VERSION "0.0.1"

NS_ :

BS_:

BU_: TCU BRK ESP MCU RDD GP TMS GW KPD1 RDE FNR ECU KPD2 ATSGO ACU IMU1 IMU2 IMU3 IMU4 IMU5 AGW PMI HDOQS EGOQS OBC EEC CBSW EJRH EJLH EPDLT EPDL2 EPDLR EPDLA TRBDZ ECU1 CLST LC510 EGDL JS SMB KPAC ACCU Audio TGU RDRR RDLH RDRH AVM CHMSL CTC SMK MC3D EVC MCU2

BO_ 2566893620 SMK_SMKC: 9 SMK
 SG_ SmkId : 35|32@1+ (1,0) [0|999999999] "" Vector__XXX
 SG_ SoftwareVer : 24|8@1+ (0.01,0) [0|255] "Ver" Vector__XXX
 SG_ FobImmobilizerWrn : 22|2@1+ (1,0) [0|3] "" Vector__XXX
 SG_ FobLowBatWrn : 20|2@1+ (1,0) [0|3] "" Vector__XXX
 SG_ NoDttFobInsideCabinWrn : 18|2@1+ (1,0) [0|3] "" Vector__XXX
 SG_ FobRgstId : 14|4@1+ (1,0) [0|15] "EA" Vector__XXX
 SG_ FobRgstFdbk : 12|2@1+ (1,0) [0|3] "" Vector__XXX
 SG_ PreheatSt : 10|2@1+ (1,0) [0|3] "" Vector__XXX
 SG_ AppLmpSt : 8|2@1+ (1,0) [0|3] "" Vector__XXX
 SG_ VentilationTmp : 4|4@1+ (1,0) [0|15] "�C" Vector__XXX
 SG_ VentilationSt : 2|2@1+ (1,0) [0|3] "" Vector__XXX
 SG_ DoorLckSt : 0|2@1+ (1,0) [0|3] "" Vector__XXX

BO_ 2566893876 SMK_SMKFOB: 8 SMK

BO_ 2566894154 TMS_TMSSMKD: 8 TMS

BO_ 2566894388 SMK_SMKI: 9 SMK
 SG_ DeicerSt : 44|2@1+ (1,0) [0|3] "" Vector__XXX
 SG_ ForcedEgStopCmd : 42|2@1+ (1,0) [0|3] "" Vector__XXX
 SG_ RmRunningSt : 40|2@1+ (1,0) [0|3] "" Vector__XXX
 SG_ MaintenanceDoorSt : 38|2@1+ (1,0) [0|3] "" Vector__XXX
 SG_ CabinDoorSt : 36|2@1+ (1,0) [0|3] "" Vector__XXX
 SG_ FobBatSt : 28|8@1+ (0.1,0) [0|25] "V" Vector__XXX
 SG_ MchTonage : 8|16@1+ (0.1,0) [0|6502.3] "" Vector__XXX
 SG_ MchModel : 48|8@1+ (1,0) [0|255] "" Vector__XXX
 SG_ FobDtt : 2|1@1+ (1,0) [0|1] "" Vector__XXX
 SG_ KeyStChange : 0|2@1+ (1,0) [0|3] "" Vector__XXX

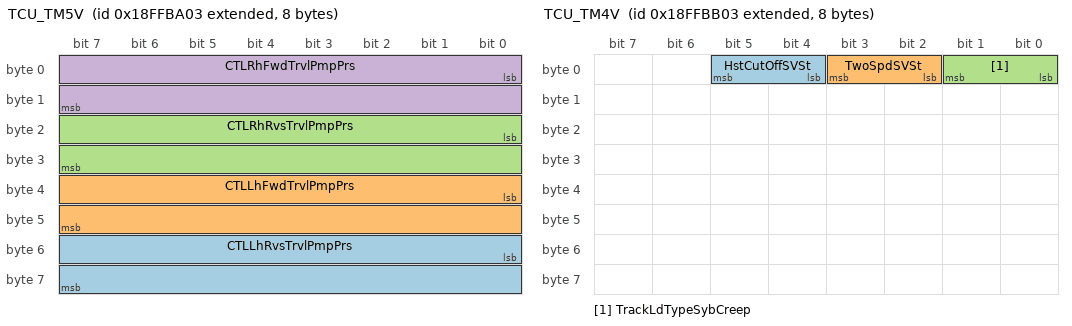
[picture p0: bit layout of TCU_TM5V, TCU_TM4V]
BO_ 2566896131 TCU_TM5V: 8 TCU
 SG_ CTLLhRvsTrvlPmpPrs : 48|16@1+ (0.0625,0) [0|500] "bar" Vector__XXX
 SG_ CTLLhFwdTrvlPmpPrs : 32|16@1+ (0.0625,0) [0|500] "bar" Vector__XXX
 SG_ CTLRhRvsTrvlPmpPrs : 16|16@1+ (0.0625,0) [0|500] "bar" Vector__XXX
 SG_ CTLRhFwdTrvlPmpPrs : 0|16@1+ (0.0625,0) [0|500] "bar" Vector__XXX

BO_ 2566896387 TCU_TM4V: 8 TCU
 SG_ HstCutOffSVSt : 4|2@1+ (1,0) [0|3] "" Vector__XXX
 SG_ TwoSpdSVSt : 2|2@1+ (1,0) [0|3] "" Vector__XXX
 SG_ TrackLdTypeSybCreep : 0|2@1+ (1,0) [0|3] "" Vector__XXX

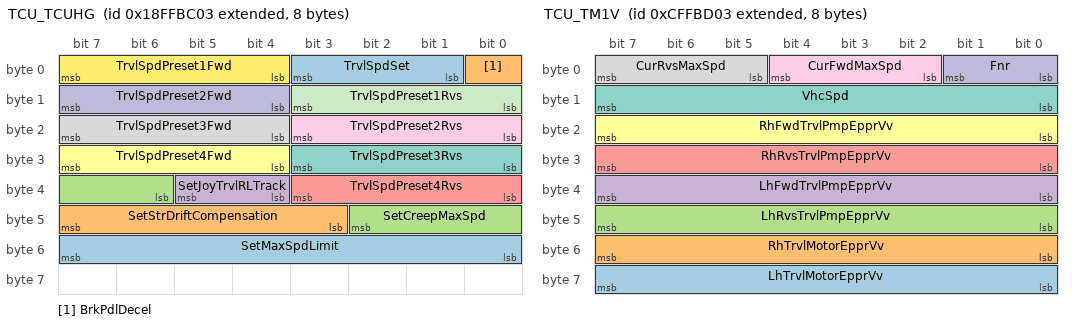
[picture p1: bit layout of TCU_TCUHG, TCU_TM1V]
BO_ 2566896643 TCU_TCUHG: 8 TCU
 SG_ SetMaxSpdLimit : 48|8@1+ (1,0) [0|250] "" Vector__XXX
 SG_ SetStrDriftCompensation : 43|5@1+ (1,0) [0|31] "" Vector__XXX
 SG_ SetCreepMaxSpd : 38|5@1+ (1,0) [0|31] "" Vector__XXX
 SG_ SetJoyTrvlRLTrack : 36|2@1+ (1,0) [0|3] "" Vector__XXX
 SG_ TrvlSpdPreset4Rvs : 32|4@1+ (1,0) [0|15] "" Vector__XXX
 SG_ TrvlSpdPreset4Fwd : 28|4@1+ (1,0) [0|15] "" Vector__XXX
 SG_ TrvlSpdPreset3Rvs : 24|4@1+ (1,0) [0|15] "" Vector__XXX
 SG_ TrvlSpdPreset3Fwd : 20|4@1+ (1,0) [0|15] "" Vector__XXX
 SG_ TrvlSpdPreset2Rvs : 16|4@1+ (1,0) [0|15] "" Vector__XXX
 SG_ TrvlSpdPreset2Fwd : 12|4@1+ (1,0) [0|15] "" Vector__XXX
 SG_ TrvlSpdPreset1Rvs : 8|4@1+ (1,0) [0|15] "" Vector__XXX
 SG_ TrvlSpdPreset1Fwd : 4|4@1+ (1,0) [0|15] "" Vector__XXX
 SG_ TrvlSpdSet : 1|3@1+ (1,0) [0|7] "" Vector__XXX
 SG_ BrkPdlDecel : 0|1@1+ (1,0) [0|1] "" Vector__XXX

BO_ 2365570307 TCU_TM1V: 8 TCU
 SG_ LhTrvlMotorEpprVv : 56|8@1+ (5,0) [0|1250] "mA" Vector__XXX
 SG_ RhTrvlMotorEpprVv : 48|8@1+ (5,0) [0|1250] "mA" Vector__XXX
 SG_ LhRvsTrvlPmpEpprVv : 40|8@1+ (5,0) [0|1250] "mA" Vector__XXX
 SG_ LhFwdTrvlPmpEpprVv : 32|8@1+ (5,0) [0|1250] "mA" Vector__XXX
 SG_ RhRvsTrvlPmpEpprVv : 24|8@1+ (5,0) [0|1250] "mA" Vector__XXX
 SG_ RhFwdTrvlPmpEpprVv : 16|8@1+ (5,0) [0|1250] "mA" Vector__XXX
 SG_ VhcSpd : 8|8@1+ (0.125,0) [0|31.25] "km/h" Vector__XXX
 SG_ CurRvsMaxSpd : 5|3@1+ (1,0) [0|7] "" Vector__XXX
 SG_ CurFwdMaxSpd : 2|3@1+ (1,0) [0|7] "" Vector__XXX
 SG_ Fnr : 0|2@1+ (1,0) [0|3] "" Vector__XXX

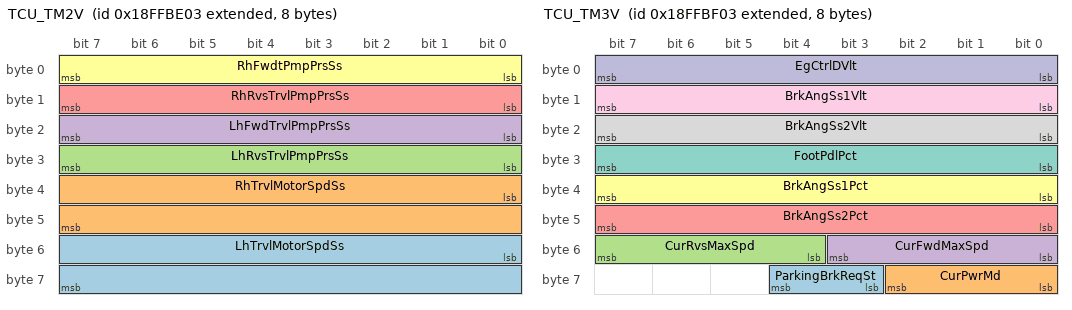
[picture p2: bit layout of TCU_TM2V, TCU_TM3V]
BO_ 2566897155 TCU_TM2V: 8 TCU
 SG_ LhTrvlMotorSpdSs : 48|16@1+ (0.0078125,0) [0|501.9921875] "Hz" Vector__XXX
 SG_ RhTrvlMotorSpdSs : 32|16@1+ (0.0078125,0) [0|501.9921875] "Hz" Vector__XXX
 SG_ LhRvsTrvlPmpPrsSs : 24|8@1+ (0.025,0) [0|6.25] "V" Vector__XXX
 SG_ LhFwdTrvlPmpPrsSs : 16|8@1+ (0.025,0) [0|6.25] "V" Vector__XXX
 SG_ RhRvsTrvlPmpPrsSs : 8|8@1+ (0.025,0) [0|6.25] "V" Vector__XXX
 SG_ RhFwdtPmpPrsSs : 0|8@1+ (0.025,0) [0|6.25] "V" Vector__XXX

BO_ 2566897411 TCU_TM3V: 8 TCU
 SG_ ParkingBrkReqSt : 59|2@1+ (1,0) [0|3] "" Vector__XXX
 SG_ CurPwrMd : 56|3@1+ (1,0) [0|7] "" Vector__XXX
 SG_ CurRvsMaxSpd : 52|4@1+ (1,0) [0|15] "" Vector__XXX
 SG_ CurFwdMaxSpd : 48|4@1+ (1,0) [0|15] "" Vector__XXX
 SG_ BrkAngSs2Pct : 40|8@1+ (0.4,0) [0|100] "%" Vector__XXX
 SG_ BrkAngSs1Pct : 32|8@1+ (0.4,0) [0|100] "%" Vector__XXX
 SG_ FootPdlPct : 24|8@1+ (0.4,0) [0|100] "%" Vector__XXX
 SG_ BrkAngSs2Vlt : 16|8@1+ (0.025,0) [0|6.25] "V" Vector__XXX
 SG_ BrkAngSs1Vlt : 8|8@1+ (0.025,0) [0|6.25] "V" Vector__XXX
 SG_ EgCtrlDVlt : 0|8@1+ (0.025,0) [0|6.25] "V" Vector__XXX

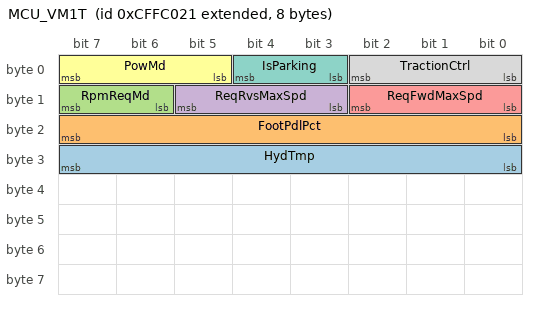
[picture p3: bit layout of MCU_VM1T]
BO_ 2365571105 MCU_VM1T: 8 MCU
 SG_ HydTmp : 24|8@1+ (1,-40) [-40|210] "�C" Vector__XXX
 SG_ FootPdlPct : 16|8@1+ (0.4,0) [0|100] "%" Vector__XXX
 SG_ RpmReqMd : 14|2@1+ (1,0) [0|3] "" Vector__XXX
 SG_ ReqRvsMaxSpd : 11|3@1+ (1,0) [0|7] "" Vector__XXX
 SG_ ReqFwdMaxSpd : 8|3@1+ (1,0) [0|7] "" Vector__XXX
 SG_ PowMd : 5|3@1+ (1,0) [0|7] "" Vector__XXX
 SG_ IsParking : 3|2@1+ (1,0) [0|3] "" Vector__XXX
 SG_ TractionCtrl : 0|3@1+ (1,0) [0|7] "" Vector__XXX

BO_ 2365571361 MCU_VM2T: 8 MCU

BO_ 2365572608 ECU_VGTPosCmd: 8 ECU
 SG_ VgtCmdSt : 16|8@1+ (1,0) [0|26] "" Vector__XXX
 SG_ VgtNzPos : 0|16@1+ (0.1,0) [0|100] "" Vector__XXX

BO_ 2566901763 TCU_HSDI: 250 TCU
 SG_ RandomVal : 0|16@1+ (1,0) [0|65535] "" Vector__XXX

BO_ 2566901793 MCU_HSDI: 250 MCU
 SG_ RandomVal : 0|16@1+ (1,0) [0|65535] "" Vector__XXX

BO_ 2566901936 MC3D_HSDI: 250 MC3D
 SG_ RandomVal : 0|16@1+ (1,0) [0|65535] "" Vector__XXX

BO_ 2566902049 MCU_FSDI: 94 MCU
 SG_ OptSetCdsRvsFanAutoPrd : 744|8@1+ (1,0) [0|250] "min" Vector__XXX
 SG_ OptSetTrailer : 742|1@1+ (1,0) [0|1] "" Vector__XXX
 SG_ OptSetEscortWrkLmp : 741|1@1+ (1,0) [0|1] "" Vector__XXX
 SG_ OptSetCdsRvsFanMd : 732|1@1+ (1,0) [0|1] "" Vector__XXX
 SG_ OptSetRttDir : 731|1@1+ (1,0) [0|1] "" Vector__XXX
 SG_ OptSetAdvLv : 730|1@1+ (1,0) [0|1] "" Vector__XXX
 SG_ OptSetGndSaw : 729|1@1+ (1,0) [0|1] "" Vector__XXX
 SG_ OptSetTpms : 728|1@1+ (1,0) [0|1] "" Vector__XXX
 SG_ OptSetAutoBrkrSens : 720|8@1+ (1,0) [0|255] "" Vector__XXX
 SG_ OptSetAntiBlankFire : 719|1@1+ (1,0) [0|1] "" Vector__XXX
 SG_ OptSetJoyBoom : 717|2@1+ (1,0) [0|3] "" Vector__XXX
 SG_ OptSetJoyTilt : 715|2@1+ (1,0) [0|3] "" Vector__XXX
 SG_ OptSetRvsFanDurTm : 709|6@1+ (1,0) [0|63] "" Vector__XXX
 SG_ OptSetHhFw : 708|1@1+ (1,0) [0|1] "" Vector__XXX
 SG_ OptSet3DMgMc3rd : 704|4@1+ (1,0) [0|15] "" Vector__XXX
 SG_ OptSetRrCabLmp : 703|1@1+ (1,0) [0|1] "" Vector__XXX
 SG_ OptSetDzMc : 700|3@1+ (1,0) [0|7] "" Vector__XXX
 SG_ OptSetTrqCvtLckUp : 699|1@1+ (1,0) [0|1] "" Vector__XXX
 SG_ OptSetTwThmbWhlDir : 698|1@1+ (1,0) [0|1] "" Vector__XXX
 SG_ OptSetOptPdlType2 : 696|2@1+ (1,0) [0|3] "" Vector__XXX
 SG_ OptSetMaxTrvlSpd : 688|8@1+ (1,0) [0|250] "km/h" Vector__XXX
 SG_ OptSetRollSlope : 672|16@1+ (1,-125) [-125|125] "%" Vector__XXX
 SG_ OptSetDaac : 671|1@1+ (1,0) [0|1] "" Vector__XXX
 SG_ OptSetRvsLmpFuncAct : 670|1@1+ (1,0) [0|1] "" Vector__XXX
 SG_ OptSetBladeAngSens : 668|2@1+ (1,0) [0|3] "" Vector__XXX
 SG_ OptSetRaiseDnSens : 666|2@1+ (1,0) [0|3] "" Vector__XXX
 SG_ OptSetBladeTiltSens : 664|2@1+ (1,0) [0|3] "" Vector__XXX
 SG_ OptSetPchSlope : 648|16@1+ (0.01,-321.27) [-321.27|321.28] "%" Vector__XXX
 SG_ OptSetMrrHt : 647|1@1+ (1,0) [0|1] "" Vector__XXX
 SG_ OptSetQckCoolMd : 646|1@1+ (1,0) [0|1] "" Vector__XXX
 SG_ RttOptSet : 644|2@1+ (1,0) [0|3] "" Vector__XXX
 SG_ OptSetTrvlStrgtPdl : 643|1@1+ (1,0) [0|1] "" Vector__XXX
 SG_ OptSetJoyType : 640|3@1+ (1,0) [0|7] "" Vector__XXX
 SG_ OptSetAttCtrl : 638|2@1+ (1,0) [0|3] "" Vector__XXX
 SG_ OptSetTiltRttType : 635|3@1+ (1,0) [0|7] "" Vector__XXX
 SG_ OptSetArtiBoom : 634|1@1+ (1,0) [0|1] "" Vector__XXX
 SG_ OptSetDzBlade : 633|1@1+ (1,0) [0|1] "" Vector__XXX
 SG_ OptSetHhLift : 632|1@1+ (1,0) [0|1] "" Vector__XXX
 SG_ OptSetJoyPtnChange : 629|3@1+ (1,0) [0|7] "" Vector__XXX
 SG_ OptSetTrqCvtLookUp : 628|1@1+ (1,0) [0|1] "" Vector__XXX
 SG_ OptSetDhlAuto : 627|1@1+ (1,0) [0|1] "" Vector__XXX
 SG_ OptSet3DMG : 626|1@1+ (1,0) [0|1] "" Vector__XXX
 SG_ OptSetTrvlSwgAlm : 624|2@1+ (1,0) [0|3] "" Vector__XXX
 SG_ OptSetPrsCtrl : 600|1@1+ (1,0) [0|1] "" Vector__XXX
 SG_ OptSetRollOvr : 599|1@1+ (1,0) [0|1] "" Vector__XXX
 SG_ OptSet4WhlStr : 598|1@1+ (1,0) [0|1] "" Vector__XXX
 SG_ OptSetSpool4 : 597|1@1+ (1,0) [0|1] "" Vector__XXX
 SG_ OptSetConstFw : 596|1@1+ (1,0) [0|1] "" Vector__XXX
 SG_ OptSetConstFwStep : 592|4@1+ (1,0) [0|15] "" Vector__XXX
 SG_ OptSetLisRvsOprSpd : 584|8@1+ (1,0) [0|250] "km/h" Vector__XXX
 SG_ OptSetFrCabLmp : 583|1@1+ (1,0) [0|1] "" Vector__XXX
 SG_ OptSetOutRr : 582|1@1+ (1,0) [0|1] "" Vector__XXX
 SG_ OptSetOutRlRrDz : 581|1@1+ (1,0) [0|1] "" Vector__XXX
 SG_ OptSetOutFr : 580|1@1+ (1,0) [0|1] "" Vector__XXX
 SG_ OptSetOutFlFrDz : 579|1@1+ (1,0) [0|1] "" Vector__XXX
 SG_ OptSetJoyStr : 578|1@1+ (1,0) [0|1] "" Vector__XXX
 SG_ OptSetRvsTrvlSpdLmt : 577|1@1+ (1,0) [0|1] "" Vector__XXX
 SG_ OptSetEmcvBoomDnImpactPrevent : 576|1@1+ (1,0) [0|1] "" Vector__XXX
 SG_ OptSetEmcvBoomUpImpactPrevent : 575|1@1+ (1,0) [0|1] "" Vector__XXX
 SG_ OptSetEmcvBckDumpImpactPrevent : 574|1@1+ (1,0) [0|1] "" Vector__XXX
 SG_ OptSetEmcvBckCrowdImpactPrevent : 573|1@1+ (1,0) [0|1] "" Vector__XXX
 SG_ OptSetEmcvBckSens : 572|1@1+ (1,0) [0|1] "" Vector__XXX
 SG_ OptSetEmcvBoomSens : 571|1@1+ (1,0) [0|1] "" Vector__XXX
 SG_ OptSetEstrJoySens : 569|2@1+ (1,0) [0|3] "" Vector__XXX
 SG_ OptSetWrkLis : 568|1@1+ (1,0) [0|1] "" Vector__XXX
 SG_ OptSetLcInVal : 552|16@1+ (0.1,0) [0|6425.5] "mm" Vector__XXX
 SG_ OptSetR2InVal : 536|16@1+ (0.1,0) [0|6425.5] "mm" Vector__XXX
 SG_ OptSetR1InVal : 520|16@1+ (0.1,0) [0|6425.5] "mm" Vector__XXX
 SG_ OptSetBckWghInVlue : 504|16@1+ (0.1,0) [0|6425.5] "kg" Vector__XXX
 SG_ OptSetBoomWghInVal : 488|16@1+ (0.1,0) [0|6425.5] "kg" Vector__XXX
 SG_ OptSetMaxCritWghVal : 472|16@1+ (0.5,0) [0|32127.5] "kg" Vector__XXX
 SG_ OptSetHalfCritWghVal : 456|16@1+ (0.5,0) [0|32127.5] "kg" Vector__XXX
 SG_ OptSetElecStr : 455|1@1+ (1,0) [0|1] "" Vector__XXX
 SG_ OptSetRvsFan : 454|1@1+ (1,0) [0|1] "" Vector__XXX
 SG_ OptSetRcw : 453|1@1+ (1,0) [0|1] "" Vector__XXX
 SG_ OptSetQckCoupler : 452|1@1+ (1,0) [0|1] "" Vector__XXX
 SG_ OptSetTrvlOrSwgAlm : 451|1@1+ (1,0) [0|1] "" Vector__XXX
 SG_ OptSetSmk : 450|1@1+ (1,0) [0|1] "" Vector__XXX
 SG_ OptSetOwd : 449|1@1+ (1,0) [0|1] "" Vector__XXX
 SG_ OptSetMchNameInit : 448|1@1+ (1,0) [0|250] "" Vector__XXX
 SG_ OptSetEmvcPmcv : 447|1@1+ (1,0) [0|1] "" Vector__XXX
 SG_ OptSetAebReq : 446|1@1+ (1,0) [0|1] "" Vector__XXX
 SG_ OptSetRvsFanOn : 445|1@1+ (1,0) [0|1] "" Vector__XXX
 SG_ OptSetRvsFanMd : 444|1@1+ (1,0) [0|1] "" Vector__XXX
 SG_ OptSetWhg : 443|1@1+ (1,0) [0|1] "" Vector__XXX
 SG_ OptSetHydrostatCalbCmd : 442|1@1+ (1,0) [0|1] "" Vector__XXX
 SG_ OptSetClutchCalbCmd : 441|1@1+ (1,0) [0|1] "" Vector__XXX
 SG_ OptSetEmgMd : 440|1@1+ (1,0) [0|1] "" Vector__XXX
 SG_ OptSetCreepAct : 439|1@1+ (1,0) [0|1] "" Vector__XXX
 SG_ OptSetThmbWhl : 438|1@1+ (1,0) [0|1] "" Vector__XXX
 SG_ OptSetAxleOilCool : 437|1@1+ (1,0) [0|1] "" Vector__XXX
 SG_ OptSetAngSs : 434|3@1+ (1,0) [0|7] "" Vector__XXX
 SG_ OptSetBrkPdlCalb : 432|2@1+ (1,0) [0|3] "" Vector__XXX
 SG_ OptSetCreepGr : 424|8@1+ (1,0) [0|250] "" Vector__XXX
 SG_ OptSetLisOprSpd : 416|8@1+ (1,0) [0|250] "km/h" Vector__XXX
 SG_ OptSetRvsFanTm : 408|8@1+ (1,0) [0|250] "min" Vector__XXX
 SG_ OptSetLis : 407|1@1+ (1,0) [0|1] "" Vector__XXX
 SG_ OptSetEmgStr : 406|1@1+ (1,0) [0|1] "" Vector__XXX
 SG_ OptSetDhl : 405|1@1+ (1,0) [0|1] "" Vector__XXX
 SG_ OptSetFnr2LeverType : 403|2@1+ (1,0) [0|3] "" Vector__XXX
 SG_ OptSetTrmsLmtGr : 400|3@1+ (1,0) [0|7] "" Vector__XXX
 SG_ OptSetTransBck : 399|1@1+ (1,0) [0|1] "" Vector__XXX
 SG_ OptSetItgtFltBoom : 398|1@1+ (1,0) [0|1] "" Vector__XXX
 SG_ OptSetBeacon : 397|1@1+ (1,0) [0|1] "" Vector__XXX
 SG_ OptSetMultiFuncBtnSel : 393|4@1+ (1,0) [0|15] "" Vector__XXX
 SG_ OptSetAutoIdle : 392|1@1+ (1,0) [0|1] "" Vector__XXX
 SG_ MachineName : 304|88@1+ (1,0) [0|255] "" Vector__XXX
 SG_ AutoIdleTm : 288|16@1+ (1,0) [0|64255] "s" Vector__XXX
 SG_ BrkrOprTm : 272|16@1+ (1,0) [0|64255] "s" Vector__XXX
 SG_ OptSetAutoShutOffTm : 264|8@1+ (1,0) [0|250] "min" Vector__XXX
 SG_ OptSetAutoShutOff : 263|1@1+ (1,0) [0|1] "" Vector__XXX
 SG_ OptSetAutoShutOffCancel : 262|1@1+ (1,0) [0|1] "" Vector__XXX
 SG_ OptSetAutoIdleRpmTmp : 261|1@1+ (1,0) [0|1] "" Vector__XXX
 SG_ OptSetSpc : 260|1@1+ (1,0) [0|1] "" Vector__XXX
 SG_ OptSetVoiceWrnCmd : 259|1@1+ (1,0) [0|1] "" Vector__XXX
 SG_ OptSetBoomSwgUSe : 258|1@1+ (1,0) [0|1] "" Vector__XXX
 SG_ OptSetTrvl2PmpCmbRls : 257|1@1+ (1,0) [0|1] "" Vector__XXX
 SG_ OptSetTrvl1PmpUse : 256|1@1+ (1,0) [0|1] "" Vector__XXX
 SG_ OptSetTrmsMaxSpdLmtChk : 255|1@1+ (1,0) [0|1] "" Vector__XXX
 SG_ OptSetHhAlt : 254|1@1+ (1,0) [0|1] "" Vector__XXX
 SG_ OptSetRipperOpt : 253|1@1+ (1,0) [0|1] "" Vector__XXX
 SG_ OptSetRttOpt : 252|1@1+ (1,0) [0|1] "" Vector__XXX
 SG_ OptSetJoyThmbWhlRtt : 250|2@1+ (1,0) [0|3] "" Vector__XXX
 SG_ OptSetJoyThmbWhlTw : 248|2@1+ (1,0) [0|3] "" Vector__XXX
 SG_ OptSetTw : 246|2@1+ (1,0) [0|3] "" Vector__XXX
 SG_ OptSetOptPdl : 245|1@1+ (1,0) [0|1] "" Vector__XXX
 SG_ OptSetAttPdlJoySel : 243|2@1+ (1,0) [0|3] "" Vector__XXX
 SG_ OptSet2Pmp : 242|1@1+ (1,0) [0|1] "" Vector__XXX
 SG_ OptSetAttTw : 241|1@1+ (1,0) [0|1] "" Vector__XXX
 SG_ OptSetAttBrkr : 240|1@1+ (1,0) [0|1] "" Vector__XXX
 SG_ OptSetKeylessUse : 191|1@1+ (1,0) [0|1] "" Vector__XXX
 SG_ OptSetKeyless : 190|1@1+ (1,0) [0|1] "" Vector__XXX
 SG_ OptSetWiper : 189|1@1+ (1,0) [0|1] "" Vector__XXX
 SG_ OptSetTrvlMotOvrHtWrn : 188|1@1+ (1,0) [0|1] "" Vector__XXX
 SG_ OptSetFnrDefault : 187|1@1+ (1,0) [0|1] "" Vector__XXX
 SG_ OptSetFnrSel : 186|1@1+ (1,0) [0|1] "" Vector__XXX
 SG_ OptSetCanTypeCmbSw : 185|1@1+ (1,0) [0|1] "" Vector__XXX
 SG_ UserDtIdx : 176|8@1+ (1,0) [0|255] "" Vector__XXX
 SG_ VhcSerialNo : 120|56@1+ (1,0) [0|255] "" Vector__XXX
 SG_ OptSetAttWghFactor : 100|4@1+ (1,0) [0|15] "" Vector__XXX
 SG_ OptSetCanTypeFuelSs : 99|1@1+ (1,0) [0|1] "" Vector__XXX
 SG_ OptSetSubBrkLmp : 98|1@1+ (1,0) [0|1] "" Vector__XXX
 SG_ TiltRttMd : 97|1@1+ (1,0) [0|1] "" Vector__XXX
 SG_ USerLckUnlockSt : 96|1@1+ (1,0) [0|1] "" Vector__XXX
 SG_ UserPw : 64|32@1+ (1,0) [0|255] "" Vector__XXX
 SG_ OptWgh : 63|1@1+ (1,0) [0|1] "" Vector__XXX
 SG_ OptMC : 62|1@1+ (1,0) [0|1] "" Vector__XXX
 SG_ OptEgPostHtAct : 61|1@1+ (1,0) [0|1] "" Vector__XXX
 SG_ Opt2DMG : 60|1@1+ (1,0) [0|1] "" Vector__XXX
 SG_ AdminUse2 : 56|3@1+ (1,0) [0|7] "" Vector__XXX
 SG_ AdminUse1 : 48|3@1+ (1,0) [0|7] "" Vector__XXX
 SG_ AdminUse0 : 40|3@1+ (1,0) [0|7] "" Vector__XXX
 SG_ OwnerPw0UpTm : 33|2@1+ (1,0) [0|3] "" Vector__XXX
 SG_ OwnerPw0Use : 32|1@1+ (1,0) [0|1] "" Vector__XXX
 SG_ OwnerPw0 : 0|32@1+ (1,0) [0|255] "" Vector__XXX

BO_ 2566902305 MCU_FOUHI: 104 MCU
 SG_ PmpDrvAirCtrgHr : 800|32@1+ (1,0) [0|4294967295] "min" Vector__XXX
 SG_ PmpDrvOilHr : 768|32@1+ (1,0) [0|4294967295] "min" Vector__XXX
 SG_ HstFiltHr : 736|32@1+ (1,0) [0|4294967295] "min" Vector__XXX
 SG_ AxleOilFiltHr : 704|32@1+ (1,0) [0|4294967295] "min" Vector__XXX
 SG_ AtsSparkPlugHr : 672|32@1+ (1,0) [0|4294967295] "min" Vector__XXX
 SG_ EgCrkcaseBreatherElementHr : 640|32@1+ (1,0) [0|4294967295] "min" Vector__XXX
 SG_ AirCndFiltInHr : 608|32@1+ (1,0) [0|4294967295] "min" Vector__XXX
 SG_ AirCndFiltOutHr : 576|32@1+ (1,0) [0|4294967295] "min" Vector__XXX
 SG_ EgOilCtrCleanerFiltHr : 544|32@1+ (1,0) [0|4294967295] "min" Vector__XXX
 SG_ DefBreatherFiltHr : 512|32@1+ (1,0) [0|4294967295] "min" Vector__XXX
 SG_ DefFiltHr : 480|32@1+ (1,0) [0|4294967295] "min" Vector__XXX
 SG_ OilBathPrecleanerHr : 448|32@1+ (1,0) [0|4294967295] "min" Vector__XXX
 SG_ DefHr : 416|32@1+ (1,0) [0|4294967295] "min" Vector__XXX
 SG_ AxleOilHr : 384|32@1+ (1,0) [0|4294967295] "min" Vector__XXX
 SG_ TrmsOilFiltHr : 352|32@1+ (1,0) [0|4294967295] "min" Vector__XXX
 SG_ TrmsOilHr : 320|32@1+ (1,0) [0|4294967295] "min" Vector__XXX
 SG_ BreatherOilSepFiltHr : 288|32@1+ (1,0) [0|4294967295] "min" Vector__XXX
 SG_ DpfHr : 256|32@1+ (1,0) [0|4294967295] "min" Vector__XXX
 SG_ CoolHr : 224|32@1+ (1,0) [0|4294967295] "min" Vector__XXX
 SG_ HydOilHr : 192|32@1+ (1,0) [0|4294967295] "min" Vector__XXX
 SG_ EgOilHr : 160|32@1+ (1,0) [0|4294967295] "min" Vector__XXX
 SG_ PilotFiltHr : 128|32@1+ (1,0) [0|4294967295] "min" Vector__XXX
 SG_ RetFiltHr : 96|32@1+ (1,0) [0|4294967295] "min" Vector__XXX
 SG_ EgOilFiltHr : 64|32@1+ (1,0) [0|4294967295] "min" Vector__XXX
 SG_ AirCleanerHr : 32|32@1+ (1,0) [0|4294967295] "min" Vector__XXX
 SG_ FuleFiltHr : 0|32@1+ (1,0) [0|4294967295] "min" Vector__XXX

BO_ 2566902561 MCU_FOCPHI: 52 MCU
 SG_ PmpDrvAirCtrgPrd : 400|16@1+ (1,0) [0|64255] "h" Vector__XXX
 SG_ PmpDrvOilPrd : 384|16@1+ (1,0) [0|64255] "h" Vector__XXX
 SG_ HstFiltPrd : 368|16@1+ (1,0) [0|64255] "h" Vector__XXX
 SG_ AxleOilFiltPrd : 352|16@1+ (1,0) [0|64255] "h" Vector__XXX
 SG_ AtsSparkPlugPrd : 336|16@1+ (1,0) [0|64255] "h" Vector__XXX
 SG_ EgCrkcaseBreatherElementPrd : 320|16@1+ (1,0) [0|64255] "h" Vector__XXX
 SG_ AirCndFiltInPrd : 304|16@1+ (1,0) [0|64255] "h" Vector__XXX
 SG_ AirCndFiltOutPrd : 288|16@1+ (1,0) [0|64255] "h" Vector__XXX
 SG_ EgOilCtrCleanerFiltPrd : 272|16@1+ (1,0) [0|64255] "h" Vector__XXX
 SG_ DefBreatherFiltPrd : 256|16@1+ (1,0) [0|64255] "h" Vector__XXX
 SG_ DefFiltPrd : 240|16@1+ (1,0) [0|64255] "h" Vector__XXX
 SG_ OilBathPrecleanerPrd : 224|16@1+ (1,0) [0|64255] "h" Vector__XXX
 SG_ DefPrd : 208|16@1+ (1,0) [0|64255] "h" Vector__XXX
 SG_ AxleOilPrd : 192|16@1+ (1,0) [0|64255] "h" Vector__XXX
 SG_ TrmsOilFiltPrd : 176|16@1+ (1,0) [0|64255] "h" Vector__XXX
 SG_ TrmsOilPrd : 160|16@1+ (1,0) [0|64255] "h" Vector__XXX
 SG_ BreatherOilSepFiltPrd : 144|16@1+ (1,0) [0|64255] "h" Vector__XXX
 SG_ DpfPrd : 128|16@1+ (1,0) [0|64255] "h" Vector__XXX
 SG_ CoolPrd : 112|16@1+ (1,0) [0|64255] "h" Vector__XXX
 SG_ HydOilPrd : 96|16@1+ (1,0) [0|64255] "h" Vector__XXX
 SG_ EgOilPrd : 80|16@1+ (1,0) [0|64255] "h" Vector__XXX
 SG_ PilotFiltPrd : 64|16@1+ (1,0) [0|64255] "h" Vector__XXX
 SG_ RetFiltPrd : 48|16@1+ (1,0) [0|64255] "h" Vector__XXX
 SG_ EgOilFiltPrd : 32|16@1+ (1,0) [0|64255] "h" Vector__XXX
 SG_ AirCleanerPrd : 16|16@1+ (1,0) [0|64255] "h" Vector__XXX
 SG_ FuleFiltPrd : 0|16@1+ (1,0) [0|64255] "h" Vector__XXX

BO_ 2566902817 MCU_XASI: 136 MCU
 SG_ BladeFanPchSsVlt : 1072|16@1+ (0.001,0) [0|64.255] "V" Vector__XXX
 SG_ RamLckPrs : 1056|16@1+ (0.0625,0) [0|500] "bar" Vector__XXX
 SG_ TrailerDnPilotPrs : 1040|16@1+ (0.00390625,0) [0|50] "bar" Vector__XXX
 SG_ BoomHead2Prs : 1024|16@1+ (0.0625,0) [0|500] "bar" Vector__XXX
 SG_ ArmRodPrs : 1008|16@1+ (0.0625,0) [0|500] "bar" Vector__XXX
 SG_ ArmHEadPrs : 992|16@1+ (0.0625,0) [0|500] "bar" Vector__XXX
 SG_ BoodRodPrs : 976|16@1+ (0.0625,0) [0|500] "bar" Vector__XXX
 SG_ BoomHeadPrs : 960|16@1+ (0.0625,0) [0|500] "bar" Vector__XXX
 SG_ TpsVlt : 912|16@1+ (0.001,0) [0|64.255] "V" Vector__XXX
 SG_ PchAng : 896|16@1+ (1,0) [0|65535] "" Vector__XXX
 SG_ RoolAng : 880|16@1+ (1,0) [0|65535] "" Vector__XXX
 SG_ TmsSecVlt : 864|16@1+ (0.001,0) [0|64.255] "V" Vector__XXX
 SG_ VhcTrvlSpdSsFreq : 848|16@1+ (1,0) [0|65000] "Hz" Vector__XXX
 SG_ FlwCtrlLeverRh : 800|16@1+ (0.001,0) [0|64.255] "V" Vector__XXX
 SG_ FlwCtrlLeverLh : 784|16@1+ (0.001,0) [0|64.255] "V" Vector__XXX
 SG_ FlwCtrlAddLeverLh : 768|16@1+ (0.001,0) [0|64.255] "V" Vector__XXX
 SG_ BatVlt : 736|16@1+ (0.001,0) [0|64.255] "V" Vector__XXX
 SG_ AltVlt : 720|16@1+ (0.001,0) [0|64.255] "V" Vector__XXX
 SG_ HydOilTmp : 656|16@1+ (1,-40) [-40|210] "�C" Vector__XXX
 SG_ MecaCoolTmp : 640|16@1+ (1,-40) [-40|210] "�C" Vector__XXX
 SG_ GndSawDnSsPrs : 624|16@1+ (0.00390625,0) [0|50] "bar" Vector__XXX
 SG_ GndSawUpSsPrs : 608|16@1+ (0.00390625,0) [0|50] "bar" Vector__XXX
 SG_ WifSsVlt : 592|16@1+ (0.001,0) [0|64.255] "V" Vector__XXX
 SG_ FuelLv : 576|16@1+ (1,0) [0|250] "%" Vector__XXX
 SG_ FuelLvAddFuelTnk : 560|16@1+ (16,0) [0|4000] "kPa" Vector__XXX
 SG_ AcpSsPrs : 544|16@1+ (16,0) [0|4000] "kPa" Vector__XXX
 SG_ AccPdlVlt : 528|16@1+ (0.001,0) [0|64.255] "V" Vector__XXX
 SG_ EgCtrlDialVlt : 512|16@1+ (0.001,0) [0|64.255] "V" Vector__XXX
 SG_ LsPrs : 496|16@1+ (0.0625,0) [0|500] "Bar" Vector__XXX
 SG_ P3NegaconPrs : 480|16@1+ (0.0625,0) [0|500] "Bar" Vector__XXX
 SG_ RrNegaconPrs : 464|16@1+ (0.0625,0) [0|500] "Bar" Vector__XXX
 SG_ FrNegaconPrs : 448|16@1+ (0.0625,0) [0|500] "Bar" Vector__XXX
 SG_ PilotTrvlPtPrs : 432|16@1+ (0.0625,0) [0|50] "Bar" Vector__XXX
 SG_ PilotWrkPaPrs : 416|16@1+ (0.0625,0) [0|50] "Bar" Vector__XXX
 SG_ ArmLckPrs : 400|16@1+ (0.00390625,0) [0|50] "bar" Vector__XXX
 SG_ BckCrowdConfPrs : 384|16@1+ (0.00390625,0) [0|50] "bar" Vector__XXX
 SG_ ArmCrowdConfPrs : 368|16@1+ (0.00390625,0) [0|50] "bar" Vector__XXX
 SG_ BoomUpConfPrs : 352|16@1+ (0.00390625,0) [0|50] "bar" Vector__XXX
 SG_ Opt3Prs : 336|16@1+ (0.00390625,0) [0|50] "bar" Vector__XXX
 SG_ Opt2Prs : 320|16@1+ (0.00390625,0) [0|50] "bar" Vector__XXX
 SG_ Opt1Prs : 304|16@1+ (0.00390625,0) [0|50] "bar" Vector__XXX
 SG_ SwgPrs : 288|16@1+ (0.00390625,0) [0|50] "bar" Vector__XXX
 SG_ TrvlLhPrs : 272|16@1+ (0.00390625,0) [0|50] "bar" Vector__XXX
 SG_ TrvlRhPrs : 256|16@1+ (0.00390625,0) [0|50] "bar" Vector__XXX
 SG_ BckDumpPrs : 240|16@1+ (0.00390625,0) [0|50] "bar" Vector__XXX
 SG_ BckCrowdPrs : 224|16@1+ (0.00390625,0) [0|50] "bar" Vector__XXX
 SG_ ArmOutPrs : 208|16@1+ (0.00390625,0) [0|50] "bar" Vector__XXX
 SG_ ArmInPrs : 192|16@1+ (0.00390625,0) [0|50] "bar" Vector__XXX
 SG_ BoomDnPrs : 176|16@1+ (0.00390625,0) [0|50] "bar" Vector__XXX
 SG_ BoomUpPrs : 160|16@1+ (0.00390625,0) [0|50] "bar" Vector__XXX
 SG_ EmgStrPrs : 144|16@1+ (0.0625,0) [0|500] "bar" Vector__XXX
 SG_ Pmp3Ang : 128|16@1+ (0.001,0) [0|64.255] "V" Vector__XXX
 SG_ RRpmpAng : 112|16@1+ (0.001,0) [0|64.255] "V" Vector__XXX
 SG_ FrPmpAng : 96|16@1+ (0.001,0) [0|64.255] "V" Vector__XXX
 SG_ FuelPrs : 80|16@1+ (0.00390625,0) [0|50] "bar" Vector__XXX
 SG_ RcwStpVvPrs : 64|16@1+ (0.0625,0) [0|500] "bar" Vector__XXX
 SG_ Pmp3Prs : 48|16@1+ (0.0625,0) [0|500] "bar" Vector__XXX
 SG_ BoomCylPrs : 32|16@1+ (0.0625,0) [0|500] "bar" Vector__XXX
 SG_ RrPmpPrs : 16|16@1+ (0.0625,0) [0|500] "bar" Vector__XXX
 SG_ FrPmpPrs : 0|16@1+ (0.0625,0) [0|500] "bar" Vector__XXX

BO_ 2566903073 MCU_XAAI: 84 MCU
 SG_ VariBladeFanEvc : 656|16@1+ (1,0) [0|2000] "mA" Vector__XXX
 SG_ BoomSwgCcwEvc : 640|16@1+ (1,0) [0|2000] "mA" Vector__XXX
 SG_ BoomSwgCwEvc : 624|16@1+ (1,0) [0|2000] "mA" Vector__XXX
 SG_ TrvlPmpEvc : 608|16@1+ (1,0) [0|2000] "mA" Vector__XXX
 SG_ Pmp3Evc : 592|16@1+ (1,0) [0|2000] "mA" Vector__XXX
 SG_ DzDnEvc : 576|16@1+ (1,0) [0|2000] "mA" Vector__XXX
 SG_ DzUpEvc : 560|16@1+ (1,0) [0|2000] "mA" Vector__XXX
 SG_ ArtiBoomDnEvc : 544|16@1+ (1,0) [0|2000] "mA" Vector__XXX
 SG_ ArtiBoomUpEvc : 528|16@1+ (1,0) [0|2000] "mA" Vector__XXX
 SG_ SwgLhEvc : 512|16@1+ (1,0) [0|2000] "mA" Vector__XXX
 SG_ SwgRhEvc : 496|16@1+ (1,0) [0|2000] "mA" Vector__XXX
 SG_ TrvlLhRvsEvc : 480|16@1+ (1,0) [0|2000] "mA" Vector__XXX
 SG_ TrvlLhFwdEvc : 464|16@1+ (1,0) [0|2000] "mA" Vector__XXX
 SG_ TrvlRhRvsEvc : 448|16@1+ (1,0) [0|2000] "mA" Vector__XXX
 SG_ TrvlRhFwdEvc : 432|16@1+ (1,0) [0|2000] "mA" Vector__XXX
 SG_ BckDumpEvc : 416|16@1+ (1,0) [0|2000] "mA" Vector__XXX
 SG_ BckCrowdEvc : 400|16@1+ (1,0) [0|2000] "mA" Vector__XXX
 SG_ Arm2DumpEvc : 384|16@1+ (1,0) [0|2000] "mA" Vector__XXX
 SG_ Arm2CrowdEvc : 368|16@1+ (1,0) [0|2000] "mA" Vector__XXX
 SG_ Arm1DumpEvc : 352|16@1+ (1,0) [0|2000] "mA" Vector__XXX
 SG_ Arm1CrowdEvc : 336|16@1+ (1,0) [0|2000] "mA" Vector__XXX
 SG_ Boom2UpEvc : 320|16@1+ (1,0) [0|2000] "mA" Vector__XXX
 SG_ Boom1DnEvc : 304|16@1+ (1,0) [0|2000] "mA" Vector__XXX
 SG_ Boom1UpEvc : 288|16@1+ (1,0) [0|2000] "mA" Vector__XXX
 SG_ ArmLckEvc : 272|16@1+ (1,0) [0|2000] "mA" Vector__XXX
 SG_ BckCrowdConfEvc : 256|16@1+ (1,0) [0|2000] "mA" Vector__XXX
 SG_ ArmCrowdConfEvc : 240|16@1+ (1,0) [0|2000] "mA" Vector__XXX
 SG_ BoomUpConfEvc : 224|16@1+ (1,0) [0|2000] "mA" Vector__XXX
 SG_ BypassCutOffBEvc : 208|16@1+ (1,0) [0|2000] "mA" Vector__XXX
 SG_ BypassCutOffAEvc : 192|16@1+ (1,0) [0|2000] "mA" Vector__XXX
 SG_ Trvl2PmpCmbEvc : 176|16@1+ (1,0) [0|2000] "mA" Vector__XXX
 SG_ TrvlFwdEvc : 160|16@1+ (1,0) [0|2000] "mA" Vector__XXX
 SG_ PrsCtrl2Evc : 144|16@1+ (1,0) [0|2000] "mA" Vector__XXX
 SG_ PrsCtrl1Evc : 128|16@1+ (1,0) [0|2000] "mA" Vector__XXX
 SG_ RttCcwEvc : 112|16@1+ (1,0) [0|2000] "mA" Vector__XXX
 SG_ RttCwEvc : 96|16@1+ (1,0) [0|2000] "mA" Vector__XXX
 SG_ TwCloseEvc : 80|16@1+ (1,0) [0|2000] "mA" Vector__XXX
 SG_ TwOpenEvc : 64|16@1+ (1,0) [0|2000] "mA" Vector__XXX
 SG_ FlwCtrlEvc : 48|16@1+ (1,0) [0|2000] "mA" Vector__XXX
 SG_ CoolFanEvc : 32|16@1+ (1,0) [0|2000] "mA" Vector__XXX
 SG_ PmpElecEvc : 16|16@1+ (1,0) [0|2000] "mA" Vector__XXX
 SG_ Pmp1Evc : 0|16@1+ (1,0) [0|2000] "mA" Vector__XXX

BO_ 2566903329 MCU_XDSI: 24 MCU
 SG_ MainStRpmpPrsSw : 190|2@1+ (1,0) [0|3] "" Vector__XXX
 SG_ GndSawInitSw : 188|2@1+ (1,0) [0|3] "" Vector__XXX
 SG_ FanErrSig : 186|2@1+ (1,0) [0|3] "" Vector__XXX
 SG_ HydWakeUpSw : 184|2@1+ (1,0) [0|3] "" Vector__XXX
 SG_ EmgStpSw : 182|2@1+ (1,0) [0|3] "" Vector__XXX
 SG_ HhVltChgSw : 180|2@1+ (1,0) [0|3] "" Vector__XXX
 SG_ PrkBrkPrsSw : 178|2@1+ (1,0) [0|3] "" Vector__XXX
 SG_ RamLckRvsSw : 176|2@1+ (1,0) [0|3] "" Vector__XXX
 SG_ AirCompPrsSw : 174|2@1+ (1,0) [0|3] "" Vector__XXX
 SG_ Mg2DJoyTrigSw : 172|2@1+ (1,0) [0|3] "" Vector__XXX
 SG_ KeySwBr : 170|2@1+ (1,0) [0|3] "" Vector__XXX
 SG_ TwSwSelSw : 168|2@1+ (1,0) [0|3] "" Vector__XXX
 SG_ DzOutSw : 166|2@1+ (1,0) [0|3] "" Vector__XXX
 SG_ MrrHtSw : 164|2@1+ (1,0) [0|3] "" Vector__XXX
 SG_ SwgAlignSw : 162|2@1+ (1,0) [0|3] "" Vector__XXX
 SG_ MultiFuncSw : 160|2@1+ (1,0) [0|3] "" Vector__XXX
 SG_ AutoDigSw : 158|2@1+ (1,0) [0|3] "" Vector__XXX
 SG_ TrvlPmpHhSpdSw : 156|2@1+ (1,0) [0|3] "" Vector__XXX
 SG_ DoorSw : 154|2@1+ (1,0) [0|3] "" Vector__XXX
 SG_ RrAxleRhHallSsSw : 152|2@1+ (1,0) [0|3] "" Vector__XXX
 SG_ RrAxleLhHallSsSw : 150|2@1+ (1,0) [0|3] "" Vector__XXX
 SG_ FrAxleHallSsSw : 148|2@1+ (1,0) [0|3] "" Vector__XXX
 SG_ QckCouplerRhSw : 146|2@1+ (1,0) [0|3] "" Vector__XXX
 SG_ QckCouplerLhSw : 144|2@1+ (1,0) [0|3] "" Vector__XXX
 SG_ PowMdSw : 142|2@1+ (1,0) [0|3] "" Vector__XXX
 SG_ WrkMdSw : 140|2@1+ (1,0) [0|3] "" Vector__XXX
 SG_ AuxMdSelSw : 138|2@1+ (1,0) [0|3] "" Vector__XXX
 SG_ SwgBrkRlsSw : 136|2@1+ (1,0) [0|3] "" Vector__XXX
 SG_ BrkrFltSw : 134|2@1+ (1,0) [0|3] "" Vector__XXX
 SG_ SwgPriSw : 132|2@1+ (1,0) [0|3] "" Vector__XXX
 SG_ RttCwSw : 130|2@1+ (1,0) [0|3] "" Vector__XXX
 SG_ RttCcwSw : 128|2@1+ (1,0) [0|3] "" Vector__XXX
 SG_ WiperWasherSw : 126|2@1+ (1,0) [0|3] "" Vector__XXX
 SG_ WiperContSw : 124|2@1+ (1,0) [0|3] "" Vector__XXX
 SG_ Wiper2StepSw : 122|2@1+ (1,0) [0|3] "" Vector__XXX
 SG_ Wiper1StepSw : 120|2@1+ (1,0) [0|3] "" Vector__XXX
 SG_ TmsSt : 118|2@1+ (1,0) [0|3] "" Vector__XXX
 SG_ ArtiBoomPrsSw : 116|2@1+ (1,0) [0|3] "" Vector__XXX
 SG_ CoolLvSw : 114|2@1+ (1,0) [0|3] "" Vector__XXX
 SG_ RttOprSw : 112|2@1+ (1,0) [0|3] "" Vector__XXX
 SG_ TwCloseOprSw : 110|2@1+ (1,0) [0|3] "" Vector__XXX
 SG_ TwOpenOprSw : 108|2@1+ (1,0) [0|3] "" Vector__XXX
 SG_ RcwCloseSw : 106|2@1+ (1,0) [0|3] "" Vector__XXX
 SG_ RcwOprSw : 104|2@1+ (1,0) [0|3] "" Vector__XXX
 SG_ EmgEgStpSw : 102|2@1+ (1,0) [0|3] "" Vector__XXX
 SG_ OwOptPdlPrsSw : 100|2@1+ (1,0) [0|3] "" Vector__XXX
 SG_ SpcSw : 98|2@1+ (1,0) [0|3] "" Vector__XXX
 SG_ IhbSw : 96|2@1+ (1,0) [0|3] "" Vector__XXX
 SG_ TrvlAlmSelSw : 94|2@1+ (1,0) [0|3] "" Vector__XXX
 SG_ SwgAlmSelSw : 92|2@1+ (1,0) [0|3] "" Vector__XXX
 SG_ EmgStrSw : 90|2@1+ (1,0) [0|3] "" Vector__XXX
 SG_ HhBeamSw : 88|2@1+ (1,0) [0|3] "" Vector__XXX
 SG_ StpLmp : 86|2@1+ (1,0) [0|3] "" Vector__XXX
 SG_ AccPdlSw : 84|2@1+ (1,0) [0|3] "" Vector__XXX
 SG_ BrkPrsSw : 82|2@1+ (1,0) [0|3] "" Vector__XXX
 SG_ Cruise : 80|2@1+ (1,0) [0|3] "" Vector__XXX
 SG_ EgOilPrsSw : 78|2@1+ (1,0) [0|3] "" Vector__XXX
 SG_ WrkPxPrsSw : 76|2@1+ (1,0) [0|3] "" Vector__XXX
 SG_ TrvlPyPrsSw : 74|2@1+ (1,0) [0|3] "" Vector__XXX
 SG_ IgnSw : 72|2@1+ (1,0) [0|3] "" Vector__XXX
 SG_ RamLckAutoSw : 70|2@1+ (1,0) [0|3] "" Vector__XXX
 SG_ PreHt : 68|2@1+ (1,0) [0|3] "" Vector__XXX
 SG_ WifWrn : 66|2@1+ (1,0) [0|3] "" Vector__XXX
 SG_ SwgPrsSw : 64|2@1+ (1,0) [0|3] "" Vector__XXX
 SG_ JoyPtnBhl : 62|2@1+ (1,0) [0|3] "" Vector__XXX
 SG_ JoyPtnIso : 60|2@1+ (1,0) [0|3] "" Vector__XXX
 SG_ RvsFanSw : 58|2@1+ (1,0) [0|3] "" Vector__XXX
 SG_ TwOptPdlPrsSw : 56|2@1+ (1,0) [0|3] "" Vector__XXX
 SG_ BrkOilPrsWrn : 54|2@1+ (1,0) [0|3] "" Vector__XXX
 SG_ OwdWrnSelSw : 52|2@1+ (1,0) [0|3] "" Vector__XXX
 SG_ RetFiltWrn : 50|2@1+ (1,0) [0|3] "" Vector__XXX
 SG_ PilotFiltWrn : 48|2@1+ (1,0) [0|3] "" Vector__XXX
 SG_ AirCleanerWrn : 46|2@1+ (1,0) [0|3] "" Vector__XXX
 SG_ PilotCutOffSw : 44|2@1+ (1,0) [0|3] "" Vector__XXX
 SG_ ItgtBoomSw : 42|2@1+ (1,0) [0|3] "" Vector__XXX
 SG_ OneTouchRedSpdSw : 40|2@1+ (1,0) [0|3] "" Vector__XXX
 SG_ RamLckSw : 38|2@1+ (1,0) [0|3] "" Vector__XXX
 SG_ PrkSw : 36|2@1+ (1,0) [0|3] "" Vector__XXX
 SG_ AirCndSw : 34|2@1+ (1,0) [0|3] "" Vector__XXX
 SG_ JoyDirSelSw : 32|2@1+ (1,0) [0|3] "" Vector__XXX
 SG_ TrvlBwdSw : 30|2@1+ (1,0) [0|3] "" Vector__XXX
 SG_ TrvlNtrlSw : 28|2@1+ (1,0) [0|3] "" Vector__XXX
 SG_ TrvlFwdSw : 26|2@1+ (1,0) [0|3] "" Vector__XXX
 SG_ HhSpdSelSw : 24|2@1+ (1,0) [0|3] "" Vector__XXX
 SG_ LwSpdSelSw : 22|2@1+ (1,0) [0|3] "" Vector__XXX
 SG_ InchingSelSw : 20|2@1+ (1,0) [0|3] "" Vector__XXX
 SG_ QckCoupler : 18|2@1+ (1,0) [0|3] "" Vector__XXX
 SG_ TwSelSw : 16|2@1+ (1,0) [0|3] "" Vector__XXX
 SG_ OnwWaySelSw : 14|2@1+ (1,0) [0|3] "" Vector__XXX
 SG_ WrkLmpSw : 12|2@1+ (1,0) [0|3] "" Vector__XXX
 SG_ AutoTrvl2SpdSw : 10|2@1+ (1,0) [0|3] "" Vector__XXX
 SG_ Trvl2SpdSelSw : 8|2@1+ (1,0) [0|3] "" Vector__XXX
 SG_ TrvlSelSw : 6|2@1+ (1,0) [0|3] "" Vector__XXX
 SG_ BrkrSw : 4|2@1+ (1,0) [0|3] "" Vector__XXX
 SG_ PwrMaxSw : 2|2@1+ (1,0) [0|3] "" Vector__XXX
 SG_ Alt : 0|2@1+ (1,0) [0|3] "" Vector__XXX

BO_ 2566903585 MCU_XDAI: 21 MCU
 SG_ EmgStrSv : 160|2@1+ (1,0) [0|3] "" Vector__XXX
 SG_ TrvlRhPilotCutOffSv : 158|2@1+ (1,0) [0|3] "" Vector__XXX
 SG_ GndSawMdChangeRly : 156|2@1+ (1,0) [0|3] "" Vector__XXX
 SG_ HvChgSig : 150|2@1+ (1,0) [0|3] "" Vector__XXX
 SG_ FanPwmSig : 148|2@1+ (1,0) [0|3] "" Vector__XXX
 SG_ TrkExpationSv : 146|2@1+ (1,0) [0|3] "" Vector__XXX
 SG_ HhVltMainRly : 144|2@1+ (1,0) [0|3] "" Vector__XXX
 SG_ HhVltPreChgRly : 142|2@1+ (1,0) [0|3] "" Vector__XXX
 SG_ PilotBz : 140|2@1+ (1,0) [0|3] "" Vector__XXX
 SG_ QckChgInd : 138|2@1+ (1,0) [0|3] "" Vector__XXX
 SG_ QckChgRly : 136|2@1+ (1,0) [0|3] "" Vector__XXX
 SG_ NormChgInd : 134|2@1+ (1,0) [0|3] "" Vector__XXX
 SG_ LwVltMainRly : 132|2@1+ (1,0) [0|3] "" Vector__XXX
 SG_ BoomSwgSelRly : 130|2@1+ (1,0) [0|3] "" Vector__XXX
 SG_ PmpDeratSv : 128|2@1+ (1,0) [0|3] "" Vector__XXX
 SG_ PrkBrkRly : 126|2@1+ (1,0) [0|3] "" Vector__XXX
 SG_ RvsLmpRly : 124|2@1+ (1,0) [0|3] "" Vector__XXX
 SG_ AirCompRly : 122|2@1+ (1,0) [0|3] "" Vector__XXX
 SG_ CabLmpRly : 120|2@1+ (1,0) [0|3] "" Vector__XXX
 SG_ AvmWrnSig : 118|2@1+ (1,0) [0|3] "" Vector__XXX
 SG_ WrkLmpRly : 116|2@1+ (1,0) [0|3] "" Vector__XXX
 SG_ AirCondCompStpSig : 114|2@1+ (1,0) [0|3] "" Vector__XXX
 SG_ Chmsl : 112|2@1+ (1,0) [0|3] "" Vector__XXX
 SG_ BoomSusRodSv : 110|2@1+ (1,0) [0|3] "" Vector__XXX
 SG_ BoomSusHedSv : 108|2@1+ (1,0) [0|3] "" Vector__XXX
 SG_ MrrHt : 106|2@1+ (1,0) [0|3] "" Vector__XXX
 SG_ ClearLmp : 104|2@1+ (1,0) [0|3] "" Vector__XXX
 SG_ HhHeadLmp : 102|2@1+ (1,0) [0|3] "" Vector__XXX
 SG_ LwHeadLmp : 100|2@1+ (1,0) [0|3] "" Vector__XXX
 SG_ FineSwgSv : 98|2@1+ (1,0) [0|3] "" Vector__XXX
 SG_ TurnRhSigLmp : 96|2@1+ (1,0) [0|3] "" Vector__XXX
 SG_ TurnLhSigLmp : 94|2@1+ (1,0) [0|3] "" Vector__XXX
 SG_ BeaconRly : 92|2@1+ (1,0) [0|3] "" Vector__XXX
 SG_ LightRly : 90|2@1+ (1,0) [0|3] "" Vector__XXX
 SG_ LmpRly : 88|2@1+ (1,0) [0|3] "" Vector__XXX
 SG_ RamLckSv : 86|2@1+ (1,0) [0|3] "" Vector__XXX
 SG_ LwSpdTrvlSv : 84|2@1+ (1,0) [0|3] "" Vector__XXX
 SG_ TrvlPmpHhSpd2Sv : 82|2@1+ (1,0) [0|3] "" Vector__XXX
 SG_ TrvlPmpHhSpd1Sv : 80|2@1+ (1,0) [0|3] "" Vector__XXX
 SG_ WiperWasherRly : 78|2@1+ (1,0) [0|3] "" Vector__XXX
 SG_ WiperRly : 76|2@1+ (1,0) [0|3] "" Vector__XXX
 SG_ AutoShutOffRly : 74|2@1+ (1,0) [0|3] "" Vector__XXX
 SG_ AirHtRly : 72|2@1+ (1,0) [0|3] "" Vector__XXX
 SG_ GlowPlugPreHhRly2 : 70|2@1+ (1,0) [0|3] "" Vector__XXX
 SG_ GlowPlugPreHhRly1 : 68|2@1+ (1,0) [0|3] "" Vector__XXX
 SG_ HhSpdRly : 66|2@1+ (1,0) [0|3] "" Vector__XXX
 SG_ LwSpdRly : 64|2@1+ (1,0) [0|3] "" Vector__XXX
 SG_ InchingRly : 62|2@1+ (1,0) [0|3] "" Vector__XXX
 SG_ SpareRly : 60|2@1+ (1,0) [0|3] "" Vector__XXX
 SG_ BackBzRly : 58|2@1+ (1,0) [0|3] "" Vector__XXX
 SG_ StartRly : 56|2@1+ (1,0) [0|3] "" Vector__XXX
 SG_ AutoBrkSv : 54|2@1+ (1,0) [0|3] "" Vector__XXX
 SG_ PilotCutOffSv : 52|2@1+ (1,0) [0|3] "" Vector__XXX
 SG_ McvEpprCutOffSv : 50|2@1+ (1,0) [0|3] "" Vector__XXX
 SG_ BsSpoolSc : 48|2@1+ (1,0) [0|3] "" Vector__XXX
 SG_ QckCouplerSv : 46|2@1+ (1,0) [0|3] "" Vector__XXX
 SG_ FreeBoomDnSv : 44|2@1+ (1,0) [0|3] "" Vector__XXX
 SG_ FreeBoomUpSv : 42|2@1+ (1,0) [0|3] "" Vector__XXX
 SG_ TrvlStrgtSv : 40|2@1+ (1,0) [0|3] "" Vector__XXX
 SG_ RttCcwSv : 38|2@1+ (1,0) [0|3] "" Vector__XXX
 SG_ RttCwSv : 36|2@1+ (1,0) [0|3] "" Vector__XXX
 SG_ Trvl2PmpCmbSv : 34|2@1+ (1,0) [0|3] "" Vector__XXX
 SG_ OptPdlSaftySv : 32|2@1+ (1,0) [0|3] "" Vector__XXX
 SG_ ForceRgnSv : 30|2@1+ (1,0) [0|3] "" Vector__XXX
 SG_ TwOprSv : 28|2@1+ (1,0) [0|3] "" Vector__XXX
 SG_ UnloadSv : 26|2@1+ (1,0) [0|3] "" Vector__XXX
 SG_ TwRhCloseSv : 24|2@1+ (1,0) [0|3] "" Vector__XXX
 SG_ TwRhOpenSv : 22|2@1+ (1,0) [0|3] "" Vector__XXX
 SG_ SwgBrkRelSv : 20|2@1+ (1,0) [0|3] "" Vector__XXX
 SG_ BypassCutOffSv : 18|2@1+ (1,0) [0|3] "" Vector__XXX
 SG_ RwdSv : 16|2@1+ (1,0) [0|3] "" Vector__XXX
 SG_ FwdSv : 14|2@1+ (1,0) [0|3] "" Vector__XXX
 SG_ CruiseSv : 12|2@1+ (1,0) [0|3] "" Vector__XXX
 SG_ TwoPmpSelSv : 10|2@1+ (1,0) [0|3] "" Vector__XXX
 SG_ FanRvsSv : 8|2@1+ (1,0) [0|3] "" Vector__XXX
 SG_ BrkrSelSv : 6|2@1+ (1,0) [0|3] "" Vector__XXX
 SG_ HhSpdTrvlSv : 4|2@1+ (1,0) [0|3] "" Vector__XXX
 SG_ PowMaxSv : 2|2@1+ (1,0) [0|3] "" Vector__XXX
 SG_ BrkrOprSv : 0|2@1+ (1,0) [0|3] "" Vector__XXX

BO_ 2566903841 MCU_LASI: 98 MCU
 SG_ TmsSecVlt : 768|16@1+ (0.001,0) [0|64.255] "V" Vector__XXX
 SG_ RsvJoy1GripYPos : 746|6@1+ (1,0) [0|63] "" Vector__XXX
 SG_ Joy1GripYPos : 736|10@1+ (0.1,0) [0|102] "%" Vector__XXX
 SG_ RsvJoy1YPos : 730|6@1+ (1,0) [0|63] "" Vector__XXX
 SG_ Joy1YPos : 720|10@1+ (0.1,0) [0|102] "%" Vector__XXX
 SG_ RsvJoy1XPos : 714|6@1+ (1,0) [0|63] "" Vector__XXX
 SG_ Joy1XPos : 704|10@1+ (0.1,0) [0|102] "%" Vector__XXX
 SG_ EmcvLeverOptB : 688|16@1+ (0.001,0) [0|64.255] "V" Vector__XXX
 SG_ EmcvLeverOptA : 672|16@1+ (0.001,0) [0|64.255] "V" Vector__XXX
 SG_ EmcvLeverBckB : 656|16@1+ (0.001,0) [0|64.255] "V" Vector__XXX
 SG_ EmcvLeverBckA : 640|16@1+ (0.001,0) [0|64.255] "V" Vector__XXX
 SG_ EmcvLeverBoomB : 624|16@1+ (0.001,0) [0|64.255] "V" Vector__XXX
 SG_ EmcvLeverBoomA : 608|16@1+ (0.001,0) [0|64.255] "V" Vector__XXX
 SG_ ElecStrVv : 592|16@1+ (1,0) [0|65535] "%" Vector__XXX
 SG_ ElecStrLeverB : 576|16@1+ (0.001,0) [0|64.255] "V" Vector__XXX
 SG_ ElecStrLeverA : 560|16@1+ (0.001,0) [0|64.255] "V" Vector__XXX
 SG_ AcpSsPrs : 544|16@1+ (16,0) [0|4000] "kPa" Vector__XXX
 SG_ BatTmp : 512|16@1+ (0.001,0) [0|64.255] "V" Vector__XXX
 SG_ AltTmp : 496|16@1+ (0.001,0) [0|64.255] "V" Vector__XXX
 SG_ AxleOilTmp : 432|16@1+ (1,-40) [-40|210] "�C" Vector__XXX
 SG_ HydOilTmp : 416|16@1+ (1,-40) [-40|210] "�C" Vector__XXX
 SG_ CoolTmp : 400|16@1+ (1,-40) [-40|210] "�C" Vector__XXX
 SG_ OpsSsVlt : 384|16@1+ (0.001,0) [0|64.255] "V" Vector__XXX
 SG_ WifSsVlt : 368|16@1+ (0.001,0) [0|64.255] "V" Vector__XXX
 SG_ FuelLv : 352|16@1+ (1,0) [0|250] "%" Vector__XXX
 SG_ BrkPdlB : 304|16@1+ (0.001,0) [0|64.255] "V" Vector__XXX
 SG_ BrkPdlA : 288|16@1+ (0.001,0) [0|64.255] "V" Vector__XXX
 SG_ AccPdlVlt : 272|16@1+ (0.001,0) [0|64.255] "V" Vector__XXX
 SG_ CtlLsPrs : 224|16@1+ (0.0625,0) [0|500] "bar" Vector__XXX
 SG_ CtlTowSpdPrs : 208|16@1+ (0.0625,0) [0|500] "bar" Vector__XXX
 SG_ AngSsBckB : 192|16@1+ (0.001,0) [0|64.255] "V" Vector__XXX
 SG_ AngSsBckA : 176|16@1+ (0.001,0) [0|64.255] "V" Vector__XXX
 SG_ AngSsBoomB : 160|16@1+ (0.001,0) [0|64.255] "V" Vector__XXX
 SG_ AngSsBoomA : 144|16@1+ (0.001,0) [0|64.255] "V" Vector__XXX
 SG_ CtlBckLoadPrs : 128|16@1+ (0.0625,0) [0|500] "bar" Vector__XXX
 SG_ CtlEgCtrlDialVlt : 112|16@1+ (0.001,0) [0|64.255] "V" Vector__XXX
 SG_ PrkBrkPrs : 96|16@1+ (0.0625,0) [0|500] "bar" Vector__XXX
 SG_ FanMotPrs : 80|16@1+ (0.0625,0) [0|500] "bar" Vector__XXX
 SG_ BrkOilPrs : 64|16@1+ (0.0625,0) [0|500] "bar" Vector__XXX
 SG_ StrPrs : 48|16@1+ (0.0625,0) [0|500] "bar" Vector__XXX
 SG_ BoomRodPrs : 32|16@1+ (0.0625,0) [0|500] "bar" Vector__XXX
 SG_ BooHeadPrs : 16|16@1+ (0.0625,0) [0|500] "bar" Vector__XXX
 SG_ MainPrs : 0|16@1+ (0.0625,0) [0|500] "bar" Vector__XXX

BO_ 2566904097 MCU_LAAI: 48 MCU
 SG_ CacFanCtrl : 368|16@1+ (0.01,-321.27) [-321.27|321.28] "%" Vector__XXX
 SG_ CdsFanCtrl : 352|16@1+ (0.01,-321.27) [-321.27|321.28] "%" Vector__XXX
 SG_ RipperDnEvc : 336|16@1+ (1,0) [0|2000] "mA" Vector__XXX
 SG_ RipperUpEvc : 320|16@1+ (1,0) [0|2000] "mA" Vector__XXX
 SG_ BladeAngLhEvc : 304|16@1+ (1,0) [0|2000] "mA" Vector__XXX
 SG_ BladeAngRhEvc : 288|16@1+ (1,0) [0|2000] "mA" Vector__XXX
 SG_ BladeDnEvc : 272|16@1+ (1,0) [0|2000] "mA" Vector__XXX
 SG_ BladeRaiseEvc : 256|16@1+ (1,0) [0|2000] "mA" Vector__XXX
 SG_ BladeTiltLhEvc : 240|16@1+ (1,0) [0|2000] "mA" Vector__XXX
 SG_ BladeTiltRhEvc : 224|16@1+ (1,0) [0|2000] "mA" Vector__XXX
 SG_ Spool4BEvc : 128|16@1+ (1,0) [0|2000] "mA" Vector__XXX
 SG_ Spool4AEvc : 112|16@1+ (1,0) [0|2000] "mA" Vector__XXX
 SG_ Opt2Evc : 96|16@1+ (1,0) [0|2000] "mA" Vector__XXX
 SG_ Opt1Evc : 80|16@1+ (1,0) [0|2000] "mA" Vector__XXX
 SG_ BckDumpEvc : 64|16@1+ (1,0) [0|2000] "mA" Vector__XXX
 SG_ BoomCrowdEvc : 48|16@1+ (1,0) [0|2000] "mA" Vector__XXX
 SG_ BoomFltEvc : 32|16@1+ (1,0) [0|2000] "mA" Vector__XXX
 SG_ BoomRaiseEvc : 16|16@1+ (1,0) [0|2000] "mA" Vector__XXX
 SG_ FanCtrlEvc : 0|16@1+ (1,0) [0|2000] "mA" Vector__XXX

BO_ 2566904353 MCU_LDSI: 14 MCU
 SG_ OpsSw : 110|2@1+ (1,0) [0|3] "" Vector__XXX
 SG_ HhFlowPinK : 108|2@1+ (1,0) [0|3] "" Vector__XXX
 SG_ HhFlowPinN : 106|2@1+ (1,0) [0|3] "" Vector__XXX
 SG_ DustInd : 104|2@1+ (1,0) [0|3] "" Vector__XXX
 SG_ FrDoorSw : 102|2@1+ (1,0) [0|3] "" Vector__XXX
 SG_ ArmRestLhSw : 100|2@1+ (1,0) [0|3] "" Vector__XXX
 SG_ ArmRestRhSw : 98|2@1+ (1,0) [0|3] "" Vector__XXX
 SG_ Spool3LeverSw : 96|2@1+ (1,0) [0|3] "" Vector__XXX
 SG_ BckLeverSw : 94|2@1+ (1,0) [0|3] "" Vector__XXX
 SG_ EgOilPrsSw : 92|2@1+ (1,0) [0|3] "" Vector__XXX
 SG_ HydLckoutSw : 90|2@1+ (1,0) [0|3] "" Vector__XXX
 SG_ TractionCtrlSw : 88|2@1+ (1,0) [0|3] "" Vector__XXX
 SG_ AirCleanSw : 86|2@1+ (1,0) [0|3] "" Vector__XXX
 SG_ RetFiltSw : 84|2@1+ (1,0) [0|3] "" Vector__XXX
 SG_ QckCouperLckSw : 82|2@1+ (1,0) [0|3] "" Vector__XXX
 SG_ DnShftSw : 80|2@1+ (1,0) [0|3] "" Vector__XXX
 SG_ PreHt : 78|2@1+ (1,0) [0|3] "" Vector__XXX
 SG_ Joy1XDetentPosSt : 76|2@1+ (1,0) [0|3] "" Vector__XXX
 SG_ Joy1YDetentPosSt : 74|2@1+ (1,0) [0|3] "" Vector__XXX
 SG_ IhbSw : 72|2@1+ (1,0) [0|3] "" Vector__XXX
 SG_ HstOilFiltWrn : 70|2@1+ (1,0) [0|3] "" Vector__XXX
 SG_ GrboxOvrTmp : 68|2@1+ (1,0) [0|3] "" Vector__XXX
 SG_ AgsLmp : 66|2@1+ (1,0) [0|3] "" Vector__XXX
 SG_ QckCouplerInitSw : 64|2@1+ (1,0) [0|3] "" Vector__XXX
 SG_ PrkSw : 62|2@1+ (1,0) [0|3] "" Vector__XXX
 SG_ SeatBeltSw : 60|2@1+ (1,0) [0|3] "" Vector__XXX
 SG_ ReDefrstSw : 58|2@1+ (1,0) [0|3] "" Vector__XXX
 SG_ HormSw : 56|2@1+ (1,0) [0|3] "" Vector__XXX
 SG_ Fnr2ActSw : 54|2@1+ (1,0) [0|3] "" Vector__XXX
 SG_ RearWiperStpSw : 52|2@1+ (1,0) [0|3] "" Vector__XXX
 SG_ FrWiperStpSig : 50|2@1+ (1,0) [0|3] "" Vector__XXX
 SG_ DpfForceRgnSw : 48|2@1+ (1,0) [0|3] "" Vector__XXX
 SG_ EmgStrPrsSw : 46|2@1+ (1,0) [0|3] "" Vector__XXX
 SG_ MainStrPrsSw : 44|2@1+ (1,0) [0|3] "" Vector__XXX
 SG_ AccPdlKd : 42|2@1+ (1,0) [0|3] "" Vector__XXX
 SG_ AccPdlIvs : 40|2@1+ (1,0) [0|3] "" Vector__XXX
 SG_ PrkBrkPrsSw : 38|2@1+ (1,0) [0|3] "" Vector__XXX
 SG_ CoolLv : 36|2@1+ (1,0) [0|3] "" Vector__XXX
 SG_ WghCntSw : 34|2@1+ (1,0) [0|3] "" Vector__XXX
 SG_ EmgStpSw : 32|2@1+ (1,0) [0|3] "" Vector__XXX
 SG_ DhlManSw : 30|2@1+ (1,0) [0|3] "" Vector__XXX
 SG_ FnrR3 : 28|2@1+ (1,0) [0|3] "" Vector__XXX
 SG_ FnrN3 : 26|2@1+ (1,0) [0|3] "" Vector__XXX
 SG_ FnrF3 : 24|2@1+ (1,0) [0|3] "" Vector__XXX
 SG_ FnrR2 : 22|2@1+ (1,0) [0|3] "" Vector__XXX
 SG_ FnrN2 : 20|2@1+ (1,0) [0|3] "" Vector__XXX
 SG_ FnrF2 : 18|2@1+ (1,0) [0|3] "" Vector__XXX
 SG_ FnrR1 : 16|2@1+ (1,0) [0|3] "" Vector__XXX
 SG_ FnrN1 : 14|2@1+ (1,0) [0|3] "" Vector__XXX
 SG_ FnrF1 : 12|2@1+ (1,0) [0|3] "" Vector__XXX
 SG_ StartBrSw : 10|2@1+ (1,0) [0|3] "" Vector__XXX
 SG_ StartAccSw : 8|2@1+ (1,0) [0|3] "" Vector__XXX
 SG_ StartCSw : 6|2@1+ (1,0) [0|3] "" Vector__XXX
 SG_ PilotCutOffSw : 4|2@1+ (1,0) [0|3] "" Vector__XXX
 SG_ ArmRestCutOffSw : 2|2@1+ (1,0) [0|3] "" Vector__XXX
 SG_ ElecStrSelSw : 0|2@1+ (1,0) [0|3] "" Vector__XXX

BO_ 2566904372 SMK_SOFT: 250 SMK

BO_ 2566904609 MCU_LDAI: 14 MCU
 SG_ Aux8Rly : 110|2@1+ (1,0) [0|3] "" Vector__XXX
 SG_ Aux7Rly : 108|2@1+ (1,0) [0|3] "" Vector__XXX
 SG_ Aux6Rly : 106|2@1+ (1,0) [0|3] "" Vector__XXX
 SG_ Aux5Rly : 104|2@1+ (1,0) [0|3] "" Vector__XXX
 SG_ Aux4Rly : 102|2@1+ (1,0) [0|3] "" Vector__XXX
 SG_ Aux3Rly : 100|2@1+ (1,0) [0|3] "" Vector__XXX
 SG_ AuxShutOffSv : 98|2@1+ (1,0) [0|3] "" Vector__XXX
 SG_ PilotCutOffSv : 96|2@1+ (1,0) [0|3] "" Vector__XXX
 SG_ FrWiperRly : 94|2@1+ (1,0) [0|3] "" Vector__XXX
 SG_ SideWasherRly : 92|2@1+ (1,0) [0|3] "" Vector__XXX
 SG_ UreaSuperChgWrnSig : 90|2@1+ (1,0) [0|3] "" Vector__XXX
 SG_ EgRunOutSig : 88|2@1+ (1,0) [0|3] "" Vector__XXX
 SG_ SideWiperRly : 86|2@1+ (1,0) [0|3] "" Vector__XXX
 SG_ FrWhaserRly : 84|2@1+ (1,0) [0|3] "" Vector__XXX
 SG_ FrWiperLwSigRly : 82|2@1+ (1,0) [0|3] "" Vector__XXX
 SG_ FrWiperHhSpdRly : 80|2@1+ (1,0) [0|3] "" Vector__XXX
 SG_ LwBeamRly : 78|2@1+ (1,0) [0|3] "" Vector__XXX
 SG_ HhBeamRly : 76|2@1+ (1,0) [0|3] "" Vector__XXX
 SG_ IllmLmpRly : 74|2@1+ (1,0) [0|3] "" Vector__XXX
 SG_ RttBeaconRly : 72|2@1+ (1,0) [0|3] "" Vector__XXX
 SG_ TurnSigRhRly : 70|2@1+ (1,0) [0|3] "" Vector__XXX
 SG_ TurnSigLhRly : 68|2@1+ (1,0) [0|3] "" Vector__XXX
 SG_ HormRly : 66|2@1+ (1,0) [0|3] "" Vector__XXX
 SG_ AccRly : 64|2@1+ (1,0) [0|3] "" Vector__XXX
 SG_ RrWinHtRly : 62|2@1+ (1,0) [0|3] "" Vector__XXX
 SG_ AutoShutOffRly : 60|2@1+ (1,0) [0|3] "" Vector__XXX
 SG_ BackUpBzRly : 58|2@1+ (1,0) [0|3] "" Vector__XXX
 SG_ MrrHtRly : 56|2@1+ (1,0) [0|3] "" Vector__XXX
 SG_ HuelHtRly : 54|2@1+ (1,0) [0|3] "" Vector__XXX
 SG_ GlowPlugFuelRly : 52|2@1+ (1,0) [0|3] "" Vector__XXX
 SG_ GlowPlugRly : 50|2@1+ (1,0) [0|3] "" Vector__XXX
 SG_ EmgStrTestRly : 48|2@1+ (1,0) [0|3] "" Vector__XXX
 SG_ RrWasherRly : 46|2@1+ (1,0) [0|3] "" Vector__XXX
 SG_ RrWiperRly : 44|2@1+ (1,0) [0|3] "" Vector__XXX
 SG_ RrWrkCabLmpRly : 42|2@1+ (1,0) [0|3] "" Vector__XXX
 SG_ RrWrkRadLmpRly : 40|2@1+ (1,0) [0|3] "" Vector__XXX
 SG_ FrWrkLmpRly : 38|2@1+ (1,0) [0|3] "" Vector__XXX
 SG_ ElecStrSaftyRly : 36|2@1+ (1,0) [0|3] "" Vector__XXX
 SG_ PilotBzRly : 34|2@1+ (1,0) [0|3] "" Vector__XXX
 SG_ LisActRly : 32|2@1+ (1,0) [0|3] "" Vector__XXX
 SG_ HstCutOffRhSv : 30|2@1+ (1,0) [0|3] "" Vector__XXX
 SG_ HstCutOffLhSv : 28|2@1+ (1,0) [0|3] "" Vector__XXX
 SG_ BckMagnet : 26|2@1+ (1,0) [0|3] "" Vector__XXX
 SG_ BoomMagnet : 24|2@1+ (1,0) [0|3] "" Vector__XXX
 SG_ HstCutOffSv : 20|2@1+ (1,0) [0|3] "" Vector__XXX
 SG_ HydCutOffSv : 18|2@1+ (1,0) [0|3] "" Vector__XXX
 SG_ StartRly : 16|2@1+ (1,0) [0|3] "" Vector__XXX
 SG_ QckCouplerRly : 14|2@1+ (1,0) [0|3] "" Vector__XXX
 SG_ EgStpRly : 12|2@1+ (1,0) [0|3] "" Vector__XXX
 SG_ PrkBrkRlsSv : 10|2@1+ (1,0) [0|3] "" Vector__XXX
 SG_ EscortWrkLmpRly : 8|2@1+ (1,0) [0|3] "" Vector__XXX
 SG_ AxleOilCoolSv : 6|2@1+ (1,0) [0|3] "" Vector__XXX
 SG_ UnloadSv : 4|2@1+ (1,0) [0|3] "" Vector__XXX
 SG_ BrkChgSv : 2|2@1+ (1,0) [0|3] "" Vector__XXX
 SG_ RvsFanSV : 0|2@1+ (1,0) [0|3] "" Vector__XXX

CM_ BO_ 2566893620 "Smart Key Command";
CM_ SG_ 2566893620 SmkId "SMKID";
CM_ SG_ 2566893620 SoftwareVer "SoftwareVersion";
CM_ SG_ 2566893620 FobImmobilizerWrn "FOBImmobilizerWarning";
CM_ SG_ 2566893620 FobLowBatWrn "FOBLowBatteryWarning";
CM_ SG_ 2566893620 NoDttFobInsideCabinWrn "NoDetectionFOBInsideCabinWarning";
CM_ SG_ 2566893620 FobRgstId "FOBRegistrationID";
CM_ SG_ 2566893620 FobRgstFdbk "FOBRegistrationFeedback";
CM_ SG_ 2566893620 PreheatSt "PreheatStatus";
CM_ SG_ 2566893620 AppLmpSt "ApplicationLampStatus";
CM_ SG_ 2566893620 VentilationTmp "VentilationTemperature";
CM_ SG_ 2566893620 VentilationSt "VentilationStatus";
CM_ SG_ 2566893620 DoorLckSt "DoorLockStatus";
CM_ BO_ 2566893876 "Smart Key FOB";
CM_ BO_ 2566894154 "TMS Request to Smart Key Data";
CM_ BO_ 2566894388 "Smart Key Info";
CM_ SG_ 2566894388 DeicerSt "DeicerStatus";
CM_ SG_ 2566894388 ForcedEgStopCmd "ForcedEngineStopCommand";
CM_ SG_ 2566894388 RmRunningSt "RemoteRunningStatus";
CM_ SG_ 2566894388 MaintenanceDoorSt "MaintenanceDoorStatus";
CM_ SG_ 2566894388 CabinDoorSt "CabinDoorStatus";
CM_ SG_ 2566894388 FobBatSt "FOBBatteryStatus";
CM_ SG_ 2566894388 MchTonage "MachineTonage";
CM_ SG_ 2566894388 MchModel "MachineModel";
CM_ SG_ 2566894388 FobDtt "FOBDetect";
CM_ SG_ 2566894388 KeyStChange "KeyStatusChange";
CM_ BO_ 2566896131 "TCU Message5 to VCU";
CM_ SG_ 2566896131 CTLLhRvsTrvlPmpPrs "[CTL]LHReverseTravelPumpPressure";
CM_ SG_ 2566896131 CTLLhFwdTrvlPmpPrs "[CTL]LHForwardTravelPumpPressure";
CM_ SG_ 2566896131 CTLRhRvsTrvlPmpPrs "[CTL]RHReverseTravelPumpPressure";
CM_ SG_ 2566896131 CTLRhFwdTrvlPmpPrs "[CTL]RHForwardTravelPumpPressure";
CM_ BO_ 2566896387 "TCU Message4 to VCU";
CM_ SG_ 2566896387 HstCutOffSVSt "HSTCutOffS/VStatus";
CM_ SG_ 2566896387 TwoSpdSVSt "TwoSpeedS/VStatus";
CM_ SG_ 2566896387 TrackLdTypeSybCreep "TrackLoaderTypeSymbol;Creep";
CM_ BO_ 2566896643 "TCU Handshake Group";
CM_ SG_ 2566896643 SetMaxSpdLimit "??;MaxSpeedLimit";
CM_ SG_ 2566896643 SetStrDriftCompensation "??;SteeringDriftCompensation";
CM_ SG_ 2566896643 SetCreepMaxSpd "??;Creep????";
CM_ SG_ 2566896643 SetJoyTrvlRLTrack "??;????????;Right,LeftTrack";
CM_ SG_ 2566896643 TrvlSpdPreset4Rvs "TravelSpeedPreset4Reverse";
CM_ SG_ 2566896643 TrvlSpdPreset4Fwd "TravelSpeedPreset4Forward";
CM_ SG_ 2566896643 TrvlSpdPreset3Rvs "TravelSpeedPreset3Reverse";
CM_ SG_ 2566896643 TrvlSpdPreset3Fwd "TravelSpeedPreset3Forward";
CM_ SG_ 2566896643 TrvlSpdPreset2Rvs "TravelSpeedPreset2Reverse";
CM_ SG_ 2566896643 TrvlSpdPreset2Fwd "TravelSpeedPreset2Forward";
CM_ SG_ 2566896643 TrvlSpdPreset1Rvs "TravelSpeedPreset1Reverse";
CM_ SG_ 2566896643 TrvlSpdPreset1Fwd "TravelSpeedPreset1Forward";
CM_ SG_ 2566896643 TrvlSpdSet "TravelSpeedSet";
CM_ SG_ 2566896643 BrkPdlDecel "BrakePedalDeceleration";
CM_ BO_ 2365570307 "TCU Message1 to VCU";
CM_ SG_ 2365570307 LhTrvlMotorEpprVv "LHTravelMotorEPPRV/V";
CM_ SG_ 2365570307 RhTrvlMotorEpprVv "RHTravelMotorEPPRV/V";
CM_ SG_ 2365570307 LhRvsTrvlPmpEpprVv "LHReverseTravelPumpEPPRV/V";
CM_ SG_ 2365570307 LhFwdTrvlPmpEpprVv "LHForwardTravelPumpEPPRV/V";
CM_ SG_ 2365570307 RhRvsTrvlPmpEpprVv "RHReverseTravelPumpEPPRV/V";
CM_ SG_ 2365570307 RhFwdTrvlPmpEpprVv "RHForwardTravelPumpEPPRV/V";
CM_ SG_ 2365570307 VhcSpd "VehicleSpeed";
CM_ SG_ 2365570307 CurRvsMaxSpd "CurrentReverseMax.Speed";
CM_ SG_ 2365570307 CurFwdMaxSpd "CurrentForwardMax.Speed";
CM_ SG_ 2365570307 Fnr "FNR";
CM_ BO_ 2566897155 "TCU Message2 to VCU";
CM_ SG_ 2566897155 LhTrvlMotorSpdSs "LHTravelMotorSpeedSensor";
CM_ SG_ 2566897155 RhTrvlMotorSpdSs "RHTravelMotorSpeedSensor";
CM_ SG_ 2566897155 LhRvsTrvlPmpPrsSs "LHReverseTravelPumpPressureSensor";
CM_ SG_ 2566897155 LhFwdTrvlPmpPrsSs "LHForwardTravelPumpPressureSensor";
CM_ SG_ 2566897155 RhRvsTrvlPmpPrsSs "RHReverseTravelPumpPressureSensor";
CM_ SG_ 2566897155 RhFwdtPmpPrsSs "RHForwardTravelPumpPressureSensor";
CM_ BO_ 2566897411 "TCU Message3 to VCU";
CM_ SG_ 2566897411 ParkingBrkReqSt "ParkingBrakeRequestState";
CM_ SG_ 2566897411 CurPwrMd "CurrentPowerMode";
CM_ SG_ 2566897411 CurRvsMaxSpd "CurrentReverseMax.Speed";
CM_ SG_ 2566897411 CurFwdMaxSpd "CurrentForwardMax.Speed";
CM_ SG_ 2566897411 BrkAngSs2Pct "BrakeAngleSensor2Percentage";
CM_ SG_ 2566897411 BrkAngSs1Pct "BrakeAngleSensor1Percentage";
CM_ SG_ 2566897411 FootPdlPct "FootPedalPercentage";
CM_ SG_ 2566897411 BrkAngSs2Vlt "BrakeAngleSensor2Voltage";
CM_ SG_ 2566897411 BrkAngSs1Vlt "BrakeAngleSensor1Voltage";
CM_ SG_ 2566897411 EgCtrlDVlt "EngineControlDialVoltage";
CM_ BO_ 2365571105 "VCU Message1 to TCU";
CM_ SG_ 2365571105 HydTmp "HydraulicTemperature";
CM_ SG_ 2365571105 FootPdlPct "FootPedalPercentage";
CM_ SG_ 2365571105 RpmReqMd "RpmRequestMode";
CM_ SG_ 2365571105 ReqRvsMaxSpd "RequestReverseMax.Speed";
CM_ SG_ 2365571105 ReqFwdMaxSpd "RequestForwardMax.Speed";
CM_ SG_ 2365571105 PowMd "PowerMode";
CM_ SG_ 2365571105 IsParking "ParkingSignal";
CM_ SG_ 2365571105 TractionCtrl "TractionControl";
CM_ BO_ 2365571361 "VCU Message2 to TCU";
CM_ BO_ 2365572608 "Transmission of VGT nozzle position frame over CAN";
CM_ SG_ 2365572608 VgtCmdSt "VGTCommandstate";
CM_ SG_ 2365572608 VgtNzPos "VGTnozzleposition(LSB)";
CM_ BO_ 2566901763 "Handshake Data Information";
CM_ SG_ 2566901763 RandomVal "RandomValue";
CM_ BO_ 2566901793 "Handshake Data Information";
CM_ SG_ 2566901793 RandomVal "RandomValue";
CM_ BO_ 2566901936 "Handshake Data Information";
CM_ SG_ 2566901936 RandomVal "RandomValue";
CM_ BO_ 2566902049 "Function Setting Data Information";
CM_ SG_ 2566902049 OptSetCdsRvsFanAutoPrd "??;CondenserReverseFanAutomatic????";
CM_ SG_ 2566902049 OptSetTrailer "Opt??;Trailer";
CM_ SG_ 2566902049 OptSetEscortWrkLmp "??;EscortWorkingLamp";
CM_ SG_ 2566902049 OptSetCdsRvsFanMd "??;CondenserReverseFanMode";
CM_ SG_ 2566902049 OptSetRttDir "??;Rotating????";
CM_ SG_ 2566902049 OptSetAdvLv "??;AdvancedLeveling";
CM_ SG_ 2566902049 OptSetGndSaw "Opt??;GroundSAW";
CM_ SG_ 2566902049 OptSetTpms "??;TPMS";
CM_ SG_ 2566902049 OptSetAutoBrkrSens "??;AutoBreakerSensitivity";
CM_ SG_ 2566902049 OptSetAntiBlankFire "CMD;AntiBlankFireActivate";
CM_ SG_ 2566902049 OptSetJoyBoom "??;????????;Boom";
CM_ SG_ 2566902049 OptSetJoyTilt "??;????????;Tilt";
CM_ SG_ 2566902049 OptSetRvsFanDurTm "ReverseFanDurationTimeData";
CM_ SG_ 2566902049 OptSetHhFw "Opt??;HighFlow";
CM_ SG_ 2566902049 OptSet3DMgMc3rd "Opt??;3rdParty3DMGMC";
CM_ SG_ 2566902049 OptSetRrCabLmp "Opt??;??CabinLamp";
CM_ SG_ 2566902049 OptSetDzMc "Opt??;DozingMC??";
CM_ SG_ 2566902049 OptSetTrqCvtLckUp "Opt??;TorqueConverterLockUp";
CM_ SG_ 2566902049 OptSetTwThmbWhlDir "2way????????";
CM_ SG_ 2566902049 OptSetOptPdlType2 "Opt??;Opt????2";
CM_ SG_ 2566902049 OptSetMaxTrvlSpd "MaxTravelSpeedSet";
CM_ SG_ 2566902049 OptSetRollSlope "SetRollSlope";
CM_ SG_ 2566902049 OptSetDaac "Opt??;DAAC??";
CM_ SG_ 2566902049 OptSetRvsLmpFuncAct "??;ReverseLampFunctionActivation";
CM_ SG_ 2566902049 OptSetBladeAngSens "BladeAngleSensitivity";
CM_ SG_ 2566902049 OptSetRaiseDnSens "BladeRaiseDownSensitivity";
CM_ SG_ 2566902049 OptSetBladeTiltSens "BladeTiltSensitivity";
CM_ SG_ 2566902049 OptSetPchSlope "SetPitchSlope";
CM_ SG_ 2566902049 OptSetMrrHt "Opt??;MirrorHeater";
CM_ SG_ 2566902049 OptSetQckCoolMd "??;QuickCoolingMode";
CM_ SG_ 2566902049 RttOptSet "RotatingOpt????";
CM_ SG_ 2566902049 OptSetTrvlStrgtPdl "Opt??;TravelStraightPedal";
CM_ SG_ 2566902049 OptSetJoyType "??;JoystickType";
CM_ SG_ 2566902049 OptSetAttCtrl "Opt??;???????Opt;????????;Rotating";
CM_ SG_ 2566902049 OptSetTiltRttType "??;TiltRotatorType";
CM_ SG_ 2566902049 OptSetArtiBoom "Opt??;ArtiBoom";
CM_ SG_ 2566902049 OptSetDzBlade "Opt??;DozerBlade";
CM_ SG_ 2566902049 OptSetHhLift "Opt??;HighLift";
CM_ SG_ 2566902049 OptSetJoyPtnChange "Opt??;JoystickPatternChange";
CM_ SG_ 2566902049 OptSetTrqCvtLookUp "TorqueConvertorLockUp??";
CM_ SG_ 2566902049 OptSetDhlAuto "DHL????";
CM_ SG_ 2566902049 OptSet3DMG "Opt??;3DMG";
CM_ SG_ 2566902049 OptSetTrvlSwgAlm "??;TravelSwingAlarm??";
CM_ SG_ 2566902049 OptSetPrsCtrl "Opt??;???????";
CM_ SG_ 2566902049 OptSetRollOvr "Opt??;Rollover";
CM_ SG_ 2566902049 OptSet4WhlStr "Opt??;4WheelSteering";
CM_ SG_ 2566902049 OptSetSpool4 "Opt??;4THSPOOL";
CM_ SG_ 2566902049 OptSetConstFw "ConstantFlow??";
CM_ SG_ 2566902049 OptSetConstFwStep "ConstantFlowStep";
CM_ SG_ 2566902049 OptSetLisRvsOprSpd "LISReverseOperationVelocity";
CM_ SG_ 2566902049 OptSetFrCabLmp "Opt??;??CabinLamp";
CM_ SG_ 2566902049 OptSetOutRr "Opt??;OutriggerRR";
CM_ SG_ 2566902049 OptSetOutRlRrDz "Opt??;OutriggerRLorRearDozer";
CM_ SG_ 2566902049 OptSetOutFr "Opt??;OutriggerFR";
CM_ SG_ 2566902049 OptSetOutFlFrDz "Opt??;OutriggerFLorFrontDozer";
CM_ SG_ 2566902049 OptSetJoyStr "??????????";
CM_ SG_ 2566902049 OptSetRvsTrvlSpdLmt "??????";
CM_ SG_ 2566902049 OptSetEmcvBoomDnImpactPrevent "eMCV??;????????????";
CM_ SG_ 2566902049 OptSetEmcvBoomUpImpactPrevent "eMCV??;???????????";
CM_ SG_ 2566902049 OptSetEmcvBckDumpImpactPrevent "eMCV??;?????????????";
CM_ SG_ 2566902049 OptSetEmcvBckCrowdImpactPrevent "eMCV??;???????????????";
CM_ SG_ 2566902049 OptSetEmcvBckSens "eMCV??;BucketSensitivity";
CM_ SG_ 2566902049 OptSetEmcvBoomSens "eMCV??;BoomSensitivity";
CM_ SG_ 2566902049 OptSetEstrJoySens "E-SteeringJoystickSensitivity";
CM_ SG_ 2566902049 OptSetWrkLis "WorkingLISSet";
CM_ SG_ 2566902049 OptSetLcInVal "LCInputValue";
CM_ SG_ 2566902049 OptSetR2InVal "R2InputValue";
CM_ SG_ 2566902049 OptSetR1InVal "R1InputValue";
CM_ SG_ 2566902049 OptSetBckWghInVlue "BucketWeightInputValue";
CM_ SG_ 2566902049 OptSetBoomWghInVal "BoomWeightInputValue";
CM_ SG_ 2566902049 OptSetMaxCritWghVal "MaxCriterionWeightValue";
CM_ SG_ 2566902049 OptSetHalfCritWghVal "HalfCriterionWeightValue";
CM_ SG_ 2566902049 OptSetElecStr "Opt??;????";
CM_ SG_ 2566902049 OptSetRvsFan "Opt??;ReverseFan";
CM_ SG_ 2566902049 OptSetRcw "Opt??;RCW(RemovalCounterWeight)";
CM_ SG_ 2566902049 OptSetQckCoupler "Opt??;QuickCoupler";
CM_ SG_ 2566902049 OptSetTrvlOrSwgAlm "Opt??;Travel/SwingAlarm";
CM_ SG_ 2566902049 OptSetSmk "Opt??;SmartKey";
CM_ SG_ 2566902049 OptSetOwd "Opt??;OWD";
CM_ SG_ 2566902049 OptSetMchNameInit "MachineNameInitializing";
CM_ SG_ 2566902049 OptSetEmvcPmcv "Opt??;eMCV/pMCV";
CM_ SG_ 2566902049 OptSetAebReq "??:AEBRequest";
CM_ SG_ 2566902049 OptSetRvsFanOn "ReverseFan????";
CM_ SG_ 2566902049 OptSetRvsFanMd "ReverseFanMode??";
CM_ SG_ 2566902049 OptSetWhg "Opt??;Weighing";
CM_ SG_ 2566902049 OptSetHydrostatCalbCmd "HydrostatCalibrationCMD";
CM_ SG_ 2566902049 OptSetClutchCalbCmd "ClutchCalibrationCMD";
CM_ SG_ 2566902049 OptSetEmgMd "Activation;EmergencyMode";
CM_ SG_ 2566902049 OptSetCreepAct "Activation;CreepActivation";
CM_ SG_ 2566902049 OptSetThmbWhl "Opt??;ThumbWheel";
CM_ SG_ 2566902049 OptSetAxleOilCool "Opt??;AxleOilCooler";
CM_ SG_ 2566902049 OptSetAngSs "??:AngleSensorTuning";
CM_ SG_ 2566902049 OptSetBrkPdlCalb "??:BrakePedalCalibation";
CM_ SG_ 2566902049 OptSetCreepGr "CreepGear";
CM_ SG_ 2566902049 OptSetLisOprSpd "LISOperationVelocity";
CM_ SG_ 2566902049 OptSetRvsFanTm "ReverseFanTimeData";
CM_ SG_ 2566902049 OptSetLis "Opt??;LIS";
CM_ SG_ 2566902049 OptSetEmgStr "Opt??;EmergencySteering";
CM_ SG_ 2566902049 OptSetDhl "Opt??;DHL";
CM_ SG_ 2566902049 OptSetFnr2LeverType "2ndFnRLeverType";
CM_ SG_ 2566902049 OptSetTrmsLmtGr "TransmissionLimitGear";
CM_ SG_ 2566902049 OptSetTransBck "Opt??;TransparentBucket";
CM_ SG_ 2566902049 OptSetItgtFltBoom "Opt??;InteligentFloatingBoom";
CM_ SG_ 2566902049 OptSetBeacon "Opt??;Beacon";
CM_ SG_ 2566902049 OptSetMultiFuncBtnSel "MultiFunctionButtonSelect";
CM_ SG_ 2566902049 OptSetAutoIdle "AutoidleFunctionActivation";
CM_ SG_ 2566902049 MachineName "MachineName#1";
CM_ SG_ 2566902049 AutoIdleTm "AutoIldeTimedata";
CM_ SG_ 2566902049 BrkrOprTm "BreakerOperationTimedata";
CM_ SG_ 2566902049 OptSetAutoShutOffTm "AutoShutOffTimeData";
CM_ SG_ 2566902049 OptSetAutoShutOff "AutoShutOffEnableState";
CM_ SG_ 2566902049 OptSetAutoShutOffCancel "AutoShutOffCancelCMD";
CM_ SG_ 2566902049 OptSetAutoIdleRpmTmp "???AutoIdleRpm???????";
CM_ SG_ 2566902049 OptSetSpc "SPC??";
CM_ SG_ 2566902049 OptSetVoiceWrnCmd "??????CMD";
CM_ SG_ 2566902049 OptSetBoomSwgUSe "?????????";
CM_ SG_ 2566902049 OptSetTrvl2PmpCmbRls "??2??????";
CM_ SG_ 2566902049 OptSetTrvl1PmpUse "??1??????";
CM_ SG_ 2566902049 OptSetTrmsMaxSpdLmtChk "Opt??;TM????????";
CM_ SG_ 2566902049 OptSetHhAlt "Opt??;???Opt";
CM_ SG_ 2566902049 OptSetRipperOpt "Opt??;RipperOpt";
CM_ SG_ 2566902049 OptSetRttOpt "Opt??;RotatingOpt";
CM_ SG_ 2566902049 OptSetJoyThmbWhlRtt "???????????;Rotating";
CM_ SG_ 2566902049 OptSetJoyThmbWhlTw "???????????;2Way";
CM_ SG_ 2566902049 OptSetTw "2WayOpt????";
CM_ SG_ 2566902049 OptSetOptPdl "Opt??;Opt????";
CM_ SG_ 2566902049 OptSetAttPdlJoySel "Opt??;???????Opt;????????";
CM_ SG_ 2566902049 OptSet2Pmp "Opt??;2??Opt";
CM_ SG_ 2566902049 OptSetAttTw "Opt??;?????Opt;Twoway";
CM_ SG_ 2566902049 OptSetAttBrkr "Opt??;?????Opt;Breaker";
CM_ SG_ 2566902049 OptSetKeylessUse "Opt??:KeylessUse(?????)";
CM_ SG_ 2566902049 OptSetKeyless "Opt??;Keyless??";
CM_ SG_ 2566902049 OptSetWiper "Opt??;Wiper??";
CM_ SG_ 2566902049 OptSetTrvlMotOvrHtWrn "Opt??;????????";
CM_ SG_ 2566902049 OptSetFnrDefault "??;FNR??Default??";
CM_ SG_ 2566902049 OptSetFnrSel "??;FNR????";
CM_ SG_ 2566902049 OptSetCanTypeCmbSw "Opt??;CANtypeCombi.Switch";
CM_ SG_ 2566902049 UserDtIdx "UserDataIndex[0]";
CM_ SG_ 2566902049 VhcSerialNo "VehicleSerialNumber";
CM_ SG_ 2566902049 OptSetAttWghFactor "??;AttachmentWeightFactor";
CM_ SG_ 2566902049 OptSetCanTypeFuelSs "??;CANTypeFuelSensor";
CM_ SG_ 2566902049 OptSetSubBrkLmp "??;?????";
CM_ SG_ 2566902049 TiltRttMd "TiltRotatorMode";
CM_ SG_ 2566902049 USerLckUnlockSt "UserLOCK/UNLOCKState";
CM_ SG_ 2566902049 UserPw "UserPASSWORD";
CM_ SG_ 2566902049 OptWgh "Opt??;WeighingOption";
CM_ SG_ 2566902049 OptMC "Opt??;MCOption";
CM_ SG_ 2566902049 OptEgPostHtAct "Opt??;???????";
CM_ SG_ 2566902049 Opt2DMG "Opt??;2DMG";
CM_ SG_ 2566902049 AdminUse2 "?????????";
CM_ SG_ 2566902049 AdminUse1 "?????????";
CM_ SG_ 2566902049 AdminUse0 "?????????";
CM_ SG_ 2566902049 OwnerPw0UpTm "OwnerPASSWORD_????";
CM_ SG_ 2566902049 OwnerPw0Use "OwnerPASSWORD_???????";
CM_ SG_ 2566902049 OwnerPw0 "OwnerPASSWORD[0]";
CM_ BO_ 2566902305 "Filter & Oil Used Hour Information";
CM_ SG_ 2566902305 PmpDrvAirCtrgHr "PumpDriveAirCartridgeHour";
CM_ SG_ 2566902305 PmpDrvOilHr "PumpDriveOilHour";
CM_ SG_ 2566902305 HstFiltHr "HSTFilterHour";
CM_ SG_ 2566902305 AxleOilFiltHr "AxleOilFilterHour";
CM_ SG_ 2566902305 AtsSparkPlugHr "ATSSparkPlugHour";
CM_ SG_ 2566902305 EgCrkcaseBreatherElementHr "EngineCrankcaseBreatherElementHour";
CM_ SG_ 2566902305 AirCndFiltInHr "AirConditionerFilter(Inner)Hour";
CM_ SG_ 2566902305 AirCndFiltOutHr "AirConditionerFilter(Outer)Hour";
CM_ SG_ 2566902305 EgOilCtrCleanerFiltHr "EngineOilCentrifugalCleanerFilterHour";
CM_ SG_ 2566902305 DefBreatherFiltHr "DEF(AdBlue)BreatherFilterHour";
CM_ SG_ 2566902305 DefFiltHr "DEF(AdBlue)FilterHour";
CM_ SG_ 2566902305 OilBathPrecleanerHr "OilBathedPrecleanerHour";
CM_ SG_ 2566902305 DefHr "DEFUsedHour";
CM_ SG_ 2566902305 AxleOilHr "AxleOilUsedHour";
CM_ SG_ 2566902305 TrmsOilFiltHr "TransmissionOilFilterUsedHour";
CM_ SG_ 2566902305 TrmsOilHr "TransmissionOilUsedHour";
CM_ SG_ 2566902305 BreatherOilSepFiltHr "BreatherOilSeparatorFilterUsedHour";
CM_ SG_ 2566902305 DpfHr "DPFFilterUsedHour";
CM_ SG_ 2566902305 CoolHr "CoolantWaterUsedHour";
CM_ SG_ 2566902305 HydOilHr "Hyd.OilUsedHour";
CM_ SG_ 2566902305 EgOilHr "EngineOilUsedHour";
CM_ SG_ 2566902305 PilotFiltHr "PilotFilterUsedHour";
CM_ SG_ 2566902305 RetFiltHr "ReturnFilter(Hyd.OilFilter)UsedHour";
CM_ SG_ 2566902305 EgOilFiltHr "EngineOilFilterUsedHour";
CM_ SG_ 2566902305 AirCleanerHr "AirCleanerUsedHour";
CM_ SG_ 2566902305 FuleFiltHr "FuelFilterUsedHour";
CM_ BO_ 2566902561 "Filter & Oil Change Period Hour Information";
CM_ SG_ 2566902561 PmpDrvAirCtrgPrd "PeriodInfoData;PumpDriveAirCartridge";
CM_ SG_ 2566902561 PmpDrvOilPrd "PeriodInfoData;PumpDriveOil";
CM_ SG_ 2566902561 HstFiltPrd "PeriodInfoData;HSTFilter";
CM_ SG_ 2566902561 AxleOilFiltPrd "PeriodInfoData;AxleOilFilter";
CM_ SG_ 2566902561 AtsSparkPlugPrd "PeriodInfoData;ATSSparkPlug";
CM_ SG_ 2566902561 EgCrkcaseBreatherElementPrd "PeriodInfoData;EngineCrankcaseBreatherElement";
CM_ SG_ 2566902561 AirCndFiltInPrd "PeriodInfoData;AirConditionerFilter(Inner)";
CM_ SG_ 2566902561 AirCndFiltOutPrd "PeriodInfoData;AirConditionerFilter(Outer)";
CM_ SG_ 2566902561 EgOilCtrCleanerFiltPrd "PeriodInfoData;EngineOilCentrifugalCleanerFilter";
CM_ SG_ 2566902561 DefBreatherFiltPrd "PeriodInfoData;DEF(AdBlue)BreatherFilter";
CM_ SG_ 2566902561 DefFiltPrd "PeriodInfoData;DEF(AdBlue)Filter";
CM_ SG_ 2566902561 OilBathPrecleanerPrd "PeriodInfoData;OilBathedPrecleaner";
CM_ SG_ 2566902561 DefPrd "PeriodInfoData;DEF";
CM_ SG_ 2566902561 AxleOilPrd "PeriodInfoData;AxleOil";
CM_ SG_ 2566902561 TrmsOilFiltPrd "PeriodInfoData;TransmissionOilFilter";
CM_ SG_ 2566902561 TrmsOilPrd "PeriodInfoData;TransmissionOil";
CM_ SG_ 2566902561 BreatherOilSepFiltPrd "PeriodInfoData;BreatherOilSeparatorFilter";
CM_ SG_ 2566902561 DpfPrd "PeriodInfoData;DPFFilter";
CM_ SG_ 2566902561 CoolPrd "PeriodInfoData;CoolantWater";
CM_ SG_ 2566902561 HydOilPrd "PeriodInfoData;Hyd.Oil";
CM_ SG_ 2566902561 EgOilPrd "PeriodInfoData;EngineOil";
CM_ SG_ 2566902561 PilotFiltPrd "PeriodInfoData;PilotFilter";
CM_ SG_ 2566902561 RetFiltPrd "PeriodInfoData;Hyd.OilFilter";
CM_ SG_ 2566902561 EgOilFiltPrd "PeriodInfoData;EngineOilFilter";
CM_ SG_ 2566902561 AirCleanerPrd "PeriodInfoData;AirCleaner";
CM_ SG_ 2566902561 FuleFiltPrd "PeriodInfoData;FuelFilter";
CM_ BO_ 2566902817 "Excavator Analog Sensor Information";
CM_ SG_ 2566902817 BladeFanPchSsVlt "[???]BladeFANPitchSensorVoltage";
CM_ SG_ 2566902817 RamLckPrs "[???]RAMLOCKPRESSURESENSOR";
CM_ SG_ 2566902817 TrailerDnPilotPrs "[???]TrailerDownPilot??";
CM_ SG_ 2566902817 BoomHead2Prs "[???]BOOMHEAD2PRESSURESENSOR(Weighing)";
CM_ SG_ 2566902817 ArmRodPrs "[???]ARMRODPRESSURESENSOR(Weighing)";
CM_ SG_ 2566902817 ArmHEadPrs "[???]ARMHEADPRESSURESENSOR(Weighing)";
CM_ SG_ 2566902817 BoodRodPrs "[???]BOOMRODPRESSURESENSOR(Weighing)";
CM_ SG_ 2566902817 BoomHeadPrs "[???]BOOMHEADPRESSURESENSOR(Weighing)";
CM_ SG_ 2566902817 TpsVlt "[???]TPS??(??????)";
CM_ SG_ 2566902817 PchAng "[???]???";
CM_ SG_ 2566902817 RoolAng "[???]??";
CM_ SG_ 2566902817 TmsSecVlt "[??]TMS????";
CM_ SG_ 2566902817 VhcTrvlSpdSsFreq "[??]????????";
CM_ SG_ 2566902817 FlwCtrlLeverRh "[???]?????????(FlowControlLeverRH)";
CM_ SG_ 2566902817 FlwCtrlLeverLh "[???]?????????(FlowControlLeverLH)";
CM_ SG_ 2566902817 FlwCtrlAddLeverLh "[???]?????????????(FlowControlAddedLeverLH)";
CM_ SG_ 2566902817 BatVlt "[??]?????[???]";
CM_ SG_ 2566902817 AltVlt "[??]???????";
CM_ SG_ 2566902817 HydOilTmp "[??]?????[???]";
CM_ SG_ 2566902817 MecaCoolTmp "[???]?????(??????)";
CM_ SG_ 2566902817 GndSawDnSsPrs "[???]GroundSAWDownPRESSURESENSOR";
CM_ SG_ 2566902817 GndSawUpSsPrs "[???]GroundSAWUpPRESSURESENSOR";
CM_ SG_ 2566902817 WifSsVlt "[??]???????(WIFSensor)??";
CM_ SG_ 2566902817 FuelLv "[??]?????[???]";
CM_ SG_ 2566902817 FuelLvAddFuelTnk "[???]FuelLevelforAdditionalFuelTank";
CM_ SG_ 2566902817 AcpSsPrs "[???]ACPSensorPressure";
CM_ SG_ 2566902817 AccPdlVlt "[??]??????(?)";
CM_ SG_ 2566902817 EgCtrlDialVlt "[???]??????????[???]";
CM_ SG_ 2566902817 LsPrs "[???]LS??";
CM_ SG_ 2566902817 P3NegaconPrs "[???]P3?????";
CM_ SG_ 2566902817 RrNegaconPrs "[???]???????";
CM_ SG_ 2566902817 FrNegaconPrs "[???]????????";
CM_ SG_ 2566902817 PilotTrvlPtPrs "[???]?????(Pt)??";
CM_ SG_ 2566902817 PilotWrkPaPrs "[???]?????(Pa)??";
CM_ SG_ 2566902817 ArmLckPrs "[???]ARMLOCKPRESSURE";
CM_ SG_ 2566902817 BckCrowdConfPrs "[???]BUCKETCROWDCONF.PRESSURE";
CM_ SG_ 2566902817 ArmCrowdConfPrs "[???]ARMCROWDCONF.PRESSURE";
CM_ SG_ 2566902817 BoomUpConfPrs "[???]BOOMUPCONF.PRESSURE";
CM_ SG_ 2566902817 Opt3Prs "[???]Opt3??(????)";
CM_ SG_ 2566902817 Opt2Prs "[???]Opt2??(????)";
CM_ SG_ 2566902817 Opt1Prs "[???]Opt1??(????)";
CM_ SG_ 2566902817 SwgPrs "[???]????(????)";
CM_ SG_ 2566902817 TrvlLhPrs "[???]??????(????)";
CM_ SG_ 2566902817 TrvlRhPrs "[???]??????(????)";
CM_ SG_ 2566902817 BckDumpPrs "[???]??????(????)";
CM_ SG_ 2566902817 BckCrowdPrs "[???]????????(????)";
CM_ SG_ 2566902817 ArmOutPrs "[???]?????(????)";
CM_ SG_ 2566902817 ArmInPrs "[???]????(????)";
CM_ SG_ 2566902817 BoomDnPrs "[???]?????(????)";
CM_ SG_ 2566902817 BoomUpPrs "[???]????(????)";
CM_ SG_ 2566902817 EmgStrPrs "[???]EmergencySteeringSystemPressure";
CM_ SG_ 2566902817 Pmp3Ang "[???]3rd?????(????)";
CM_ SG_ 2566902817 RRpmpAng "[???]???????(????)";
CM_ SG_ 2566902817 FrPmpAng "[???]????????(????)";
CM_ SG_ 2566902817 FuelPrs "[???]????";
CM_ SG_ 2566902817 RcwStpVvPrs "[???]RCWStopValve??";
CM_ SG_ 2566902817 Pmp3Prs "[???]3rd????";
CM_ SG_ 2566902817 BoomCylPrs "[???]??????";
CM_ SG_ 2566902817 RrPmpPrs "[???]??????";
CM_ SG_ 2566902817 FrPmpPrs "[???]???????";
CM_ BO_ 2566903073 "Excavator Analog Actuator Information";
CM_ SG_ 2566903073 VariBladeFanEvc "[???]VariableBladeFANEPPR";
CM_ SG_ 2566903073 BoomSwgCcwEvc "[???]BOOMSWINGCCWEPPR";
CM_ SG_ 2566903073 BoomSwgCwEvc "[???]BOOMSWINGCWEPPR";
CM_ SG_ 2566903073 TrvlPmpEvc "[???]TRAVELPUMPEPPR";
CM_ SG_ 2566903073 Pmp3Evc "[???]3rd??EPRR";
CM_ SG_ 2566903073 DzDnEvc "[???]DOZERDOWNEPRR";
CM_ SG_ 2566903073 DzUpEvc "[???]DOZERUPEPRR";
CM_ SG_ 2566903073 ArtiBoomDnEvc "[???]Arti.BOOMDOWNEPPR";
CM_ SG_ 2566903073 ArtiBoomUpEvc "[???]Arti.BOOMUPEPPR";
CM_ SG_ 2566903073 SwgLhEvc "[???]SWINGLEFTEPPR";
CM_ SG_ 2566903073 SwgRhEvc "[???]SWINGRIGHTEPPR";
CM_ SG_ 2566903073 TrvlLhRvsEvc "[???]TRAVELLEFTREVERSEEPPR";
CM_ SG_ 2566903073 TrvlLhFwdEvc "[???]TRAVELLEFTFORWARDEPPR";
CM_ SG_ 2566903073 TrvlRhRvsEvc "[???]TRAVELRIGHTREVERSEEPPR";
CM_ SG_ 2566903073 TrvlRhFwdEvc "[???]TRAVELRIGHTFORWARDEPPR";
CM_ SG_ 2566903073 BckDumpEvc "[???]BUCKETDUMPEPPR";
CM_ SG_ 2566903073 BckCrowdEvc "[???]BUCKETCROWDEPPR";
CM_ SG_ 2566903073 Arm2DumpEvc "[???]ARM2DUMPEPPR";
CM_ SG_ 2566903073 Arm2CrowdEvc "[???]ARM2CROWDEPPR";
CM_ SG_ 2566903073 Arm1DumpEvc "[???]ARM1DUMPEPPR";
CM_ SG_ 2566903073 Arm1CrowdEvc "[???]ARM1CROWDEPPR";
CM_ SG_ 2566903073 Boom2UpEvc "[???]BOOM2UPEPPR";
CM_ SG_ 2566903073 Boom1DnEvc "[???]BOOM1DOWNEPPR";
CM_ SG_ 2566903073 Boom1UpEvc "[???]BOOM1UPEPPR";
CM_ SG_ 2566903073 ArmLckEvc "[???]ARMLOCKEPPR";
CM_ SG_ 2566903073 BckCrowdConfEvc "[???]BUCKETCROWDCONF.EPPR";
CM_ SG_ 2566903073 ArmCrowdConfEvc "[???]ARMCROWDCONF.EPPR";
CM_ SG_ 2566903073 BoomUpConfEvc "[???]BOOMUPCONF.EPPR";
CM_ SG_ 2566903073 BypassCutOffBEvc "[???]BYPASSCUT-OFF(B)EPPR";
CM_ SG_ 2566903073 BypassCutOffAEvc "[???]BYPASSCUT-OFF(A)EPPR";
CM_ SG_ 2566903073 Trvl2PmpCmbEvc "[???]??II????????(?)";
CM_ SG_ 2566903073 TrvlFwdEvc "[???]??????????(????)";
CM_ SG_ 2566903073 PrsCtrl2Evc "[???]??????????2";
CM_ SG_ 2566903073 PrsCtrl1Evc "[???]??????????1";
CM_ SG_ 2566903073 RttCcwEvc "[???]??????????(CCW)";
CM_ SG_ 2566903073 RttCwEvc "[???]??????????(CW)";
CM_ SG_ 2566903073 TwCloseEvc "[???]2-way??????(Close)";
CM_ SG_ 2566903073 TwOpenEvc "[???]2-way??????(Open)";
CM_ SG_ 2566903073 FlwCtrlEvc "[???]??????????";
CM_ SG_ 2566903073 CoolFanEvc "[??]?????????";
CM_ SG_ 2566903073 PmpElecEvc "[???]????????(????)";
CM_ SG_ 2566903073 Pmp1Evc "[???]????????1";
CM_ BO_ 2566903329 "Excavator Digital Sensor Information";
CM_ SG_ 2566903329 MainStRpmpPrsSw "MainSteeringPumpPressureSwitch";
CM_ SG_ 2566903329 GndSawInitSw "[???]GroundSawinitialswitch";
CM_ SG_ 2566903329 FanErrSig "FanErrorSignal";
CM_ SG_ 2566903329 HydWakeUpSw "HydraulicWakeUpSwitch";
CM_ SG_ 2566903329 EmgStpSw "EmergencyStopSwitch";
CM_ SG_ 2566903329 HhVltChgSw "HighVoltageChargingSwitch";
CM_ SG_ 2566903329 PrkBrkPrsSw "ParkingBrakePressureSwitch";
CM_ SG_ 2566903329 RamLckRvsSw "RamLockReverseSwitch";
CM_ SG_ 2566903329 AirCompPrsSw "AirCompressorPressureSwitch";
CM_ SG_ 2566903329 Mg2DJoyTrigSw "2DMGJoystickTriggerSwitch";
CM_ SG_ 2566903329 KeySwBr "KeySwitchBR";
CM_ SG_ 2566903329 TwSwSelSw "2waySwitchingSelectSwitch";
CM_ SG_ 2566903329 DzOutSw "Dozer/OutriggerSwitch";
CM_ SG_ 2566903329 MrrHtSw "MirrorHeaterSwitch";
CM_ SG_ 2566903329 SwgAlignSw "SwingAlignSwitch";
CM_ SG_ 2566903329 MultiFuncSw "MultiFunctionSwitch";
CM_ SG_ 2566903329 AutoDigSw "AutoDiggingSwitch";
CM_ SG_ 2566903329 TrvlPmpHhSpdSw "TravelPumpHighSpeedSwitch";
CM_ SG_ 2566903329 DoorSw "DOORSswitch";
CM_ SG_ 2566903329 RrAxleRhHallSsSw "RearAxleRHHallSensorSwitch";
CM_ SG_ 2566903329 RrAxleLhHallSsSw "RearAxleLHHallSensorSwitch";
CM_ SG_ 2566903329 FrAxleHallSsSw "FrontAxleHallSensorSwitch";
CM_ SG_ 2566903329 QckCouplerRhSw "RightQuickCouplerSwitch";
CM_ SG_ 2566903329 QckCouplerLhSw "LeftQuickCouplerSwitch";
CM_ SG_ 2566903329 PowMdSw "PowerModeSwitch";
CM_ SG_ 2566903329 WrkMdSw "WorkModeSwitch";
CM_ SG_ 2566903329 AuxMdSelSw "AuxiliaryModeSelectSwitch";
CM_ SG_ 2566903329 SwgBrkRlsSw "SwingBrakeReleaseSwitch";
CM_ SG_ 2566903329 BrkrFltSw "BreakerFloatSwitch";
CM_ SG_ 2566903329 SwgPriSw "SwingPrioritySwitch";
CM_ SG_ 2566903329 RttCwSw "RotatingCWSwitch";
CM_ SG_ 2566903329 RttCcwSw "RotatingCCWSwitch";
CM_ SG_ 2566903329 WiperWasherSw "????????";
CM_ SG_ 2566903329 WiperContSw "????????";
CM_ SG_ 2566903329 Wiper2StepSw "???2????";
CM_ SG_ 2566903329 Wiper1StepSw "???1????";
CM_ SG_ 2566903329 TmsSt "TMS????";
CM_ SG_ 2566903329 ArtiBoomPrsSw "Arti-Boom?????";
CM_ SG_ 2566903329 CoolLvSw "????????";
CM_ SG_ 2566903329 RttOprSw "RotatingOperatingSwitch";
CM_ SG_ 2566903329 TwCloseOprSw "2-WayCloseOperatingSwitch";
CM_ SG_ 2566903329 TwOpenOprSw "2-WayOpenOperatingSwitch";
CM_ SG_ 2566903329 RcwCloseSw "RCW?????";
CM_ SG_ 2566903329 RcwOprSw "RCW?????";
CM_ SG_ 2566903329 EmgEgStpSw "?????????(EmergencyEngineStopSwitch)";
CM_ SG_ 2566903329 OwOptPdlPrsSw "Opt???????(1way)";
CM_ SG_ 2566903329 SpcSw "SPC???(SPCSwitch)";
CM_ SG_ 2566903329 IhbSw "InhibitSwitch(added-11.09.30)";
CM_ SG_ 2566903329 TrvlAlmSelSw "?????????(added-11.07.28)";
CM_ SG_ 2566903329 SwgAlmSelSw "?????????(added-11.07.28)";
CM_ SG_ 2566903329 EmgStrSw "EmergencySteering???";
CM_ SG_ 2566903329 HhBeamSw "HighBeam???";
CM_ SG_ 2566903329 StpLmp "????(?)";
CM_ SG_ 2566903329 AccPdlSw "???????(?)";
CM_ SG_ 2566903329 BrkPrsSw "?????????(?)";
CM_ SG_ 2566903329 Cruise "???(?)";
CM_ SG_ 2566903329 EgOilPrsSw "?????????";
CM_ SG_ 2566903329 WrkPxPrsSw "???????(Px)";
CM_ SG_ 2566903329 TrvlPyPrsSw "???????(Py)";
CM_ SG_ 2566903329 IgnSw "?????";
CM_ SG_ 2566903329 RamLckAutoSw "????????";
CM_ SG_ 2566903329 PreHt "??";
CM_ SG_ 2566903329 WifWrn "???????";
CM_ SG_ 2566903329 SwgPrsSw "???????";
CM_ SG_ 2566903329 JoyPtnBhl "??????(BHL)";
CM_ SG_ 2566903329 JoyPtnIso "??????(ISO)";
CM_ SG_ 2566903329 RvsFanSw "???????";
CM_ SG_ 2566903329 TwOptPdlPrsSw "Opt???????(2way)";
CM_ SG_ 2566903329 BrkOilPrsWrn "??????????";
CM_ SG_ 2566903329 OwdWrnSelSw "??????????";
CM_ SG_ 2566903329 RetFiltWrn "??????";
CM_ SG_ 2566903329 PilotFiltWrn "???????";
CM_ SG_ 2566903329 AirCleanerWrn "???????";
CM_ SG_ 2566903329 PilotCutOffSw "?????????";
CM_ SG_ 2566903329 ItgtBoomSw "????????-->?????????";
CM_ SG_ 2566903329 OneTouchRedSpdSw "????????";
CM_ SG_ 2566903329 RamLckSw "??????(?)";
CM_ SG_ 2566903329 PrkSw "?????(?)";
CM_ SG_ 2566903329 AirCndSw "??????";
CM_ SG_ 2566903329 JoyDirSelSw "?????????(?)";
CM_ SG_ 2566903329 TrvlBwdSw "?????(?)";
CM_ SG_ 2566903329 TrvlNtrlSw "?????(?)";
CM_ SG_ 2566903329 TrvlFwdSw "?????(?)";
CM_ SG_ 2566903329 HhSpdSelSw "???????(?)";
CM_ SG_ 2566903329 LwSpdSelSw "???????(?)";
CM_ SG_ 2566903329 InchingSelSw "???????(?)";
CM_ SG_ 2566903329 QckCoupler "????";
CM_ SG_ 2566903329 TwSelSw "2-way?????";
CM_ SG_ 2566903329 OnwWaySelSw "1-way?????";
CM_ SG_ 2566903329 WrkLmpSw "??????";
CM_ SG_ 2566903329 AutoTrvl2SpdSw "????II?(???)";
CM_ SG_ 2566903329 Trvl2SpdSelSw "??II???(???)";
CM_ SG_ 2566903329 TrvlSelSw "???????(?)";
CM_ SG_ 2566903329 BrkrSw "?????????";
CM_ SG_ 2566903329 PwrMaxSw "?????";
CM_ SG_ 2566903329 Alt "?????";
CM_ BO_ 2566903585 "Excavator Digital Actuator Information";
CM_ SG_ 2566903585 EmgStrSv "EmergencySteeringSystem?????";
CM_ SG_ 2566903585 TrvlRhPilotCutOffSv "[???]TRAVEL_RHPILOT-CUTS/V";
CM_ SG_ 2566903585 GndSawMdChangeRly "[???]GroundSawModeChangeRelay";
CM_ SG_ 2566903585 HvChgSig "HVChargingSignal";
CM_ SG_ 2566903585 FanPwmSig "FANPWMSignal";
CM_ SG_ 2566903585 TrkExpationSv "TrackExpationS/V";
CM_ SG_ 2566903585 HhVltMainRly "HighVoltageMainRelay";
CM_ SG_ 2566903585 HhVltPreChgRly "HighVoltagePrechargeRelay";
CM_ SG_ 2566903585 PilotBz "PilotBuzzer";
CM_ SG_ 2566903585 QckChgInd "QuickChargingIndicator";
CM_ SG_ 2566903585 QckChgRly "QuickChargingRelay";
CM_ SG_ 2566903585 NormChgInd "NormalChargingIndicator";
CM_ SG_ 2566903585 LwVltMainRly "LowVoltageMainRelay";
CM_ SG_ 2566903585 BoomSwgSelRly "BoomSwingSelectRelay";
CM_ SG_ 2566903585 PmpDeratSv "PumpDeratingS/V";
CM_ SG_ 2566903585 PrkBrkRly "ParkingBrakeRelay";
CM_ SG_ 2566903585 RvsLmpRly "ReverseLampRelay";
CM_ SG_ 2566903585 AirCompRly "AirCompressorRelay";
CM_ SG_ 2566903585 CabLmpRly "CabinLampRelay";
CM_ SG_ 2566903585 AvmWrnSig "AVMWarningSignal";
CM_ SG_ 2566903585 WrkLmpRly "WorkingLampRelay";
CM_ SG_ 2566903585 AirCondCompStpSig "A/CCompressorStopSignal";
CM_ SG_ 2566903585 Chmsl "CHMSL";
CM_ SG_ 2566903585 BoomSusRodSv "BoomSuspensionRodS/V";
CM_ SG_ 2566903585 BoomSusHedSv "BoomSuspensionHeadS/V";
CM_ SG_ 2566903585 MrrHt "MirrorHeater";
CM_ SG_ 2566903585 ClearLmp "ClearanceLamp";
CM_ SG_ 2566903585 HhHeadLmp "HighHeadLamp";
CM_ SG_ 2566903585 LwHeadLmp "LowHeadLamp";
CM_ SG_ 2566903585 FineSwgSv "FineSwingS/N";
CM_ SG_ 2566903585 TurnRhSigLmp "RightTurnSignalLamp";
CM_ SG_ 2566903585 TurnLhSigLmp "LeftTurnSignalLamp";
CM_ SG_ 2566903585 BeaconRly "?????";
CM_ SG_ 2566903585 LightRly "?????";
CM_ SG_ 2566903585 LmpRly "?????";
CM_ SG_ 2566903585 RamLckSv "RAMLockS/V";
CM_ SG_ 2566903585 LwSpdTrvlSv "?????????";
CM_ SG_ 2566903585 TrvlPmpHhSpd2Sv "TravelPumpHighSpeed2S/V";
CM_ SG_ 2566903585 TrvlPmpHhSpd1Sv "TravelPumpHighSpeed1S/V";
CM_ SG_ 2566903585 WiperWasherRly "????????";
CM_ SG_ 2566903585 WiperRly "??????";
CM_ SG_ 2566903585 AutoShutOffRly "AutoShutOff???";
CM_ SG_ 2566903585 AirHtRly "AirHeater???";
CM_ SG_ 2566903585 GlowPlugPreHhRly2 "GlowPlug?????2";
CM_ SG_ 2566903585 GlowPlugPreHhRly1 "GlowPlug?????1";
CM_ SG_ 2566903585 HhSpdRly "?????";
CM_ SG_ 2566903585 LwSpdRly "?????";
CM_ SG_ 2566903585 InchingRly "?????";
CM_ SG_ 2566903585 SpareRly "?????";
CM_ SG_ 2566903585 BackBzRly "??????";
CM_ SG_ 2566903585 StartRly "??????";
CM_ SG_ 2566903585 AutoBrkSv "AutoBrakeS/V";
CM_ SG_ 2566903585 PilotCutOffSv "PILOTCUTOFFS/V";
CM_ SG_ 2566903585 McvEpprCutOffSv "McvEpprCutOffS/V";
CM_ SG_ 2566903585 BsSpoolSc "BsSpoolS/V";
CM_ SG_ 2566903585 QckCouplerSv "QuickCouplerS/V";
CM_ SG_ 2566903585 FreeBoomDnSv "FreeBoomDwS/V";
CM_ SG_ 2566903585 FreeBoomUpSv "FreeBoomUpS/V";
CM_ SG_ 2566903585 TrvlStrgtSv "TravelStraightS/V";
CM_ SG_ 2566903585 RttCcwSv "RotatingCcwS/V";
CM_ SG_ 2566903585 RttCwSv "RotatingCwS/V";
CM_ SG_ 2566903585 Trvl2PmpCmbSv "??IIpump???????";
CM_ SG_ 2566903585 OptPdlSaftySv "Opt?????????";
CM_ SG_ 2566903585 ForceRgnSv "?????????";
CM_ SG_ 2566903585 TwOprSv "??????????(OnlyDX)";
CM_ SG_ 2566903585 UnloadSv "????????";
CM_ SG_ 2566903585 TwRhCloseSv "2-WayRH-CLOSES/V";
CM_ SG_ 2566903585 TwRhOpenSv "2-WayRH-OPENS/V";
CM_ SG_ 2566903585 SwgBrkRelSv "?????????????(????)";
CM_ SG_ 2566903585 BypassCutOffSv "????????????(????)";
CM_ SG_ 2566903585 RwdSv "???????(?)";
CM_ SG_ 2566903585 FwdSv "???????(?)";
CM_ SG_ 2566903585 CruiseSv "????????(?)";
CM_ SG_ 2566903585 TwoPmpSelSv "2?????????";
CM_ SG_ 2566903585 FanRvsSv "????????";
CM_ SG_ 2566903585 BrkrSelSv "???????????";
CM_ SG_ 2566903585 HhSpdTrvlSv "?????????";
CM_ SG_ 2566903585 PowMaxSv "???????";
CM_ SG_ 2566903585 BrkrOprSv "???????????";
CM_ BO_ 2566903841 "Wheel loader Analog Sensor Information";
CM_ SG_ 2566903841 TmsSecVlt "[??]TMS????";
CM_ SG_ 2566903841 RsvJoy1GripYPos "Reserved-Joystick1GripY-AxisPosition";
CM_ SG_ 2566903841 Joy1GripYPos "Joystick1GripY-AxisPosition";
CM_ SG_ 2566903841 RsvJoy1YPos "Reserved-Joystick1Y-AxisPosition";
CM_ SG_ 2566903841 Joy1YPos "Joystick1Y-AxisPosition";
CM_ SG_ 2566903841 RsvJoy1XPos "Reserved-Joystick1X-AxisPosition";
CM_ SG_ 2566903841 Joy1XPos "Joystick1X-AxisPosition";
CM_ SG_ 2566903841 EmcvLeverOptB "[???]EMCVLeverOption(B)";
CM_ SG_ 2566903841 EmcvLeverOptA "[???]PMCVLeverOption";
CM_ SG_ 2566903841 EmcvLeverBckB "[???]EMCVLeverBucket(B)";
CM_ SG_ 2566903841 EmcvLeverBckA "[???]EMCVLeverBucket(A)";
CM_ SG_ 2566903841 EmcvLeverBoomB "[???]EMCVLeverBoom(B)";
CM_ SG_ 2566903841 EmcvLeverBoomA "[???]EMCVLeverBoom(A)";
CM_ SG_ 2566903841 ElecStrVv "[???]ElecSteerValve";
CM_ SG_ 2566903841 ElecStrLeverB "[???]ElecSteerLever(B)";
CM_ SG_ 2566903841 ElecStrLeverA "[???]Elec.Steer.Lever(A)";
CM_ SG_ 2566903841 AcpSsPrs "ACPsensorPressure";
CM_ SG_ 2566903841 BatTmp "[??]?????[???]";
CM_ SG_ 2566903841 AltTmp "[??]???????";
CM_ SG_ 2566903841 AxleOilTmp "[???]AxleOilTemp";
CM_ SG_ 2566903841 HydOilTmp "[??]?????[???]";
CM_ SG_ 2566903841 CoolTmp "[???]?????(??????)";
CM_ SG_ 2566903841 OpsSsVlt "OPS??(OPSSensor)??";
CM_ SG_ 2566903841 WifSsVlt "[??]???????(WIFSensor)??";
CM_ SG_ 2566903841 FuelLv "[??]?????[???]";
CM_ SG_ 2566903841 BrkPdlB "[???]BrakePedal(B)";
CM_ SG_ 2566903841 BrkPdlA "[???]BrakePedal(A)";
CM_ SG_ 2566903841 AccPdlVlt "[??]??????(?)";
CM_ SG_ 2566903841 CtlLsPrs "[?????]LS??";
CM_ SG_ 2566903841 CtlTowSpdPrs "[?????]TowSpeed??";
CM_ SG_ 2566903841 AngSsBckB "[???]AngleSensorBucket(B)";
CM_ SG_ 2566903841 AngSsBckA "[???]AngleSensorBucket(A)";
CM_ SG_ 2566903841 AngSsBoomB "[???]AngleSensorBoom(B)";
CM_ SG_ 2566903841 AngSsBoomA "[???]AngleSensorBoom(A)";
CM_ SG_ 2566903841 CtlBckLoadPrs "[?????]??????";
CM_ SG_ 2566903841 CtlEgCtrlDialVlt "[?????]??????????";
CM_ SG_ 2566903841 PrkBrkPrs "????????";
CM_ SG_ 2566903841 FanMotPrs "[???]?????";
CM_ SG_ 2566903841 BrkOilPrs "[???]????????";
CM_ SG_ 2566903841 StrPrs "[???]????";
CM_ SG_ 2566903841 BoomRodPrs "[???]?????";
CM_ SG_ 2566903841 BooHeadPrs "[???]?????";
CM_ SG_ 2566903841 MainPrs "[???]????";
CM_ BO_ 2566904097 "Wheel loader Analog Actuator Information";
CM_ SG_ 2566904097 CacFanCtrl "CACFANCONTROL";
CM_ SG_ 2566904097 CdsFanCtrl "CONDENSORFANCONTROL";
CM_ SG_ 2566904097 RipperDnEvc "P/VBRIPPER;DOWN";
CM_ SG_ 2566904097 RipperUpEvc "P/VRIPPER;UP";
CM_ SG_ 2566904097 BladeAngLhEvc "P/VBLADE;ANGLELEFT";
CM_ SG_ 2566904097 BladeAngRhEvc "P/VBLADE;ANGLERIGHT";
CM_ SG_ 2566904097 BladeDnEvc "P/VBLADE;DOWN";
CM_ SG_ 2566904097 BladeRaiseEvc "P/VBLADE;RAISE";
CM_ SG_ 2566904097 BladeTiltLhEvc "P/VBLADE;TILTLEFT";
CM_ SG_ 2566904097 BladeTiltRhEvc "P/VBLADE;TILTRIGHT";
CM_ SG_ 2566904097 Spool4BEvc "4THSPOOLB??????";
CM_ SG_ 2566904097 Spool4AEvc "4THSPOOLA??????";
CM_ SG_ 2566904097 Opt2Evc "Option2??????";
CM_ SG_ 2566904097 Opt1Evc "Option1??????";
CM_ SG_ 2566904097 BckDumpEvc "BucketDump??????";
CM_ SG_ 2566904097 BoomCrowdEvc "BucketCrowd??????";
CM_ SG_ 2566904097 BoomFltEvc "BoomFloat??????";
CM_ SG_ 2566904097 BoomRaiseEvc "BoomRaise??????";
CM_ SG_ 2566904097 FanCtrlEvc "??????????";
CM_ BO_ 2566904353 "Wheel loader Digital Sensor Information";
CM_ SG_ 2566904353 OpsSw "OPSSwitch";
CM_ SG_ 2566904353 HhFlowPinK "HighFlowPinK";
CM_ SG_ 2566904353 HhFlowPinN "HighFlowPinN";
CM_ SG_ 2566904353 DustInd "DustIndicator";
CM_ SG_ 2566904353 FrDoorSw "FrontDoorSwitch";
CM_ SG_ 2566904353 ArmRestLhSw "ArmRestSwitch(LH)";
CM_ SG_ 2566904353 ArmRestRhSw "ArmRestSwitch(RH)";
CM_ SG_ 2566904353 Spool3LeverSw "3rdSpoolLeverSwitch";
CM_ SG_ 2566904353 BckLeverSw "BucketLeverSwitch";
CM_ SG_ 2566904353 EgOilPrsSw "ENGINEOILPRESSURESWITCH";
CM_ SG_ 2566904353 HydLckoutSw "HYDRAULICLOCKOUTSWITCH";
CM_ SG_ 2566904353 TractionCtrlSw "TRACTIONCONTROLSWITCH";
CM_ SG_ 2566904353 AirCleanSw "????????";
CM_ SG_ 2566904353 RetFiltSw "ReturnFilter???";
CM_ SG_ 2566904353 QckCouperLckSw "QuickCouplerLock???";
CM_ SG_ 2566904353 DnShftSw "DownShift???";
CM_ SG_ 2566904353 PreHt "??";
CM_ SG_ 2566904353 Joy1XDetentPosSt "Joystick1X-AxisDetentPositionStatus";
CM_ SG_ 2566904353 Joy1YDetentPosSt "Joystick1Y-AxisDetentPositionStatus";
CM_ SG_ 2566904353 IhbSw "InhibitSwitch(added-11.09.30)";
CM_ SG_ 2566904353 HstOilFiltWrn "HSTOilFilterWarning";
CM_ SG_ 2566904353 GrboxOvrTmp "GearboxOverTemperature";
CM_ SG_ 2566904353 AgsLmp "AGSLamp";
CM_ SG_ 2566904353 QckCouplerInitSw "QuickCouplerInitiate???";
CM_ SG_ 2566904353 PrkSw "Parking???";
CM_ SG_ 2566904353 SeatBeltSw "SeatBelt???";
CM_ SG_ 2566904353 ReDefrstSw "ReDefrst???";
CM_ SG_ 2566904353 HormSw "Horn???";
CM_ SG_ 2566904353 Fnr2ActSw "2ndFNRActivate???";
CM_ SG_ 2566904353 RearWiperStpSw "RearWiperStopSignal";
CM_ SG_ 2566904353 FrWiperStpSig "FrontWiperStopSignal";
CM_ SG_ 2566904353 DpfForceRgnSw "DPFForcedRegen???";
CM_ SG_ 2566904353 EmgStrPrsSw "EmergencySteerPressure???";
CM_ SG_ 2566904353 MainStrPrsSw "MainSteerPressure???";
CM_ SG_ 2566904353 AccPdlKd "AccelPedalKD";
CM_ SG_ 2566904353 AccPdlIvs "AccelPedalIVS";
CM_ SG_ 2566904353 PrkBrkPrsSw "ParkingBrakePressure???";
CM_ SG_ 2566904353 CoolLv "CoolantLevel";
CM_ SG_ 2566904353 WghCntSw "WeighingCount???";
CM_ SG_ 2566904353 EmgStpSw "EMERGENCYSTOP???";
CM_ SG_ 2566904353 DhlManSw "DHLManual???";
CM_ SG_ 2566904353 FnrR3 "3rdFNR(R)";
CM_ SG_ 2566904353 FnrN3 "3rdFNR(N)";
CM_ SG_ 2566904353 FnrF3 "3rdFNR(F)";
CM_ SG_ 2566904353 FnrR2 "2ndFNR(R)";
CM_ SG_ 2566904353 FnrN2 "2ndFNR(N)";
CM_ SG_ 2566904353 FnrF2 "2ndFNR(F)";
CM_ SG_ 2566904353 FnrR1 "1stFNR(R)";
CM_ SG_ 2566904353 FnrN1 "1stFNR(N)";
CM_ SG_ 2566904353 FnrF1 "1stFNR(F)";
CM_ SG_ 2566904353 StartBrSw "\"Br\"???(Starter)";
CM_ SG_ 2566904353 StartAccSw "\"Acc\"???(Starter)";
CM_ SG_ 2566904353 StartCSw "\"C\"???(Starter)";
CM_ SG_ 2566904353 PilotCutOffSw "PilotCutOff???";
CM_ SG_ 2566904353 ArmRestCutOffSw "ArmRestCutOff???";
CM_ SG_ 2566904353 ElecStrSelSw "ElecSteerSelect???&3rdSelect???";
CM_ BO_ 2566904372 "Soft";
CM_ BO_ 2566904609 "Wheel loader Digital Actuator Information";
CM_ SG_ 2566904609 Aux8Rly "Aux8???";
CM_ SG_ 2566904609 Aux7Rly "Aux7???";
CM_ SG_ 2566904609 Aux6Rly "Aux6???";
CM_ SG_ 2566904609 Aux5Rly "Aux5???";
CM_ SG_ 2566904609 Aux4Rly "Aux4???";
CM_ SG_ 2566904609 Aux3Rly "Aux3???";
CM_ SG_ 2566904609 AuxShutOffSv "AuxShutOff?????";
CM_ SG_ 2566904609 PilotCutOffSv "PilotCutOff?????";
CM_ SG_ 2566904609 FrWiperRly "FrontWiper???";
CM_ SG_ 2566904609 SideWasherRly "SideWasher???";
CM_ SG_ 2566904609 UreaSuperChgWrnSig "UREASUPERCHARGINGWARNINGSIGNAL";
CM_ SG_ 2566904609 EgRunOutSig "Enginerunningoutputsignal";
CM_ SG_ 2566904609 SideWiperRly "SideWiper???";
CM_ SG_ 2566904609 FrWhaserRly "FrontWasher???";
CM_ SG_ 2566904609 FrWiperLwSigRly "FrontWiperLowSpeed???";
CM_ SG_ 2566904609 FrWiperHhSpdRly "FrontWiperHighSpeed???";
CM_ SG_ 2566904609 LwBeamRly "LowBeam???";
CM_ SG_ 2566904609 HhBeamRly "HighBeam???";
CM_ SG_ 2566904609 IllmLmpRly "IlluminationLamp???";
CM_ SG_ 2566904609 RttBeaconRly "RotatingBeacon???";
CM_ SG_ 2566904609 TurnSigRhRly "TURNSIGNALRH???";
CM_ SG_ 2566904609 TurnSigLhRly "TURNSIGNALLH???";
CM_ SG_ 2566904609 HormRly "HORN???";
CM_ SG_ 2566904609 AccRly "ACC???";
CM_ SG_ 2566904609 RrWinHtRly "RearWindowHeating???";
CM_ SG_ 2566904609 AutoShutOffRly "AUTOSHUTOFF???";
CM_ SG_ 2566904609 BackUpBzRly "BackUpBuzzer???";
CM_ SG_ 2566904609 MrrHtRly "MirrorHeater???";
CM_ SG_ 2566904609 HuelHtRly "FuelHeater???";
CM_ SG_ 2566904609 GlowPlugFuelRly "GlowPlugFuel???";
CM_ SG_ 2566904609 GlowPlugRly "GlowPlug???";
CM_ SG_ 2566904609 EmgStrTestRly "EMERGENCYSTEERINGTEST???";
CM_ SG_ 2566904609 RrWasherRly "RearWasher???";
CM_ SG_ 2566904609 RrWiperRly "Rearwiper???";
CM_ SG_ 2566904609 RrWrkCabLmpRly "Rearworkinglamp???(Cabin)";
CM_ SG_ 2566904609 RrWrkRadLmpRly "Rearworkinglamp???(Radiator)";
CM_ SG_ 2566904609 FrWrkLmpRly "Frontworkinglamp???";
CM_ SG_ 2566904609 ElecStrSaftyRly "ElecSteerSafety???";
CM_ SG_ 2566904609 PilotBzRly "PilotBuzzer???";
CM_ SG_ 2566904609 LisActRly "LISACTIVE???";
CM_ SG_ 2566904609 HstCutOffRhSv "HSTCutoffRH?????";
CM_ SG_ 2566904609 HstCutOffLhSv "HSTCutoffLH?????";
CM_ SG_ 2566904609 BckMagnet "BucketMagnet";
CM_ SG_ 2566904609 BoomMagnet "BoomMagnet";
CM_ SG_ 2566904609 HstCutOffSv "HSTCUTOFFS/V";
CM_ SG_ 2566904609 HydCutOffSv "HYDRAULICCUTOFFS/V";
CM_ SG_ 2566904609 StartRly "Starter???";
CM_ SG_ 2566904609 QckCouplerRly "QuickCoupler???";
CM_ SG_ 2566904609 EgStpRly "EningeStop???";
CM_ SG_ 2566904609 PrkBrkRlsSv "ParkingBrakeRelease?????";
CM_ SG_ 2566904609 EscortWrkLmpRly "EscortWorkingLamp???";
CM_ SG_ 2566904609 AxleOilCoolSv "AxleOilCooler?????";
CM_ SG_ 2566904609 UnloadSv "Unloading?????";
CM_ SG_ 2566904609 BrkChgSv "BrakeCharge?????";
CM_ SG_ 2566904609 RvsFanSV "ReverseFAN?????";
BA_DEF_ BO_  "VFrameFormat" ENUM  "StandardCAN","ExtendedCAN","reserved","J1939PG";
BA_DEF_ BO_  "Channel" STRING ;
BA_DEF_ BO_  "VssMsg" STRING ;
BA_DEF_ SG_  "VssSig" STRING ;
BA_DEF_ BO_  "GenMsgCycleTime" INT 0 65535;
BA_DEF_DEF_  "VFrameFormat" "J1939PG";
BA_DEF_DEF_  "Channel" "";
BA_DEF_DEF_  "VssMsg" "";
BA_DEF_DEF_  "VssSig" "";
BA_DEF_DEF_  "GenMsgCycleTime" 0;
BA_ "GenMsgCycleTime" BO_ 2566893620 100;
BA_ "VssMsg" BO_ 2566893620 "Mch.SMK.SMKC";
BA_ "Channel" BO_ 2566893620 "can1";
BA_ "VssMsg" BO_ 2566893876 "Mch.SMK.SMKFOB";
BA_ "Channel" BO_ 2566893876 "can1";
BA_ "VssMsg" BO_ 2566894154 "Mch.TMS.TMSSMKD";
BA_ "Channel" BO_ 2566894154 "can1";
BA_ "GenMsgCycleTime" BO_ 2566894388 1000;
BA_ "VssMsg" BO_ 2566894388 "Mch.SMK.SMKI";
BA_ "Channel" BO_ 2566894388 "can1";
BA_ "GenMsgCycleTime" BO_ 2566896131 100;
BA_ "VssMsg" BO_ 2566896131 "Mch.TCU.TM5V";
BA_ "Channel" BO_ 2566896131 "can1";
BA_ "GenMsgCycleTime" BO_ 2566896387 100;
BA_ "VssMsg" BO_ 2566896387 "Mch.TCU.TM4V";
BA_ "Channel" BO_ 2566896387 "can1";
BA_ "VssMsg" BO_ 2566896643 "Mch.TCU.TCUHG";
BA_ "Channel" BO_ 2566896643 "can1";
BA_ "GenMsgCycleTime" BO_ 2365570307 100;
BA_ "VssMsg" BO_ 2365570307 "Mch.TCU.TM1V";
BA_ "Channel" BO_ 2365570307 "can1";
BA_ "GenMsgCycleTime" BO_ 2566897155 100;
BA_ "VssMsg" BO_ 2566897155 "Mch.TCU.TM2V";
BA_ "Channel" BO_ 2566897155 "can1";
BA_ "GenMsgCycleTime" BO_ 2566897411 10;
BA_ "VssMsg" BO_ 2566897411 "Mch.TCU.TM3V";
BA_ "Channel" BO_ 2566897411 "can1";
BA_ "GenMsgCycleTime" BO_ 2365571105 100;
BA_ "VssMsg" BO_ 2365571105 "Mch.MCU.VM1T";
BA_ "Channel" BO_ 2365571105 "can1";
BA_ "GenMsgCycleTime" BO_ 2365571361 100;
BA_ "VssMsg" BO_ 2365571361 "Mch.MCU.VM2T";
BA_ "Channel" BO_ 2365571361 "can1";
BA_ "GenMsgCycleTime" BO_ 2365572608 10;
BA_ "VssMsg" BO_ 2365572608 "Mch.ECU.VGTPosCmd";
BA_ "Channel" BO_ 2365572608 "can1";
BA_ "VssMsg" BO_ 2566901763 "Mch.TCU.HSDI";
BA_ "Channel" BO_ 2566901763 "can1";
BA_ "VssMsg" BO_ 2566901793 "Mch.MCU.HSDI";
BA_ "Channel" BO_ 2566901793 "can1";
BA_ "VssMsg" BO_ 2566901936 "Mch.MC3D.HSDI";
BA_ "Channel" BO_ 2566901936 "can1";
BA_ "VssMsg" BO_ 2566902049 "Mch.MCU.FSDI";
BA_ "Channel" BO_ 2566902049 "can1";
BA_ "VssMsg" BO_ 2566902305 "Mch.MCU.FOUHI";
BA_ "Channel" BO_ 2566902305 "can1";
BA_ "VssMsg" BO_ 2566902561 "Mch.MCU.FOCPHI";
BA_ "Channel" BO_ 2566902561 "can1";
BA_ "VssMsg" BO_ 2566902817 "Mch.MCU.XASI";
BA_ "Channel" BO_ 2566902817 "can1";
BA_ "VssMsg" BO_ 2566903073 "Mch.MCU.XAAI";
BA_ "Channel" BO_ 2566903073 "can1";
BA_ "VssMsg" BO_ 2566903329 "Mch.MCU.XDSI";
BA_ "Channel" BO_ 2566903329 "can1";
BA_ "VssMsg" BO_ 2566903585 "Mch.MCU.XDAI";
BA_ "Channel" BO_ 2566903585 "can1";
BA_ "VssMsg" BO_ 2566903841 "Mch.MCU.LASI";
BA_ "Channel" BO_ 2566903841 "can1";
BA_ "VssMsg" BO_ 2566904097 "Mch.MCU.LAAI";
BA_ "Channel" BO_ 2566904097 "can1";
BA_ "VssMsg" BO_ 2566904353 "Mch.MCU.LDSI";
BA_ "Channel" BO_ 2566904353 "can1";
BA_ "VssMsg" BO_ 2566904372 "Mch.SMK.SOFT";
BA_ "Channel" BO_ 2566904372 "can1";
BA_ "VssMsg" BO_ 2566904609 "Mch.MCU.LDAI";
BA_ "Channel" BO_ 2566904609 "can1";
BA_ "VssSig" SG_ 2566893620 SmkId "Mch.SMK.SMKC.SmkId";
BA_ "VssSig" SG_ 2566893620 SoftwareVer "Mch.SMK.SMKC.SoftwareVer";
BA_ "VssSig" SG_ 2566893620 FobImmobilizerWrn "Mch.SMK.SMKC.FobImmobilizerWrn";
BA_ "VssSig" SG_ 2566893620 FobLowBatWrn "Mch.SMK.SMKC.FobLowBatWrn";
BA_ "VssSig" SG_ 2566893620 NoDttFobInsideCabinWrn "Mch.SMK.SMKC.NoDttFobInsideCabinWrn";
BA_ "VssSig" SG_ 2566893620 FobRgstId "Mch.SMK.SMKC.FobRgstId";
BA_ "VssSig" SG_ 2566893620 FobRgstFdbk "Mch.SMK.SMKC.FobRgstFdbk";
BA_ "VssSig" SG_ 2566893620 PreheatSt "Mch.SMK.SMKC.PreheatSt";
BA_ "VssSig" SG_ 2566893620 AppLmpSt "Mch.SMK.SMKC.AppLmpSt";
BA_ "VssSig" SG_ 2566893620 VentilationTmp "Mch.SMK.SMKC.VentilationTmp";
BA_ "VssSig" SG_ 2566893620 VentilationSt "Mch.SMK.SMKC.VentilationSt";
BA_ "VssSig" SG_ 2566893620 DoorLckSt "Mch.SMK.SMKC.DoorLckSt";
BA_ "VssSig" SG_ 2566894388 DeicerSt "Mch.SMK.SMKI.DeicerSt";
BA_ "VssSig" SG_ 2566894388 ForcedEgStopCmd "Mch.SMK.SMKI.ForcedEgStopCmd";
BA_ "VssSig" SG_ 2566894388 RmRunningSt "Mch.SMK.SMKI.RmRunningSt";
BA_ "VssSig" SG_ 2566894388 MaintenanceDoorSt "Mch.SMK.SMKI.MaintenanceDoorSt";
BA_ "VssSig" SG_ 2566894388 CabinDoorSt "Mch.SMK.SMKI.CabinDoorSt";
BA_ "VssSig" SG_ 2566894388 FobBatSt "Mch.SMK.SMKI.FobBatSt";
BA_ "VssSig" SG_ 2566894388 MchTonage "Mch.SMK.SMKI.MchTonage";
BA_ "VssSig" SG_ 2566894388 MchModel "Mch.SMK.SMKI.MchModel";
BA_ "VssSig" SG_ 2566894388 FobDtt "Mch.SMK.SMKI.FobDtt";
BA_ "VssSig" SG_ 2566894388 KeyStChange "Mch.SMK.SMKI.KeyStChange";
BA_ "VssSig" SG_ 2566896131 CTLLhRvsTrvlPmpPrs "Mch.TCU.TM5V.CTLLhRvsTrvlPmpPrs";
BA_ "VssSig" SG_ 2566896131 CTLLhFwdTrvlPmpPrs "Mch.TCU.TM5V.CTLLhFwdTrvlPmpPrs";
BA_ "VssSig" SG_ 2566896131 CTLRhRvsTrvlPmpPrs "Mch.TCU.TM5V.CTLRhRvsTrvlPmpPrs";
BA_ "VssSig" SG_ 2566896131 CTLRhFwdTrvlPmpPrs "Mch.TCU.TM5V.CTLRhFwdTrvlPmpPrs";
BA_ "VssSig" SG_ 2566896387 HstCutOffSVSt "Mch.TCU.TM4V.HstCutOffSVSt";
BA_ "VssSig" SG_ 2566896387 TwoSpdSVSt "Mch.TCU.TM4V.TwoSpdSVSt";
BA_ "VssSig" SG_ 2566896387 TrackLdTypeSybCreep "Mch.TCU.TM4V.TrackLdTypeSybCreep";
BA_ "VssSig" SG_ 2566896643 SetMaxSpdLimit "Mch.TCU.TCUHG.SetMaxSpdLimit";
BA_ "VssSig" SG_ 2566896643 SetStrDriftCompensation "Mch.TCU.TCUHG.SetStrDriftCompensation";
BA_ "VssSig" SG_ 2566896643 SetCreepMaxSpd "Mch.TCU.TCUHG.SetCreepMaxSpd";
BA_ "VssSig" SG_ 2566896643 SetJoyTrvlRLTrack "Mch.TCU.TCUHG.SetJoyTrvlRLTrack";
BA_ "VssSig" SG_ 2566896643 TrvlSpdPreset4Rvs "Mch.TCU.TCUHG.TrvlSpdPreset4Rvs";
BA_ "VssSig" SG_ 2566896643 TrvlSpdPreset4Fwd "Mch.TCU.TCUHG.TrvlSpdPreset4Fwd";
BA_ "VssSig" SG_ 2566896643 TrvlSpdPreset3Rvs "Mch.TCU.TCUHG.TrvlSpdPreset3Rvs";
BA_ "VssSig" SG_ 2566896643 TrvlSpdPreset3Fwd "Mch.TCU.TCUHG.TrvlSpdPreset3Fwd";
BA_ "VssSig" SG_ 2566896643 TrvlSpdPreset2Rvs "Mch.TCU.TCUHG.TrvlSpdPreset2Rvs";
BA_ "VssSig" SG_ 2566896643 TrvlSpdPreset2Fwd "Mch.TCU.TCUHG.TrvlSpdPreset2Fwd";
BA_ "VssSig" SG_ 2566896643 TrvlSpdPreset1Rvs "Mch.TCU.TCUHG.TrvlSpdPreset1Rvs";
BA_ "VssSig" SG_ 2566896643 TrvlSpdPreset1Fwd "Mch.TCU.TCUHG.TrvlSpdPreset1Fwd";
BA_ "VssSig" SG_ 2566896643 TrvlSpdSet "Mch.TCU.TCUHG.TrvlSpdSet";
BA_ "VssSig" SG_ 2566896643 BrkPdlDecel "Mch.TCU.TCUHG.BrkPdlDecel";
BA_ "VssSig" SG_ 2365570307 LhTrvlMotorEpprVv "Mch.TCU.TM1V.LhTrvlMotorEpprVv";
BA_ "VssSig" SG_ 2365570307 RhTrvlMotorEpprVv "Mch.TCU.TM1V.RhTrvlMotorEpprVv";
BA_ "VssSig" SG_ 2365570307 LhRvsTrvlPmpEpprVv "Mch.TCU.TM1V.LhRvsTrvlPmpEpprVv";
BA_ "VssSig" SG_ 2365570307 LhFwdTrvlPmpEpprVv "Mch.TCU.TM1V.LhFwdTrvlPmpEpprVv";
BA_ "VssSig" SG_ 2365570307 RhRvsTrvlPmpEpprVv "Mch.TCU.TM1V.RhRvsTrvlPmpEpprVv";
BA_ "VssSig" SG_ 2365570307 RhFwdTrvlPmpEpprVv "Mch.TCU.TM1V.RhFwdTrvlPmpEpprVv";
BA_ "VssSig" SG_ 2365570307 VhcSpd "Mch.TCU.TM1V.VhcSpd";
BA_ "VssSig" SG_ 2365570307 CurRvsMaxSpd "Mch.TCU.TM1V.CurRvsMaxSpd";
BA_ "VssSig" SG_ 2365570307 CurFwdMaxSpd "Mch.TCU.TM1V.CurFwdMaxSpd";
BA_ "VssSig" SG_ 2365570307 Fnr "Mch.TCU.TM1V.Fnr";
BA_ "VssSig" SG_ 2566897155 LhTrvlMotorSpdSs "Mch.TCU.TM2V.LhTrvlMotorSpdSs";
BA_ "VssSig" SG_ 2566897155 RhTrvlMotorSpdSs "Mch.TCU.TM2V.RhTrvlMotorSpdSs";
BA_ "VssSig" SG_ 2566897155 LhRvsTrvlPmpPrsSs "Mch.TCU.TM2V.LhRvsTrvlPmpPrsSs";
BA_ "VssSig" SG_ 2566897155 LhFwdTrvlPmpPrsSs "Mch.TCU.TM2V.LhFwdTrvlPmpPrsSs";
BA_ "VssSig" SG_ 2566897155 RhRvsTrvlPmpPrsSs "Mch.TCU.TM2V.RhRvsTrvlPmpPrsSs";
BA_ "VssSig" SG_ 2566897155 RhFwdtPmpPrsSs "Mch.TCU.TM2V.RhFwdtPmpPrsSs";
BA_ "VssSig" SG_ 2566897411 ParkingBrkReqSt "Mch.TCU.TM3V.ParkingBrkReqSt";
BA_ "VssSig" SG_ 2566897411 CurPwrMd "Mch.TCU.TM3V.CurPwrMd";
BA_ "VssSig" SG_ 2566897411 CurRvsMaxSpd "Mch.TCU.TM3V.CurRvsMaxSpd";
BA_ "VssSig" SG_ 2566897411 CurFwdMaxSpd "Mch.TCU.TM3V.CurFwdMaxSpd";
BA_ "VssSig" SG_ 2566897411 BrkAngSs2Pct "Mch.TCU.TM3V.BrkAngSs2Pct";
BA_ "VssSig" SG_ 2566897411 BrkAngSs1Pct "Mch.TCU.TM3V.BrkAngSs1Pct";
BA_ "VssSig" SG_ 2566897411 FootPdlPct "Mch.TCU.TM3V.FootPdlPct";
BA_ "VssSig" SG_ 2566897411 BrkAngSs2Vlt "Mch.TCU.TM3V.BrkAngSs2Vlt";
BA_ "VssSig" SG_ 2566897411 BrkAngSs1Vlt "Mch.TCU.TM3V.BrkAngSs1Vlt";
BA_ "VssSig" SG_ 2566897411 EgCtrlDVlt "Mch.TCU.TM3V.EgCtrlDVlt";
BA_ "VssSig" SG_ 2365571105 HydTmp "Mch.MCU.VM1T.HydTmp";
BA_ "VssSig" SG_ 2365571105 FootPdlPct "Mch.MCU.VM1T.FootPdlPct";
BA_ "VssSig" SG_ 2365571105 RpmReqMd "Mch.MCU.VM1T.RpmReqMd";
BA_ "VssSig" SG_ 2365571105 ReqRvsMaxSpd "Mch.MCU.VM1T.ReqRvsMaxSpd";
BA_ "VssSig" SG_ 2365571105 ReqFwdMaxSpd "Mch.MCU.VM1T.ReqFwdMaxSpd";
BA_ "VssSig" SG_ 2365571105 PowMd "Mch.MCU.VM1T.PowMd";
BA_ "VssSig" SG_ 2365571105 IsParking "Mch.MCU.VM1T.IsParking";
BA_ "VssSig" SG_ 2365571105 TractionCtrl "Mch.MCU.VM1T.TractionCtrl";
BA_ "VssSig" SG_ 2365572608 VgtCmdSt "Mch.ECU.VGTPosCmd.VgtCmdSt";
BA_ "VssSig" SG_ 2365572608 VgtNzPos "Mch.ECU.VGTPosCmd.VgtNzPos";
BA_ "VssSig" SG_ 2566901763 RandomVal "Mch.TCU.HSDI.RandomVal";
BA_ "VssSig" SG_ 2566901793 RandomVal "Mch.MCU.HSDI.RandomVal";
BA_ "VssSig" SG_ 2566901936 RandomVal "Mch.MC3D.HSDI.RandomVal";
BA_ "VssSig" SG_ 2566902049 OptSetCdsRvsFanAutoPrd "Mch.MCU.FSDI.OptSetCdsRvsFanAutoPrd";
BA_ "VssSig" SG_ 2566902049 OptSetTrailer "Mch.MCU.FSDI.OptSetTrailer";
BA_ "VssSig" SG_ 2566902049 OptSetEscortWrkLmp "Mch.MCU.FSDI.OptSetEscortWrkLmp";
BA_ "VssSig" SG_ 2566902049 OptSetCdsRvsFanMd "Mch.MCU.FSDI.OptSetCdsRvsFanMd";
BA_ "VssSig" SG_ 2566902049 OptSetRttDir "Mch.MCU.FSDI.OptSetRttDir";
BA_ "VssSig" SG_ 2566902049 OptSetAdvLv "Mch.MCU.FSDI.OptSetAdvLv";
BA_ "VssSig" SG_ 2566902049 OptSetGndSaw "Mch.MCU.FSDI.OptSetGndSaw";
BA_ "VssSig" SG_ 2566902049 OptSetTpms "Mch.MCU.FSDI.OptSetTpms";
BA_ "VssSig" SG_ 2566902049 OptSetAutoBrkrSens "Mch.MCU.FSDI.OptSetAutoBrkrSens";
BA_ "VssSig" SG_ 2566902049 OptSetAntiBlankFire "Mch.MCU.FSDI.OptSetAntiBlankFire";
BA_ "VssSig" SG_ 2566902049 OptSetJoyBoom "Mch.MCU.FSDI.OptSetJoyBoom";
BA_ "VssSig" SG_ 2566902049 OptSetJoyTilt "Mch.MCU.FSDI.OptSetJoyTilt";
BA_ "VssSig" SG_ 2566902049 OptSetRvsFanDurTm "Mch.MCU.FSDI.OptSetRvsFanDurTm";
BA_ "VssSig" SG_ 2566902049 OptSetHhFw "Mch.MCU.FSDI.OptSetHhFw";
BA_ "VssSig" SG_ 2566902049 OptSet3DMgMc3rd "Mch.MCU.FSDI.OptSet3DMgMc3rd";
BA_ "VssSig" SG_ 2566902049 OptSetRrCabLmp "Mch.MCU.FSDI.OptSetRrCabLmp";
BA_ "VssSig" SG_ 2566902049 OptSetDzMc "Mch.MCU.FSDI.OptSetDzMc";
BA_ "VssSig" SG_ 2566902049 OptSetTrqCvtLckUp "Mch.MCU.FSDI.OptSetTrqCvtLckUp";
BA_ "VssSig" SG_ 2566902049 OptSetTwThmbWhlDir "Mch.MCU.FSDI.OptSetTwThmbWhlDir";
BA_ "VssSig" SG_ 2566902049 OptSetOptPdlType2 "Mch.MCU.FSDI.OptSetOptPdlType2";
BA_ "VssSig" SG_ 2566902049 OptSetMaxTrvlSpd "Mch.MCU.FSDI.OptSetMaxTrvlSpd";
BA_ "VssSig" SG_ 2566902049 OptSetRollSlope "Mch.MCU.FSDI.OptSetRollSlope";
BA_ "VssSig" SG_ 2566902049 OptSetDaac "Mch.MCU.FSDI.OptSetDaac";
BA_ "VssSig" SG_ 2566902049 OptSetRvsLmpFuncAct "Mch.MCU.FSDI.OptSetRvsLmpFuncAct";
BA_ "VssSig" SG_ 2566902049 OptSetBladeAngSens "Mch.MCU.FSDI.OptSetBladeAngSens";
BA_ "VssSig" SG_ 2566902049 OptSetRaiseDnSens "Mch.MCU.FSDI.OptSetRaiseDnSens";
BA_ "VssSig" SG_ 2566902049 OptSetBladeTiltSens "Mch.MCU.FSDI.OptSetBladeTiltSens";
BA_ "VssSig" SG_ 2566902049 OptSetPchSlope "Mch.MCU.FSDI.OptSetPchSlope";
BA_ "VssSig" SG_ 2566902049 OptSetMrrHt "Mch.MCU.FSDI.OptSetMrrHt";
BA_ "VssSig" SG_ 2566902049 OptSetQckCoolMd "Mch.MCU.FSDI.OptSetQckCoolMd";
BA_ "VssSig" SG_ 2566902049 RttOptSet "Mch.MCU.FSDI.RttOptSet";
BA_ "VssSig" SG_ 2566902049 OptSetTrvlStrgtPdl "Mch.MCU.FSDI.OptSetTrvlStrgtPdl";
BA_ "VssSig" SG_ 2566902049 OptSetJoyType "Mch.MCU.FSDI.OptSetJoyType";
BA_ "VssSig" SG_ 2566902049 OptSetAttCtrl "Mch.MCU.FSDI.OptSetAttCtrl";
BA_ "VssSig" SG_ 2566902049 OptSetTiltRttType "Mch.MCU.FSDI.OptSetTiltRttType";
BA_ "VssSig" SG_ 2566902049 OptSetArtiBoom "Mch.MCU.FSDI.OptSetArtiBoom";
BA_ "VssSig" SG_ 2566902049 OptSetDzBlade "Mch.MCU.FSDI.OptSetDzBlade";
BA_ "VssSig" SG_ 2566902049 OptSetHhLift "Mch.MCU.FSDI.OptSetHhLift";
BA_ "VssSig" SG_ 2566902049 OptSetJoyPtnChange "Mch.MCU.FSDI.OptSetJoyPtnChange";
BA_ "VssSig" SG_ 2566902049 OptSetTrqCvtLookUp "Mch.MCU.FSDI.OptSetTrqCvtLookUp";
BA_ "VssSig" SG_ 2566902049 OptSetDhlAuto "Mch.MCU.FSDI.OptSetDhlAuto";
BA_ "VssSig" SG_ 2566902049 OptSet3DMG "Mch.MCU.FSDI.OptSet3DMG";
BA_ "VssSig" SG_ 2566902049 OptSetTrvlSwgAlm "Mch.MCU.FSDI.OptSetTrvlSwgAlm";
BA_ "VssSig" SG_ 2566902049 OptSetPrsCtrl "Mch.MCU.FSDI.OptSetPrsCtrl";
BA_ "VssSig" SG_ 2566902049 OptSetRollOvr "Mch.MCU.FSDI.OptSetRollOvr";
BA_ "VssSig" SG_ 2566902049 OptSet4WhlStr "Mch.MCU.FSDI.OptSet4WhlStr";
BA_ "VssSig" SG_ 2566902049 OptSetSpool4 "Mch.MCU.FSDI.OptSetSpool4";
BA_ "VssSig" SG_ 2566902049 OptSetConstFw "Mch.MCU.FSDI.OptSetConstFw";
BA_ "VssSig" SG_ 2566902049 OptSetConstFwStep "Mch.MCU.FSDI.OptSetConstFwStep";
BA_ "VssSig" SG_ 2566902049 OptSetLisRvsOprSpd "Mch.MCU.FSDI.OptSetLisRvsOprSpd";
BA_ "VssSig" SG_ 2566902049 OptSetFrCabLmp "Mch.MCU.FSDI.OptSetFrCabLmp";
BA_ "VssSig" SG_ 2566902049 OptSetOutRr "Mch.MCU.FSDI.OptSetOutRr";
BA_ "VssSig" SG_ 2566902049 OptSetOutRlRrDz "Mch.MCU.FSDI.OptSetOutRlRrDz";
BA_ "VssSig" SG_ 2566902049 OptSetOutFr "Mch.MCU.FSDI.OptSetOutFr";
BA_ "VssSig" SG_ 2566902049 OptSetOutFlFrDz "Mch.MCU.FSDI.OptSetOutFlFrDz";
BA_ "VssSig" SG_ 2566902049 OptSetJoyStr "Mch.MCU.FSDI.OptSetJoyStr";
BA_ "VssSig" SG_ 2566902049 OptSetRvsTrvlSpdLmt "Mch.MCU.FSDI.OptSetRvsTrvlSpdLmt";
BA_ "VssSig" SG_ 2566902049 OptSetEmcvBoomDnImpactPrevent "Mch.MCU.FSDI.OptSetEmcvBoomDnImpactPrevent";
BA_ "VssSig" SG_ 2566902049 OptSetEmcvBoomUpImpactPrevent "Mch.MCU.FSDI.OptSetEmcvBoomUpImpactPrevent";
BA_ "VssSig" SG_ 2566902049 OptSetEmcvBckDumpImpactPrevent "Mch.MCU.FSDI.OptSetEmcvBckDumpImpactPrevent";
BA_ "VssSig" SG_ 2566902049 OptSetEmcvBckCrowdImpactPrevent "Mch.MCU.FSDI.OptSetEmcvBckCrowdImpactPrevent";
BA_ "VssSig" SG_ 2566902049 OptSetEmcvBckSens "Mch.MCU.FSDI.OptSetEmcvBckSens";
BA_ "VssSig" SG_ 2566902049 OptSetEmcvBoomSens "Mch.MCU.FSDI.OptSetEmcvBoomSens";
BA_ "VssSig" SG_ 2566902049 OptSetEstrJoySens "Mch.MCU.FSDI.OptSetEstrJoySens";
BA_ "VssSig" SG_ 2566902049 OptSetWrkLis "Mch.MCU.FSDI.OptSetWrkLis";
BA_ "VssSig" SG_ 2566902049 OptSetLcInVal "Mch.MCU.FSDI.OptSetLcInVal";
BA_ "VssSig" SG_ 2566902049 OptSetR2InVal "Mch.MCU.FSDI.OptSetR2InVal";
BA_ "VssSig" SG_ 2566902049 OptSetR1InVal "Mch.MCU.FSDI.OptSetR1InVal";
BA_ "VssSig" SG_ 2566902049 OptSetBckWghInVlue "Mch.MCU.FSDI.OptSetBckWghInVlue";
BA_ "VssSig" SG_ 2566902049 OptSetBoomWghInVal "Mch.MCU.FSDI.OptSetBoomWghInVal";
BA_ "VssSig" SG_ 2566902049 OptSetMaxCritWghVal "Mch.MCU.FSDI.OptSetMaxCritWghVal";
BA_ "VssSig" SG_ 2566902049 OptSetHalfCritWghVal "Mch.MCU.FSDI.OptSetHalfCritWghVal";
BA_ "VssSig" SG_ 2566902049 OptSetElecStr "Mch.MCU.FSDI.OptSetElecStr";
BA_ "VssSig" SG_ 2566902049 OptSetRvsFan "Mch.MCU.FSDI.OptSetRvsFan";
BA_ "VssSig" SG_ 2566902049 OptSetRcw "Mch.MCU.FSDI.OptSetRcw";
BA_ "VssSig" SG_ 2566902049 OptSetQckCoupler "Mch.MCU.FSDI.OptSetQckCoupler";
BA_ "VssSig" SG_ 2566902049 OptSetTrvlOrSwgAlm "Mch.MCU.FSDI.OptSetTrvlOrSwgAlm";
BA_ "VssSig" SG_ 2566902049 OptSetSmk "Mch.MCU.FSDI.OptSetSmk";
BA_ "VssSig" SG_ 2566902049 OptSetOwd "Mch.MCU.FSDI.OptSetOwd";
BA_ "VssSig" SG_ 2566902049 OptSetMchNameInit "Mch.MCU.FSDI.OptSetMchNameInit";
BA_ "VssSig" SG_ 2566902049 OptSetEmvcPmcv "Mch.MCU.FSDI.OptSetEmvcPmcv";
BA_ "VssSig" SG_ 2566902049 OptSetAebReq "Mch.MCU.FSDI.OptSetAebReq";
BA_ "VssSig" SG_ 2566902049 OptSetRvsFanOn "Mch.MCU.FSDI.OptSetRvsFanOn";
BA_ "VssSig" SG_ 2566902049 OptSetRvsFanMd "Mch.MCU.FSDI.OptSetRvsFanMd";
BA_ "VssSig" SG_ 2566902049 OptSetWhg "Mch.MCU.FSDI.OptSetWhg";
BA_ "VssSig" SG_ 2566902049 OptSetHydrostatCalbCmd "Mch.MCU.FSDI.OptSetHydrostatCalbCmd";
BA_ "VssSig" SG_ 2566902049 OptSetClutchCalbCmd "Mch.MCU.FSDI.OptSetClutchCalbCmd";
BA_ "VssSig" SG_ 2566902049 OptSetEmgMd "Mch.MCU.FSDI.OptSetEmgMd";
BA_ "VssSig" SG_ 2566902049 OptSetCreepAct "Mch.MCU.FSDI.OptSetCreepAct";
BA_ "VssSig" SG_ 2566902049 OptSetThmbWhl "Mch.MCU.FSDI.OptSetThmbWhl";
BA_ "VssSig" SG_ 2566902049 OptSetAxleOilCool "Mch.MCU.FSDI.OptSetAxleOilCool";
BA_ "VssSig" SG_ 2566902049 OptSetAngSs "Mch.MCU.FSDI.OptSetAngSs";
BA_ "VssSig" SG_ 2566902049 OptSetBrkPdlCalb "Mch.MCU.FSDI.OptSetBrkPdlCalb";
BA_ "VssSig" SG_ 2566902049 OptSetCreepGr "Mch.MCU.FSDI.OptSetCreepGr";
BA_ "VssSig" SG_ 2566902049 OptSetLisOprSpd "Mch.MCU.FSDI.OptSetLisOprSpd";
BA_ "VssSig" SG_ 2566902049 OptSetRvsFanTm "Mch.MCU.FSDI.OptSetRvsFanTm";
BA_ "VssSig" SG_ 2566902049 OptSetLis "Mch.MCU.FSDI.OptSetLis";
BA_ "VssSig" SG_ 2566902049 OptSetEmgStr "Mch.MCU.FSDI.OptSetEmgStr";
BA_ "VssSig" SG_ 2566902049 OptSetDhl "Mch.MCU.FSDI.OptSetDhl";
BA_ "VssSig" SG_ 2566902049 OptSetFnr2LeverType "Mch.MCU.FSDI.OptSetFnr2LeverType";
BA_ "VssSig" SG_ 2566902049 OptSetTrmsLmtGr "Mch.MCU.FSDI.OptSetTrmsLmtGr";
BA_ "VssSig" SG_ 2566902049 OptSetTransBck "Mch.MCU.FSDI.OptSetTransBck";
BA_ "VssSig" SG_ 2566902049 OptSetItgtFltBoom "Mch.MCU.FSDI.OptSetItgtFltBoom";
BA_ "VssSig" SG_ 2566902049 OptSetBeacon "Mch.MCU.FSDI.OptSetBeacon";
BA_ "VssSig" SG_ 2566902049 OptSetMultiFuncBtnSel "Mch.MCU.FSDI.OptSetMultiFuncBtnSel";
BA_ "VssSig" SG_ 2566902049 OptSetAutoIdle "Mch.MCU.FSDI.OptSetAutoIdle";
BA_ "VssSig" SG_ 2566902049 MachineName "Mch.MCU.FSDI.MachineName";
BA_ "VssSig" SG_ 2566902049 AutoIdleTm "Mch.MCU.FSDI.AutoIdleTm";
BA_ "VssSig" SG_ 2566902049 BrkrOprTm "Mch.MCU.FSDI.BrkrOprTm";
BA_ "VssSig" SG_ 2566902049 OptSetAutoShutOffTm "Mch.MCU.FSDI.OptSetAutoShutOffTm";
BA_ "VssSig" SG_ 2566902049 OptSetAutoShutOff "Mch.MCU.FSDI.OptSetAutoShutOff";
BA_ "VssSig" SG_ 2566902049 OptSetAutoShutOffCancel "Mch.MCU.FSDI.OptSetAutoShutOffCancel";
BA_ "VssSig" SG_ 2566902049 OptSetAutoIdleRpmTmp "Mch.MCU.FSDI.OptSetAutoIdleRpmTmp";
BA_ "VssSig" SG_ 2566902049 OptSetSpc "Mch.MCU.FSDI.OptSetSpc";
BA_ "VssSig" SG_ 2566902049 OptSetVoiceWrnCmd "Mch.MCU.FSDI.OptSetVoiceWrnCmd";
BA_ "VssSig" SG_ 2566902049 OptSetBoomSwgUSe "Mch.MCU.FSDI.OptSetBoomSwgUSe";
BA_ "VssSig" SG_ 2566902049 OptSetTrvl2PmpCmbRls "Mch.MCU.FSDI.OptSetTrvl2PmpCmbRls";
BA_ "VssSig" SG_ 2566902049 OptSetTrvl1PmpUse "Mch.MCU.FSDI.OptSetTrvl1PmpUse";
BA_ "VssSig" SG_ 2566902049 OptSetTrmsMaxSpdLmtChk "Mch.MCU.FSDI.OptSetTrmsMaxSpdLmtChk";
BA_ "VssSig" SG_ 2566902049 OptSetHhAlt "Mch.MCU.FSDI.OptSetHhAlt";
BA_ "VssSig" SG_ 2566902049 OptSetRipperOpt "Mch.MCU.FSDI.OptSetRipperOpt";
BA_ "VssSig" SG_ 2566902049 OptSetRttOpt "Mch.MCU.FSDI.OptSetRttOpt";
BA_ "VssSig" SG_ 2566902049 OptSetJoyThmbWhlRtt "Mch.MCU.FSDI.OptSetJoyThmbWhlRtt";
BA_ "VssSig" SG_ 2566902049 OptSetJoyThmbWhlTw "Mch.MCU.FSDI.OptSetJoyThmbWhlTw";
BA_ "VssSig" SG_ 2566902049 OptSetTw "Mch.MCU.FSDI.OptSetTw";
BA_ "VssSig" SG_ 2566902049 OptSetOptPdl "Mch.MCU.FSDI.OptSetOptPdl";
BA_ "VssSig" SG_ 2566902049 OptSetAttPdlJoySel "Mch.MCU.FSDI.OptSetAttPdlJoySel";
BA_ "VssSig" SG_ 2566902049 OptSet2Pmp "Mch.MCU.FSDI.OptSet2Pmp";
BA_ "VssSig" SG_ 2566902049 OptSetAttTw "Mch.MCU.FSDI.OptSetAttTw";
BA_ "VssSig" SG_ 2566902049 OptSetAttBrkr "Mch.MCU.FSDI.OptSetAttBrkr";
BA_ "VssSig" SG_ 2566902049 OptSetKeylessUse "Mch.MCU.FSDI.OptSetKeylessUse";
BA_ "VssSig" SG_ 2566902049 OptSetKeyless "Mch.MCU.FSDI.OptSetKeyless";
BA_ "VssSig" SG_ 2566902049 OptSetWiper "Mch.MCU.FSDI.OptSetWiper";
BA_ "VssSig" SG_ 2566902049 OptSetTrvlMotOvrHtWrn "Mch.MCU.FSDI.OptSetTrvlMotOvrHtWrn";
BA_ "VssSig" SG_ 2566902049 OptSetFnrDefault "Mch.MCU.FSDI.OptSetFnrDefault";
BA_ "VssSig" SG_ 2566902049 OptSetFnrSel "Mch.MCU.FSDI.OptSetFnrSel";
BA_ "VssSig" SG_ 2566902049 OptSetCanTypeCmbSw "Mch.MCU.FSDI.OptSetCanTypeCmbSw";
BA_ "VssSig" SG_ 2566902049 UserDtIdx "Mch.MCU.FSDI.UserDtIdx";
BA_ "VssSig" SG_ 2566902049 VhcSerialNo "Mch.MCU.FSDI.VhcSerialNo";
BA_ "VssSig" SG_ 2566902049 OptSetAttWghFactor "Mch.MCU.FSDI.OptSetAttWghFactor";
BA_ "VssSig" SG_ 2566902049 OptSetCanTypeFuelSs "Mch.MCU.FSDI.OptSetCanTypeFuelSs";
BA_ "VssSig" SG_ 2566902049 OptSetSubBrkLmp "Mch.MCU.FSDI.OptSetSubBrkLmp";
BA_ "VssSig" SG_ 2566902049 TiltRttMd "Mch.MCU.FSDI.TiltRttMd";
BA_ "VssSig" SG_ 2566902049 USerLckUnlockSt "Mch.MCU.FSDI.USerLckUnlockSt";
BA_ "VssSig" SG_ 2566902049 UserPw "Mch.MCU.FSDI.UserPw";
BA_ "VssSig" SG_ 2566902049 OptWgh "Mch.MCU.FSDI.OptWgh";
BA_ "VssSig" SG_ 2566902049 OptMC "Mch.MCU.FSDI.OptMC";
BA_ "VssSig" SG_ 2566902049 OptEgPostHtAct "Mch.MCU.FSDI.OptEgPostHtAct";
BA_ "VssSig" SG_ 2566902049 Opt2DMG "Mch.MCU.FSDI.Opt2DMG";
BA_ "VssSig" SG_ 2566902049 AdminUse2 "Mch.MCU.FSDI.AdminUse2";
BA_ "VssSig" SG_ 2566902049 AdminUse1 "Mch.MCU.FSDI.AdminUse1";
BA_ "VssSig" SG_ 2566902049 AdminUse0 "Mch.MCU.FSDI.AdminUse0";
BA_ "VssSig" SG_ 2566902049 OwnerPw0UpTm "Mch.MCU.FSDI.OwnerPw0UpTm";
BA_ "VssSig" SG_ 2566902049 OwnerPw0Use "Mch.MCU.FSDI.OwnerPw0Use";
BA_ "VssSig" SG_ 2566902049 OwnerPw0 "Mch.MCU.FSDI.OwnerPw0";
BA_ "VssSig" SG_ 2566902305 PmpDrvAirCtrgHr "Mch.MCU.FOUHI.PmpDrvAirCtrgHr";
BA_ "VssSig" SG_ 2566902305 PmpDrvOilHr "Mch.MCU.FOUHI.PmpDrvOilHr";
BA_ "VssSig" SG_ 2566902305 HstFiltHr "Mch.MCU.FOUHI.HstFiltHr";
BA_ "VssSig" SG_ 2566902305 AxleOilFiltHr "Mch.MCU.FOUHI.AxleOilFiltHr";
BA_ "VssSig" SG_ 2566902305 AtsSparkPlugHr "Mch.MCU.FOUHI.AtsSparkPlugHr";
BA_ "VssSig" SG_ 2566902305 EgCrkcaseBreatherElementHr "Mch.MCU.FOUHI.EgCrkcaseBreatherElementHr";
BA_ "VssSig" SG_ 2566902305 AirCndFiltInHr "Mch.MCU.FOUHI.AirCndFiltInHr";
BA_ "VssSig" SG_ 2566902305 AirCndFiltOutHr "Mch.MCU.FOUHI.AirCndFiltOutHr";
BA_ "VssSig" SG_ 2566902305 EgOilCtrCleanerFiltHr "Mch.MCU.FOUHI.EgOilCtrCleanerFiltHr";
BA_ "VssSig" SG_ 2566902305 DefBreatherFiltHr "Mch.MCU.FOUHI.DefBreatherFiltHr";
BA_ "VssSig" SG_ 2566902305 DefFiltHr "Mch.MCU.FOUHI.DefFiltHr";
BA_ "VssSig" SG_ 2566902305 OilBathPrecleanerHr "Mch.MCU.FOUHI.OilBathPrecleanerHr";
BA_ "VssSig" SG_ 2566902305 DefHr "Mch.MCU.FOUHI.DefHr";
BA_ "VssSig" SG_ 2566902305 AxleOilHr "Mch.MCU.FOUHI.AxleOilHr";
BA_ "VssSig" SG_ 2566902305 TrmsOilFiltHr "Mch.MCU.FOUHI.TrmsOilFiltHr";
BA_ "VssSig" SG_ 2566902305 TrmsOilHr "Mch.MCU.FOUHI.TrmsOilHr";
BA_ "VssSig" SG_ 2566902305 BreatherOilSepFiltHr "Mch.MCU.FOUHI.BreatherOilSepFiltHr";
BA_ "VssSig" SG_ 2566902305 DpfHr "Mch.MCU.FOUHI.DpfHr";
BA_ "VssSig" SG_ 2566902305 CoolHr "Mch.MCU.FOUHI.CoolHr";
BA_ "VssSig" SG_ 2566902305 HydOilHr "Mch.MCU.FOUHI.HydOilHr";
BA_ "VssSig" SG_ 2566902305 EgOilHr "Mch.MCU.FOUHI.EgOilHr";
BA_ "VssSig" SG_ 2566902305 PilotFiltHr "Mch.MCU.FOUHI.PilotFiltHr";
BA_ "VssSig" SG_ 2566902305 RetFiltHr "Mch.MCU.FOUHI.RetFiltHr";
BA_ "VssSig" SG_ 2566902305 EgOilFiltHr "Mch.MCU.FOUHI.EgOilFiltHr";
BA_ "VssSig" SG_ 2566902305 AirCleanerHr "Mch.MCU.FOUHI.AirCleanerHr";
BA_ "VssSig" SG_ 2566902305 FuleFiltHr "Mch.MCU.FOUHI.FuleFiltHr";
BA_ "VssSig" SG_ 2566902561 PmpDrvAirCtrgPrd "Mch.MCU.FOCPHI.PmpDrvAirCtrgPrd";
BA_ "VssSig" SG_ 2566902561 PmpDrvOilPrd "Mch.MCU.FOCPHI.PmpDrvOilPrd";
BA_ "VssSig" SG_ 2566902561 HstFiltPrd "Mch.MCU.FOCPHI.HstFiltPrd";
BA_ "VssSig" SG_ 2566902561 AxleOilFiltPrd "Mch.MCU.FOCPHI.AxleOilFiltPrd";
BA_ "VssSig" SG_ 2566902561 AtsSparkPlugPrd "Mch.MCU.FOCPHI.AtsSparkPlugPrd";
BA_ "VssSig" SG_ 2566902561 EgCrkcaseBreatherElementPrd "Mch.MCU.FOCPHI.EgCrkcaseBreatherElementPrd";
BA_ "VssSig" SG_ 2566902561 AirCndFiltInPrd "Mch.MCU.FOCPHI.AirCndFiltInPrd";
BA_ "VssSig" SG_ 2566902561 AirCndFiltOutPrd "Mch.MCU.FOCPHI.AirCndFiltOutPrd";
BA_ "VssSig" SG_ 2566902561 EgOilCtrCleanerFiltPrd "Mch.MCU.FOCPHI.EgOilCtrCleanerFiltPrd";
BA_ "VssSig" SG_ 2566902561 DefBreatherFiltPrd "Mch.MCU.FOCPHI.DefBreatherFiltPrd";
BA_ "VssSig" SG_ 2566902561 DefFiltPrd "Mch.MCU.FOCPHI.DefFiltPrd";
BA_ "VssSig" SG_ 2566902561 OilBathPrecleanerPrd "Mch.MCU.FOCPHI.OilBathPrecleanerPrd";
BA_ "VssSig" SG_ 2566902561 DefPrd "Mch.MCU.FOCPHI.DefPrd";
BA_ "VssSig" SG_ 2566902561 AxleOilPrd "Mch.MCU.FOCPHI.AxleOilPrd";
BA_ "VssSig" SG_ 2566902561 TrmsOilFiltPrd "Mch.MCU.FOCPHI.TrmsOilFiltPrd";
BA_ "VssSig" SG_ 2566902561 TrmsOilPrd "Mch.MCU.FOCPHI.TrmsOilPrd";
BA_ "VssSig" SG_ 2566902561 BreatherOilSepFiltPrd "Mch.MCU.FOCPHI.BreatherOilSepFiltPrd";
BA_ "VssSig" SG_ 2566902561 DpfPrd "Mch.MCU.FOCPHI.DpfPrd";
BA_ "VssSig" SG_ 2566902561 CoolPrd "Mch.MCU.FOCPHI.CoolPrd";
BA_ "VssSig" SG_ 2566902561 HydOilPrd "Mch.MCU.FOCPHI.HydOilPrd";
BA_ "VssSig" SG_ 2566902561 EgOilPrd "Mch.MCU.FOCPHI.EgOilPrd";
BA_ "VssSig" SG_ 2566902561 PilotFiltPrd "Mch.MCU.FOCPHI.PilotFiltPrd";
BA_ "VssSig" SG_ 2566902561 RetFiltPrd "Mch.MCU.FOCPHI.RetFiltPrd";
BA_ "VssSig" SG_ 2566902561 EgOilFiltPrd "Mch.MCU.FOCPHI.EgOilFiltPrd";
BA_ "VssSig" SG_ 2566902561 AirCleanerPrd "Mch.MCU.FOCPHI.AirCleanerPrd";
BA_ "VssSig" SG_ 2566902561 FuleFiltPrd "Mch.MCU.FOCPHI.FuleFiltPrd";
BA_ "VssSig" SG_ 2566902817 BladeFanPchSsVlt "Mch.MCU.XASI.BladeFanPchSsVlt";
BA_ "VssSig" SG_ 2566902817 RamLckPrs "Mch.MCU.XASI.RamLckPrs";
BA_ "VssSig" SG_ 2566902817 TrailerDnPilotPrs "Mch.MCU.XASI.TrailerDnPilotPrs";
BA_ "VssSig" SG_ 2566902817 BoomHead2Prs "Mch.MCU.XASI.BoomHead2Prs";
BA_ "VssSig" SG_ 2566902817 ArmRodPrs "Mch.MCU.XASI.ArmRodPrs";
BA_ "VssSig" SG_ 2566902817 ArmHEadPrs "Mch.MCU.XASI.ArmHEadPrs";
BA_ "VssSig" SG_ 2566902817 BoodRodPrs "Mch.MCU.XASI.BoodRodPrs";
BA_ "VssSig" SG_ 2566902817 BoomHeadPrs "Mch.MCU.XASI.BoomHeadPrs";
BA_ "VssSig" SG_ 2566902817 TpsVlt "Mch.MCU.XASI.TpsVlt";
BA_ "VssSig" SG_ 2566902817 PchAng "Mch.MCU.XASI.PchAng";
BA_ "VssSig" SG_ 2566902817 RoolAng "Mch.MCU.XASI.RoolAng";
BA_ "VssSig" SG_ 2566902817 TmsSecVlt "Mch.MCU.XASI.TmsSecVlt";
BA_ "VssSig" SG_ 2566902817 VhcTrvlSpdSsFreq "Mch.MCU.XASI.VhcTrvlSpdSsFreq";
BA_ "VssSig" SG_ 2566902817 FlwCtrlLeverRh "Mch.MCU.XASI.FlwCtrlLeverRh";
BA_ "VssSig" SG_ 2566902817 FlwCtrlLeverLh "Mch.MCU.XASI.FlwCtrlLeverLh";
BA_ "VssSig" SG_ 2566902817 FlwCtrlAddLeverLh "Mch.MCU.XASI.FlwCtrlAddLeverLh";
BA_ "VssSig" SG_ 2566902817 BatVlt "Mch.MCU.XASI.BatVlt";
BA_ "VssSig" SG_ 2566902817 AltVlt "Mch.MCU.XASI.AltVlt";
BA_ "VssSig" SG_ 2566902817 HydOilTmp "Mch.MCU.XASI.HydOilTmp";
BA_ "VssSig" SG_ 2566902817 MecaCoolTmp "Mch.MCU.XASI.MecaCoolTmp";
BA_ "VssSig" SG_ 2566902817 GndSawDnSsPrs "Mch.MCU.XASI.GndSawDnSsPrs";
BA_ "VssSig" SG_ 2566902817 GndSawUpSsPrs "Mch.MCU.XASI.GndSawUpSsPrs";
BA_ "VssSig" SG_ 2566902817 WifSsVlt "Mch.MCU.XASI.WifSsVlt";
BA_ "VssSig" SG_ 2566902817 FuelLv "Mch.MCU.XASI.FuelLv";
BA_ "VssSig" SG_ 2566902817 FuelLvAddFuelTnk "Mch.MCU.XASI.FuelLvAddFuelTnk";
BA_ "VssSig" SG_ 2566902817 AcpSsPrs "Mch.MCU.XASI.AcpSsPrs";
BA_ "VssSig" SG_ 2566902817 AccPdlVlt "Mch.MCU.XASI.AccPdlVlt";
BA_ "VssSig" SG_ 2566902817 EgCtrlDialVlt "Mch.MCU.XASI.EgCtrlDialVlt";
BA_ "VssSig" SG_ 2566902817 LsPrs "Mch.MCU.XASI.LsPrs";
BA_ "VssSig" SG_ 2566902817 P3NegaconPrs "Mch.MCU.XASI.P3NegaconPrs";
BA_ "VssSig" SG_ 2566902817 RrNegaconPrs "Mch.MCU.XASI.RrNegaconPrs";
BA_ "VssSig" SG_ 2566902817 FrNegaconPrs "Mch.MCU.XASI.FrNegaconPrs";
BA_ "VssSig" SG_ 2566902817 PilotTrvlPtPrs "Mch.MCU.XASI.PilotTrvlPtPrs";
BA_ "VssSig" SG_ 2566902817 PilotWrkPaPrs "Mch.MCU.XASI.PilotWrkPaPrs";
BA_ "VssSig" SG_ 2566902817 ArmLckPrs "Mch.MCU.XASI.ArmLckPrs";
BA_ "VssSig" SG_ 2566902817 BckCrowdConfPrs "Mch.MCU.XASI.BckCrowdConfPrs";
BA_ "VssSig" SG_ 2566902817 ArmCrowdConfPrs "Mch.MCU.XASI.ArmCrowdConfPrs";
BA_ "VssSig" SG_ 2566902817 BoomUpConfPrs "Mch.MCU.XASI.BoomUpConfPrs";
BA_ "VssSig" SG_ 2566902817 Opt3Prs "Mch.MCU.XASI.Opt3Prs";
BA_ "VssSig" SG_ 2566902817 Opt2Prs "Mch.MCU.XASI.Opt2Prs";
BA_ "VssSig" SG_ 2566902817 Opt1Prs "Mch.MCU.XASI.Opt1Prs";
BA_ "VssSig" SG_ 2566902817 SwgPrs "Mch.MCU.XASI.SwgPrs";
BA_ "VssSig" SG_ 2566902817 TrvlLhPrs "Mch.MCU.XASI.TrvlLhPrs";
BA_ "VssSig" SG_ 2566902817 TrvlRhPrs "Mch.MCU.XASI.TrvlRhPrs";
BA_ "VssSig" SG_ 2566902817 BckDumpPrs "Mch.MCU.XASI.BckDumpPrs";
BA_ "VssSig" SG_ 2566902817 BckCrowdPrs "Mch.MCU.XASI.BckCrowdPrs";
BA_ "VssSig" SG_ 2566902817 ArmOutPrs "Mch.MCU.XASI.ArmOutPrs";
BA_ "VssSig" SG_ 2566902817 ArmInPrs "Mch.MCU.XASI.ArmInPrs";
BA_ "VssSig" SG_ 2566902817 BoomDnPrs "Mch.MCU.XASI.BoomDnPrs";
BA_ "VssSig" SG_ 2566902817 BoomUpPrs "Mch.MCU.XASI.BoomUpPrs";
BA_ "VssSig" SG_ 2566902817 EmgStrPrs "Mch.MCU.XASI.EmgStrPrs";
BA_ "VssSig" SG_ 2566902817 Pmp3Ang "Mch.MCU.XASI.Pmp3Ang";
BA_ "VssSig" SG_ 2566902817 RRpmpAng "Mch.MCU.XASI.RRpmpAng";
BA_ "VssSig" SG_ 2566902817 FrPmpAng "Mch.MCU.XASI.FrPmpAng";
BA_ "VssSig" SG_ 2566902817 FuelPrs "Mch.MCU.XASI.FuelPrs";
BA_ "VssSig" SG_ 2566902817 RcwStpVvPrs "Mch.MCU.XASI.RcwStpVvPrs";
BA_ "VssSig" SG_ 2566902817 Pmp3Prs "Mch.MCU.XASI.Pmp3Prs";
BA_ "VssSig" SG_ 2566902817 BoomCylPrs "Mch.MCU.XASI.BoomCylPrs";
BA_ "VssSig" SG_ 2566902817 RrPmpPrs "Mch.MCU.XASI.RrPmpPrs";
BA_ "VssSig" SG_ 2566902817 FrPmpPrs "Mch.MCU.XASI.FrPmpPrs";
BA_ "VssSig" SG_ 2566903073 VariBladeFanEvc "Mch.MCU.XAAI.VariBladeFanEvc";
BA_ "VssSig" SG_ 2566903073 BoomSwgCcwEvc "Mch.MCU.XAAI.BoomSwgCcwEvc";
BA_ "VssSig" SG_ 2566903073 BoomSwgCwEvc "Mch.MCU.XAAI.BoomSwgCwEvc";
BA_ "VssSig" SG_ 2566903073 TrvlPmpEvc "Mch.MCU.XAAI.TrvlPmpEvc";
BA_ "VssSig" SG_ 2566903073 Pmp3Evc "Mch.MCU.XAAI.Pmp3Evc";
BA_ "VssSig" SG_ 2566903073 DzDnEvc "Mch.MCU.XAAI.DzDnEvc";
BA_ "VssSig" SG_ 2566903073 DzUpEvc "Mch.MCU.XAAI.DzUpEvc";
BA_ "VssSig" SG_ 2566903073 ArtiBoomDnEvc "Mch.MCU.XAAI.ArtiBoomDnEvc";
BA_ "VssSig" SG_ 2566903073 ArtiBoomUpEvc "Mch.MCU.XAAI.ArtiBoomUpEvc";
BA_ "VssSig" SG_ 2566903073 SwgLhEvc "Mch.MCU.XAAI.SwgLhEvc";
BA_ "VssSig" SG_ 2566903073 SwgRhEvc "Mch.MCU.XAAI.SwgRhEvc";
BA_ "VssSig" SG_ 2566903073 TrvlLhRvsEvc "Mch.MCU.XAAI.TrvlLhRvsEvc";
BA_ "VssSig" SG_ 2566903073 TrvlLhFwdEvc "Mch.MCU.XAAI.TrvlLhFwdEvc";
BA_ "VssSig" SG_ 2566903073 TrvlRhRvsEvc "Mch.MCU.XAAI.TrvlRhRvsEvc";
BA_ "VssSig" SG_ 2566903073 TrvlRhFwdEvc "Mch.MCU.XAAI.TrvlRhFwdEvc";
BA_ "VssSig" SG_ 2566903073 BckDumpEvc "Mch.MCU.XAAI.BckDumpEvc";
BA_ "VssSig" SG_ 2566903073 BckCrowdEvc "Mch.MCU.XAAI.BckCrowdEvc";
BA_ "VssSig" SG_ 2566903073 Arm2DumpEvc "Mch.MCU.XAAI.Arm2DumpEvc";
BA_ "VssSig" SG_ 2566903073 Arm2CrowdEvc "Mch.MCU.XAAI.Arm2CrowdEvc";
BA_ "VssSig" SG_ 2566903073 Arm1DumpEvc "Mch.MCU.XAAI.Arm1DumpEvc";
BA_ "VssSig" SG_ 2566903073 Arm1CrowdEvc "Mch.MCU.XAAI.Arm1CrowdEvc";
BA_ "VssSig" SG_ 2566903073 Boom2UpEvc "Mch.MCU.XAAI.Boom2UpEvc";
BA_ "VssSig" SG_ 2566903073 Boom1DnEvc "Mch.MCU.XAAI.Boom1DnEvc";
BA_ "VssSig" SG_ 2566903073 Boom1UpEvc "Mch.MCU.XAAI.Boom1UpEvc";
BA_ "VssSig" SG_ 2566903073 ArmLckEvc "Mch.MCU.XAAI.ArmLckEvc";
BA_ "VssSig" SG_ 2566903073 BckCrowdConfEvc "Mch.MCU.XAAI.BckCrowdConfEvc";
BA_ "VssSig" SG_ 2566903073 ArmCrowdConfEvc "Mch.MCU.XAAI.ArmCrowdConfEvc";
BA_ "VssSig" SG_ 2566903073 BoomUpConfEvc "Mch.MCU.XAAI.BoomUpConfEvc";
BA_ "VssSig" SG_ 2566903073 BypassCutOffBEvc "Mch.MCU.XAAI.BypassCutOffBEvc";
BA_ "VssSig" SG_ 2566903073 BypassCutOffAEvc "Mch.MCU.XAAI.BypassCutOffAEvc";
BA_ "VssSig" SG_ 2566903073 Trvl2PmpCmbEvc "Mch.MCU.XAAI.Trvl2PmpCmbEvc";
BA_ "VssSig" SG_ 2566903073 TrvlFwdEvc "Mch.MCU.XAAI.TrvlFwdEvc";
BA_ "VssSig" SG_ 2566903073 PrsCtrl2Evc "Mch.MCU.XAAI.PrsCtrl2Evc";
BA_ "VssSig" SG_ 2566903073 PrsCtrl1Evc "Mch.MCU.XAAI.PrsCtrl1Evc";
BA_ "VssSig" SG_ 2566903073 RttCcwEvc "Mch.MCU.XAAI.RttCcwEvc";
BA_ "VssSig" SG_ 2566903073 RttCwEvc "Mch.MCU.XAAI.RttCwEvc";
BA_ "VssSig" SG_ 2566903073 TwCloseEvc "Mch.MCU.XAAI.TwCloseEvc";
BA_ "VssSig" SG_ 2566903073 TwOpenEvc "Mch.MCU.XAAI.TwOpenEvc";
BA_ "VssSig" SG_ 2566903073 FlwCtrlEvc "Mch.MCU.XAAI.FlwCtrlEvc";
BA_ "VssSig" SG_ 2566903073 CoolFanEvc "Mch.MCU.XAAI.CoolFanEvc";
BA_ "VssSig" SG_ 2566903073 PmpElecEvc "Mch.MCU.XAAI.PmpElecEvc";
BA_ "VssSig" SG_ 2566903073 Pmp1Evc "Mch.MCU.XAAI.Pmp1Evc";
BA_ "VssSig" SG_ 2566903329 MainStRpmpPrsSw "Mch.MCU.XDSI.MainStRpmpPrsSw";
BA_ "VssSig" SG_ 2566903329 GndSawInitSw "Mch.MCU.XDSI.GndSawInitSw";
BA_ "VssSig" SG_ 2566903329 FanErrSig "Mch.MCU.XDSI.FanErrSig";
BA_ "VssSig" SG_ 2566903329 HydWakeUpSw "Mch.MCU.XDSI.HydWakeUpSw";
BA_ "VssSig" SG_ 2566903329 EmgStpSw "Mch.MCU.XDSI.EmgStpSw";
BA_ "VssSig" SG_ 2566903329 HhVltChgSw "Mch.MCU.XDSI.HhVltChgSw";
BA_ "VssSig" SG_ 2566903329 PrkBrkPrsSw "Mch.MCU.XDSI.PrkBrkPrsSw";
BA_ "VssSig" SG_ 2566903329 RamLckRvsSw "Mch.MCU.XDSI.RamLckRvsSw";
BA_ "VssSig" SG_ 2566903329 AirCompPrsSw "Mch.MCU.XDSI.AirCompPrsSw";
BA_ "VssSig" SG_ 2566903329 Mg2DJoyTrigSw "Mch.MCU.XDSI.Mg2DJoyTrigSw";
BA_ "VssSig" SG_ 2566903329 KeySwBr "Mch.MCU.XDSI.KeySwBr";
BA_ "VssSig" SG_ 2566903329 TwSwSelSw "Mch.MCU.XDSI.TwSwSelSw";
BA_ "VssSig" SG_ 2566903329 DzOutSw "Mch.MCU.XDSI.DzOutSw";
BA_ "VssSig" SG_ 2566903329 MrrHtSw "Mch.MCU.XDSI.MrrHtSw";
BA_ "VssSig" SG_ 2566903329 SwgAlignSw "Mch.MCU.XDSI.SwgAlignSw";
BA_ "VssSig" SG_ 2566903329 MultiFuncSw "Mch.MCU.XDSI.MultiFuncSw";
BA_ "VssSig" SG_ 2566903329 AutoDigSw "Mch.MCU.XDSI.AutoDigSw";
BA_ "VssSig" SG_ 2566903329 TrvlPmpHhSpdSw "Mch.MCU.XDSI.TrvlPmpHhSpdSw";
BA_ "VssSig" SG_ 2566903329 DoorSw "Mch.MCU.XDSI.DoorSw";
BA_ "VssSig" SG_ 2566903329 RrAxleRhHallSsSw "Mch.MCU.XDSI.RrAxleRhHallSsSw";
BA_ "VssSig" SG_ 2566903329 RrAxleLhHallSsSw "Mch.MCU.XDSI.RrAxleLhHallSsSw";
BA_ "VssSig" SG_ 2566903329 FrAxleHallSsSw "Mch.MCU.XDSI.FrAxleHallSsSw";
BA_ "VssSig" SG_ 2566903329 QckCouplerRhSw "Mch.MCU.XDSI.QckCouplerRhSw";
BA_ "VssSig" SG_ 2566903329 QckCouplerLhSw "Mch.MCU.XDSI.QckCouplerLhSw";
BA_ "VssSig" SG_ 2566903329 PowMdSw "Mch.MCU.XDSI.PowMdSw";
BA_ "VssSig" SG_ 2566903329 WrkMdSw "Mch.MCU.XDSI.WrkMdSw";
BA_ "VssSig" SG_ 2566903329 AuxMdSelSw "Mch.MCU.XDSI.AuxMdSelSw";
BA_ "VssSig" SG_ 2566903329 SwgBrkRlsSw "Mch.MCU.XDSI.SwgBrkRlsSw";
BA_ "VssSig" SG_ 2566903329 BrkrFltSw "Mch.MCU.XDSI.BrkrFltSw";
BA_ "VssSig" SG_ 2566903329 SwgPriSw "Mch.MCU.XDSI.SwgPriSw";
BA_ "VssSig" SG_ 2566903329 RttCwSw "Mch.MCU.XDSI.RttCwSw";
BA_ "VssSig" SG_ 2566903329 RttCcwSw "Mch.MCU.XDSI.RttCcwSw";
BA_ "VssSig" SG_ 2566903329 WiperWasherSw "Mch.MCU.XDSI.WiperWasherSw";
BA_ "VssSig" SG_ 2566903329 WiperContSw "Mch.MCU.XDSI.WiperContSw";
BA_ "VssSig" SG_ 2566903329 Wiper2StepSw "Mch.MCU.XDSI.Wiper2StepSw";
BA_ "VssSig" SG_ 2566903329 Wiper1StepSw "Mch.MCU.XDSI.Wiper1StepSw";
BA_ "VssSig" SG_ 2566903329 TmsSt "Mch.MCU.XDSI.TmsSt";
BA_ "VssSig" SG_ 2566903329 ArtiBoomPrsSw "Mch.MCU.XDSI.ArtiBoomPrsSw";
BA_ "VssSig" SG_ 2566903329 CoolLvSw "Mch.MCU.XDSI.CoolLvSw";
BA_ "VssSig" SG_ 2566903329 RttOprSw "Mch.MCU.XDSI.RttOprSw";
BA_ "VssSig" SG_ 2566903329 TwCloseOprSw "Mch.MCU.XDSI.TwCloseOprSw";
BA_ "VssSig" SG_ 2566903329 TwOpenOprSw "Mch.MCU.XDSI.TwOpenOprSw";
BA_ "VssSig" SG_ 2566903329 RcwCloseSw "Mch.MCU.XDSI.RcwCloseSw";
BA_ "VssSig" SG_ 2566903329 RcwOprSw "Mch.MCU.XDSI.RcwOprSw";
BA_ "VssSig" SG_ 2566903329 EmgEgStpSw "Mch.MCU.XDSI.EmgEgStpSw";
BA_ "VssSig" SG_ 2566903329 OwOptPdlPrsSw "Mch.MCU.XDSI.OwOptPdlPrsSw";
BA_ "VssSig" SG_ 2566903329 SpcSw "Mch.MCU.XDSI.SpcSw";
BA_ "VssSig" SG_ 2566903329 IhbSw "Mch.MCU.XDSI.IhbSw";
BA_ "VssSig" SG_ 2566903329 TrvlAlmSelSw "Mch.MCU.XDSI.TrvlAlmSelSw";
BA_ "VssSig" SG_ 2566903329 SwgAlmSelSw "Mch.MCU.XDSI.SwgAlmSelSw";
BA_ "VssSig" SG_ 2566903329 EmgStrSw "Mch.MCU.XDSI.EmgStrSw";
BA_ "VssSig" SG_ 2566903329 HhBeamSw "Mch.MCU.XDSI.HhBeamSw";
BA_ "VssSig" SG_ 2566903329 StpLmp "Mch.MCU.XDSI.StpLmp";
BA_ "VssSig" SG_ 2566903329 AccPdlSw "Mch.MCU.XDSI.AccPdlSw";
BA_ "VssSig" SG_ 2566903329 BrkPrsSw "Mch.MCU.XDSI.BrkPrsSw";
BA_ "VssSig" SG_ 2566903329 Cruise "Mch.MCU.XDSI.Cruise";
BA_ "VssSig" SG_ 2566903329 EgOilPrsSw "Mch.MCU.XDSI.EgOilPrsSw";
BA_ "VssSig" SG_ 2566903329 WrkPxPrsSw "Mch.MCU.XDSI.WrkPxPrsSw";
BA_ "VssSig" SG_ 2566903329 TrvlPyPrsSw "Mch.MCU.XDSI.TrvlPyPrsSw";
BA_ "VssSig" SG_ 2566903329 IgnSw "Mch.MCU.XDSI.IgnSw";
BA_ "VssSig" SG_ 2566903329 RamLckAutoSw "Mch.MCU.XDSI.RamLckAutoSw";
BA_ "VssSig" SG_ 2566903329 PreHt "Mch.MCU.XDSI.PreHt";
BA_ "VssSig" SG_ 2566903329 WifWrn "Mch.MCU.XDSI.WifWrn";
BA_ "VssSig" SG_ 2566903329 SwgPrsSw "Mch.MCU.XDSI.SwgPrsSw";
BA_ "VssSig" SG_ 2566903329 JoyPtnBhl "Mch.MCU.XDSI.JoyPtnBhl";
BA_ "VssSig" SG_ 2566903329 JoyPtnIso "Mch.MCU.XDSI.JoyPtnIso";
BA_ "VssSig" SG_ 2566903329 RvsFanSw "Mch.MCU.XDSI.RvsFanSw";
BA_ "VssSig" SG_ 2566903329 TwOptPdlPrsSw "Mch.MCU.XDSI.TwOptPdlPrsSw";
BA_ "VssSig" SG_ 2566903329 BrkOilPrsWrn "Mch.MCU.XDSI.BrkOilPrsWrn";
BA_ "VssSig" SG_ 2566903329 OwdWrnSelSw "Mch.MCU.XDSI.OwdWrnSelSw";
BA_ "VssSig" SG_ 2566903329 RetFiltWrn "Mch.MCU.XDSI.RetFiltWrn";
BA_ "VssSig" SG_ 2566903329 PilotFiltWrn "Mch.MCU.XDSI.PilotFiltWrn";
BA_ "VssSig" SG_ 2566903329 AirCleanerWrn "Mch.MCU.XDSI.AirCleanerWrn";
BA_ "VssSig" SG_ 2566903329 PilotCutOffSw "Mch.MCU.XDSI.PilotCutOffSw";
BA_ "VssSig" SG_ 2566903329 ItgtBoomSw "Mch.MCU.XDSI.ItgtBoomSw";
BA_ "VssSig" SG_ 2566903329 OneTouchRedSpdSw "Mch.MCU.XDSI.OneTouchRedSpdSw";
BA_ "VssSig" SG_ 2566903329 RamLckSw "Mch.MCU.XDSI.RamLckSw";
BA_ "VssSig" SG_ 2566903329 PrkSw "Mch.MCU.XDSI.PrkSw";
BA_ "VssSig" SG_ 2566903329 AirCndSw "Mch.MCU.XDSI.AirCndSw";
BA_ "VssSig" SG_ 2566903329 JoyDirSelSw "Mch.MCU.XDSI.JoyDirSelSw";
BA_ "VssSig" SG_ 2566903329 TrvlBwdSw "Mch.MCU.XDSI.TrvlBwdSw";
BA_ "VssSig" SG_ 2566903329 TrvlNtrlSw "Mch.MCU.XDSI.TrvlNtrlSw";
BA_ "VssSig" SG_ 2566903329 TrvlFwdSw "Mch.MCU.XDSI.TrvlFwdSw";
BA_ "VssSig" SG_ 2566903329 HhSpdSelSw "Mch.MCU.XDSI.HhSpdSelSw";
BA_ "VssSig" SG_ 2566903329 LwSpdSelSw "Mch.MCU.XDSI.LwSpdSelSw";
BA_ "VssSig" SG_ 2566903329 InchingSelSw "Mch.MCU.XDSI.InchingSelSw";
BA_ "VssSig" SG_ 2566903329 QckCoupler "Mch.MCU.XDSI.QckCoupler";
BA_ "VssSig" SG_ 2566903329 TwSelSw "Mch.MCU.XDSI.TwSelSw";
BA_ "VssSig" SG_ 2566903329 OnwWaySelSw "Mch.MCU.XDSI.OnwWaySelSw";
BA_ "VssSig" SG_ 2566903329 WrkLmpSw "Mch.MCU.XDSI.WrkLmpSw";
BA_ "VssSig" SG_ 2566903329 AutoTrvl2SpdSw "Mch.MCU.XDSI.AutoTrvl2SpdSw";
BA_ "VssSig" SG_ 2566903329 Trvl2SpdSelSw "Mch.MCU.XDSI.Trvl2SpdSelSw";
BA_ "VssSig" SG_ 2566903329 TrvlSelSw "Mch.MCU.XDSI.TrvlSelSw";
BA_ "VssSig" SG_ 2566903329 BrkrSw "Mch.MCU.XDSI.BrkrSw";
BA_ "VssSig" SG_ 2566903329 PwrMaxSw "Mch.MCU.XDSI.PwrMaxSw";
BA_ "VssSig" SG_ 2566903329 Alt "Mch.MCU.XDSI.Alt";
BA_ "VssSig" SG_ 2566903585 EmgStrSv "Mch.MCU.XDAI.EmgStrSv";
BA_ "VssSig" SG_ 2566903585 TrvlRhPilotCutOffSv "Mch.MCU.XDAI.TrvlRhPilotCutOffSv";
BA_ "VssSig" SG_ 2566903585 GndSawMdChangeRly "Mch.MCU.XDAI.GndSawMdChangeRly";
BA_ "VssSig" SG_ 2566903585 HvChgSig "Mch.MCU.XDAI.HvChgSig";
BA_ "VssSig" SG_ 2566903585 FanPwmSig "Mch.MCU.XDAI.FanPwmSig";
BA_ "VssSig" SG_ 2566903585 TrkExpationSv "Mch.MCU.XDAI.TrkExpationSv";
BA_ "VssSig" SG_ 2566903585 HhVltMainRly "Mch.MCU.XDAI.HhVltMainRly";
BA_ "VssSig" SG_ 2566903585 HhVltPreChgRly "Mch.MCU.XDAI.HhVltPreChgRly";
BA_ "VssSig" SG_ 2566903585 PilotBz "Mch.MCU.XDAI.PilotBz";
BA_ "VssSig" SG_ 2566903585 QckChgInd "Mch.MCU.XDAI.QckChgInd";
BA_ "VssSig" SG_ 2566903585 QckChgRly "Mch.MCU.XDAI.QckChgRly";
BA_ "VssSig" SG_ 2566903585 NormChgInd "Mch.MCU.XDAI.NormChgInd";
BA_ "VssSig" SG_ 2566903585 LwVltMainRly "Mch.MCU.XDAI.LwVltMainRly";
BA_ "VssSig" SG_ 2566903585 BoomSwgSelRly "Mch.MCU.XDAI.BoomSwgSelRly";
BA_ "VssSig" SG_ 2566903585 PmpDeratSv "Mch.MCU.XDAI.PmpDeratSv";
BA_ "VssSig" SG_ 2566903585 PrkBrkRly "Mch.MCU.XDAI.PrkBrkRly";
BA_ "VssSig" SG_ 2566903585 RvsLmpRly "Mch.MCU.XDAI.RvsLmpRly";
BA_ "VssSig" SG_ 2566903585 AirCompRly "Mch.MCU.XDAI.AirCompRly";
BA_ "VssSig" SG_ 2566903585 CabLmpRly "Mch.MCU.XDAI.CabLmpRly";
BA_ "VssSig" SG_ 2566903585 AvmWrnSig "Mch.MCU.XDAI.AvmWrnSig";
BA_ "VssSig" SG_ 2566903585 WrkLmpRly "Mch.MCU.XDAI.WrkLmpRly";
BA_ "VssSig" SG_ 2566903585 AirCondCompStpSig "Mch.MCU.XDAI.AirCondCompStpSig";
BA_ "VssSig" SG_ 2566903585 Chmsl "Mch.MCU.XDAI.Chmsl";
BA_ "VssSig" SG_ 2566903585 BoomSusRodSv "Mch.MCU.XDAI.BoomSusRodSv";
BA_ "VssSig" SG_ 2566903585 BoomSusHedSv "Mch.MCU.XDAI.BoomSusHedSv";
BA_ "VssSig" SG_ 2566903585 MrrHt "Mch.MCU.XDAI.MrrHt";
BA_ "VssSig" SG_ 2566903585 ClearLmp "Mch.MCU.XDAI.ClearLmp";
BA_ "VssSig" SG_ 2566903585 HhHeadLmp "Mch.MCU.XDAI.HhHeadLmp";
BA_ "VssSig" SG_ 2566903585 LwHeadLmp "Mch.MCU.XDAI.LwHeadLmp";
BA_ "VssSig" SG_ 2566903585 FineSwgSv "Mch.MCU.XDAI.FineSwgSv";
BA_ "VssSig" SG_ 2566903585 TurnRhSigLmp "Mch.MCU.XDAI.TurnRhSigLmp";
BA_ "VssSig" SG_ 2566903585 TurnLhSigLmp "Mch.MCU.XDAI.TurnLhSigLmp";
BA_ "VssSig" SG_ 2566903585 BeaconRly "Mch.MCU.XDAI.BeaconRly";
BA_ "VssSig" SG_ 2566903585 LightRly "Mch.MCU.XDAI.LightRly";
BA_ "VssSig" SG_ 2566903585 LmpRly "Mch.MCU.XDAI.LmpRly";
BA_ "VssSig" SG_ 2566903585 RamLckSv "Mch.MCU.XDAI.RamLckSv";
BA_ "VssSig" SG_ 2566903585 LwSpdTrvlSv "Mch.MCU.XDAI.LwSpdTrvlSv";
BA_ "VssSig" SG_ 2566903585 TrvlPmpHhSpd2Sv "Mch.MCU.XDAI.TrvlPmpHhSpd2Sv";
BA_ "VssSig" SG_ 2566903585 TrvlPmpHhSpd1Sv "Mch.MCU.XDAI.TrvlPmpHhSpd1Sv";
BA_ "VssSig" SG_ 2566903585 WiperWasherRly "Mch.MCU.XDAI.WiperWasherRly";
BA_ "VssSig" SG_ 2566903585 WiperRly "Mch.MCU.XDAI.WiperRly";
BA_ "VssSig" SG_ 2566903585 AutoShutOffRly "Mch.MCU.XDAI.AutoShutOffRly";
BA_ "VssSig" SG_ 2566903585 AirHtRly "Mch.MCU.XDAI.AirHtRly";
BA_ "VssSig" SG_ 2566903585 GlowPlugPreHhRly2 "Mch.MCU.XDAI.GlowPlugPreHhRly2";
BA_ "VssSig" SG_ 2566903585 GlowPlugPreHhRly1 "Mch.MCU.XDAI.GlowPlugPreHhRly1";
BA_ "VssSig" SG_ 2566903585 HhSpdRly "Mch.MCU.XDAI.HhSpdRly";
BA_ "VssSig" SG_ 2566903585 LwSpdRly "Mch.MCU.XDAI.LwSpdRly";
BA_ "VssSig" SG_ 2566903585 InchingRly "Mch.MCU.XDAI.InchingRly";
BA_ "VssSig" SG_ 2566903585 SpareRly "Mch.MCU.XDAI.SpareRly";
BA_ "VssSig" SG_ 2566903585 BackBzRly "Mch.MCU.XDAI.BackBzRly";
BA_ "VssSig" SG_ 2566903585 StartRly "Mch.MCU.XDAI.StartRly";
BA_ "VssSig" SG_ 2566903585 AutoBrkSv "Mch.MCU.XDAI.AutoBrkSv";
BA_ "VssSig" SG_ 2566903585 PilotCutOffSv "Mch.MCU.XDAI.PilotCutOffSv";
BA_ "VssSig" SG_ 2566903585 McvEpprCutOffSv "Mch.MCU.XDAI.McvEpprCutOffSv";
BA_ "VssSig" SG_ 2566903585 BsSpoolSc "Mch.MCU.XDAI.BsSpoolSc";
BA_ "VssSig" SG_ 2566903585 QckCouplerSv "Mch.MCU.XDAI.QckCouplerSv";
BA_ "VssSig" SG_ 2566903585 FreeBoomDnSv "Mch.MCU.XDAI.FreeBoomDnSv";
BA_ "VssSig" SG_ 2566903585 FreeBoomUpSv "Mch.MCU.XDAI.FreeBoomUpSv";
BA_ "VssSig" SG_ 2566903585 TrvlStrgtSv "Mch.MCU.XDAI.TrvlStrgtSv";
BA_ "VssSig" SG_ 2566903585 RttCcwSv "Mch.MCU.XDAI.RttCcwSv";
BA_ "VssSig" SG_ 2566903585 RttCwSv "Mch.MCU.XDAI.RttCwSv";
BA_ "VssSig" SG_ 2566903585 Trvl2PmpCmbSv "Mch.MCU.XDAI.Trvl2PmpCmbSv";
BA_ "VssSig" SG_ 2566903585 OptPdlSaftySv "Mch.MCU.XDAI.OptPdlSaftySv";
BA_ "VssSig" SG_ 2566903585 ForceRgnSv "Mch.MCU.XDAI.ForceRgnSv";
BA_ "VssSig" SG_ 2566903585 TwOprSv "Mch.MCU.XDAI.TwOprSv";
BA_ "VssSig" SG_ 2566903585 UnloadSv "Mch.MCU.XDAI.UnloadSv";
BA_ "VssSig" SG_ 2566903585 TwRhCloseSv "Mch.MCU.XDAI.TwRhCloseSv";
BA_ "VssSig" SG_ 2566903585 TwRhOpenSv "Mch.MCU.XDAI.TwRhOpenSv";
BA_ "VssSig" SG_ 2566903585 SwgBrkRelSv "Mch.MCU.XDAI.SwgBrkRelSv";
BA_ "VssSig" SG_ 2566903585 BypassCutOffSv "Mch.MCU.XDAI.BypassCutOffSv";
BA_ "VssSig" SG_ 2566903585 RwdSv "Mch.MCU.XDAI.RwdSv";
BA_ "VssSig" SG_ 2566903585 FwdSv "Mch.MCU.XDAI.FwdSv";
BA_ "VssSig" SG_ 2566903585 CruiseSv "Mch.MCU.XDAI.CruiseSv";
BA_ "VssSig" SG_ 2566903585 TwoPmpSelSv "Mch.MCU.XDAI.TwoPmpSelSv";
BA_ "VssSig" SG_ 2566903585 FanRvsSv "Mch.MCU.XDAI.FanRvsSv";
BA_ "VssSig" SG_ 2566903585 BrkrSelSv "Mch.MCU.XDAI.BrkrSelSv";
BA_ "VssSig" SG_ 2566903585 HhSpdTrvlSv "Mch.MCU.XDAI.HhSpdTrvlSv";
BA_ "VssSig" SG_ 2566903585 PowMaxSv "Mch.MCU.XDAI.PowMaxSv";
BA_ "VssSig" SG_ 2566903585 BrkrOprSv "Mch.MCU.XDAI.BrkrOprSv";
BA_ "VssSig" SG_ 2566903841 TmsSecVlt "Mch.MCU.LASI.TmsSecVlt";
BA_ "VssSig" SG_ 2566903841 RsvJoy1GripYPos "Mch.MCU.LASI.RsvJoy1GripYPos";
BA_ "VssSig" SG_ 2566903841 Joy1GripYPos "Mch.MCU.LASI.Joy1GripYPos";
BA_ "VssSig" SG_ 2566903841 RsvJoy1YPos "Mch.MCU.LASI.RsvJoy1YPos";
BA_ "VssSig" SG_ 2566903841 Joy1YPos "Mch.MCU.LASI.Joy1YPos";
BA_ "VssSig" SG_ 2566903841 RsvJoy1XPos "Mch.MCU.LASI.RsvJoy1XPos";
BA_ "VssSig" SG_ 2566903841 Joy1XPos "Mch.MCU.LASI.Joy1XPos";
BA_ "VssSig" SG_ 2566903841 EmcvLeverOptB "Mch.MCU.LASI.EmcvLeverOptB";
BA_ "VssSig" SG_ 2566903841 EmcvLeverOptA "Mch.MCU.LASI.EmcvLeverOptA";
BA_ "VssSig" SG_ 2566903841 EmcvLeverBckB "Mch.MCU.LASI.EmcvLeverBckB";
BA_ "VssSig" SG_ 2566903841 EmcvLeverBckA "Mch.MCU.LASI.EmcvLeverBckA";
BA_ "VssSig" SG_ 2566903841 EmcvLeverBoomB "Mch.MCU.LASI.EmcvLeverBoomB";
BA_ "VssSig" SG_ 2566903841 EmcvLeverBoomA "Mch.MCU.LASI.EmcvLeverBoomA";
BA_ "VssSig" SG_ 2566903841 ElecStrVv "Mch.MCU.LASI.ElecStrVv";
BA_ "VssSig" SG_ 2566903841 ElecStrLeverB "Mch.MCU.LASI.ElecStrLeverB";
BA_ "VssSig" SG_ 2566903841 ElecStrLeverA "Mch.MCU.LASI.ElecStrLeverA";
BA_ "VssSig" SG_ 2566903841 AcpSsPrs "Mch.MCU.LASI.AcpSsPrs";
BA_ "VssSig" SG_ 2566903841 BatTmp "Mch.MCU.LASI.BatTmp";
BA_ "VssSig" SG_ 2566903841 AltTmp "Mch.MCU.LASI.AltTmp";
BA_ "VssSig" SG_ 2566903841 AxleOilTmp "Mch.MCU.LASI.AxleOilTmp";
BA_ "VssSig" SG_ 2566903841 HydOilTmp "Mch.MCU.LASI.HydOilTmp";
BA_ "VssSig" SG_ 2566903841 CoolTmp "Mch.MCU.LASI.CoolTmp";
BA_ "VssSig" SG_ 2566903841 OpsSsVlt "Mch.MCU.LASI.OpsSsVlt";
BA_ "VssSig" SG_ 2566903841 WifSsVlt "Mch.MCU.LASI.WifSsVlt";
BA_ "VssSig" SG_ 2566903841 FuelLv "Mch.MCU.LASI.FuelLv";
BA_ "VssSig" SG_ 2566903841 BrkPdlB "Mch.MCU.LASI.BrkPdlB";
BA_ "VssSig" SG_ 2566903841 BrkPdlA "Mch.MCU.LASI.BrkPdlA";
BA_ "VssSig" SG_ 2566903841 AccPdlVlt "Mch.MCU.LASI.AccPdlVlt";
BA_ "VssSig" SG_ 2566903841 CtlLsPrs "Mch.MCU.LASI.CtlLsPrs";
BA_ "VssSig" SG_ 2566903841 CtlTowSpdPrs "Mch.MCU.LASI.CtlTowSpdPrs";
BA_ "VssSig" SG_ 2566903841 AngSsBckB "Mch.MCU.LASI.AngSsBckB";
BA_ "VssSig" SG_ 2566903841 AngSsBckA "Mch.MCU.LASI.AngSsBckA";
BA_ "VssSig" SG_ 2566903841 AngSsBoomB "Mch.MCU.LASI.AngSsBoomB";
BA_ "VssSig" SG_ 2566903841 AngSsBoomA "Mch.MCU.LASI.AngSsBoomA";
BA_ "VssSig" SG_ 2566903841 CtlBckLoadPrs "Mch.MCU.LASI.CtlBckLoadPrs";
BA_ "VssSig" SG_ 2566903841 CtlEgCtrlDialVlt "Mch.MCU.LASI.CtlEgCtrlDialVlt";
BA_ "VssSig" SG_ 2566903841 PrkBrkPrs "Mch.MCU.LASI.PrkBrkPrs";
BA_ "VssSig" SG_ 2566903841 FanMotPrs "Mch.MCU.LASI.FanMotPrs";
BA_ "VssSig" SG_ 2566903841 BrkOilPrs "Mch.MCU.LASI.BrkOilPrs";
BA_ "VssSig" SG_ 2566903841 StrPrs "Mch.MCU.LASI.StrPrs";
BA_ "VssSig" SG_ 2566903841 BoomRodPrs "Mch.MCU.LASI.BoomRodPrs";
BA_ "VssSig" SG_ 2566903841 BooHeadPrs "Mch.MCU.LASI.BooHeadPrs";
BA_ "VssSig" SG_ 2566903841 MainPrs "Mch.MCU.LASI.MainPrs";
BA_ "VssSig" SG_ 2566904097 CacFanCtrl "Mch.MCU.LAAI.CacFanCtrl";
BA_ "VssSig" SG_ 2566904097 CdsFanCtrl "Mch.MCU.LAAI.CdsFanCtrl";
BA_ "VssSig" SG_ 2566904097 RipperDnEvc "Mch.MCU.LAAI.RipperDnEvc";
BA_ "VssSig" SG_ 2566904097 RipperUpEvc "Mch.MCU.LAAI.RipperUpEvc";
BA_ "VssSig" SG_ 2566904097 BladeAngLhEvc "Mch.MCU.LAAI.BladeAngLhEvc";
BA_ "VssSig" SG_ 2566904097 BladeAngRhEvc "Mch.MCU.LAAI.BladeAngRhEvc";
BA_ "VssSig" SG_ 2566904097 BladeDnEvc "Mch.MCU.LAAI.BladeDnEvc";
BA_ "VssSig" SG_ 2566904097 BladeRaiseEvc "Mch.MCU.LAAI.BladeRaiseEvc";
BA_ "VssSig" SG_ 2566904097 BladeTiltLhEvc "Mch.MCU.LAAI.BladeTiltLhEvc";
BA_ "VssSig" SG_ 2566904097 BladeTiltRhEvc "Mch.MCU.LAAI.BladeTiltRhEvc";
BA_ "VssSig" SG_ 2566904097 Spool4BEvc "Mch.MCU.LAAI.Spool4BEvc";
BA_ "VssSig" SG_ 2566904097 Spool4AEvc "Mch.MCU.LAAI.Spool4AEvc";
BA_ "VssSig" SG_ 2566904097 Opt2Evc "Mch.MCU.LAAI.Opt2Evc";
BA_ "VssSig" SG_ 2566904097 Opt1Evc "Mch.MCU.LAAI.Opt1Evc";
BA_ "VssSig" SG_ 2566904097 BckDumpEvc "Mch.MCU.LAAI.BckDumpEvc";
BA_ "VssSig" SG_ 2566904097 BoomCrowdEvc "Mch.MCU.LAAI.BoomCrowdEvc";
BA_ "VssSig" SG_ 2566904097 BoomFltEvc "Mch.MCU.LAAI.BoomFltEvc";
BA_ "VssSig" SG_ 2566904097 BoomRaiseEvc "Mch.MCU.LAAI.BoomRaiseEvc";
BA_ "VssSig" SG_ 2566904097 FanCtrlEvc "Mch.MCU.LAAI.FanCtrlEvc";
BA_ "VssSig" SG_ 2566904353 OpsSw "Mch.MCU.LDSI.OpsSw";
BA_ "VssSig" SG_ 2566904353 HhFlowPinK "Mch.MCU.LDSI.HhFlowPinK";
BA_ "VssSig" SG_ 2566904353 HhFlowPinN "Mch.MCU.LDSI.HhFlowPinN";
BA_ "VssSig" SG_ 2566904353 DustInd "Mch.MCU.LDSI.DustInd";
BA_ "VssSig" SG_ 2566904353 FrDoorSw "Mch.MCU.LDSI.FrDoorSw";
BA_ "VssSig" SG_ 2566904353 ArmRestLhSw "Mch.MCU.LDSI.ArmRestLhSw";
BA_ "VssSig" SG_ 2566904353 ArmRestRhSw "Mch.MCU.LDSI.ArmRestRhSw";
BA_ "VssSig" SG_ 2566904353 Spool3LeverSw "Mch.MCU.LDSI.Spool3LeverSw";
BA_ "VssSig" SG_ 2566904353 BckLeverSw "Mch.MCU.LDSI.BckLeverSw";
BA_ "VssSig" SG_ 2566904353 EgOilPrsSw "Mch.MCU.LDSI.EgOilPrsSw";
BA_ "VssSig" SG_ 2566904353 HydLckoutSw "Mch.MCU.LDSI.HydLckoutSw";
BA_ "VssSig" SG_ 2566904353 TractionCtrlSw "Mch.MCU.LDSI.TractionCtrlSw";
BA_ "VssSig" SG_ 2566904353 AirCleanSw "Mch.MCU.LDSI.AirCleanSw";
BA_ "VssSig" SG_ 2566904353 RetFiltSw "Mch.MCU.LDSI.RetFiltSw";
BA_ "VssSig" SG_ 2566904353 QckCouperLckSw "Mch.MCU.LDSI.QckCouperLckSw";
BA_ "VssSig" SG_ 2566904353 DnShftSw "Mch.MCU.LDSI.DnShftSw";
BA_ "VssSig" SG_ 2566904353 PreHt "Mch.MCU.LDSI.PreHt";
BA_ "VssSig" SG_ 2566904353 Joy1XDetentPosSt "Mch.MCU.LDSI.Joy1XDetentPosSt";
BA_ "VssSig" SG_ 2566904353 Joy1YDetentPosSt "Mch.MCU.LDSI.Joy1YDetentPosSt";
BA_ "VssSig" SG_ 2566904353 IhbSw "Mch.MCU.LDSI.IhbSw";
BA_ "VssSig" SG_ 2566904353 HstOilFiltWrn "Mch.MCU.LDSI.HstOilFiltWrn";
BA_ "VssSig" SG_ 2566904353 GrboxOvrTmp "Mch.MCU.LDSI.GrboxOvrTmp";
BA_ "VssSig" SG_ 2566904353 AgsLmp "Mch.MCU.LDSI.AgsLmp";
BA_ "VssSig" SG_ 2566904353 QckCouplerInitSw "Mch.MCU.LDSI.QckCouplerInitSw";
BA_ "VssSig" SG_ 2566904353 PrkSw "Mch.MCU.LDSI.PrkSw";
BA_ "VssSig" SG_ 2566904353 SeatBeltSw "Mch.MCU.LDSI.SeatBeltSw";
BA_ "VssSig" SG_ 2566904353 ReDefrstSw "Mch.MCU.LDSI.ReDefrstSw";
BA_ "VssSig" SG_ 2566904353 HormSw "Mch.MCU.LDSI.HormSw";
BA_ "VssSig" SG_ 2566904353 Fnr2ActSw "Mch.MCU.LDSI.Fnr2ActSw";
BA_ "VssSig" SG_ 2566904353 RearWiperStpSw "Mch.MCU.LDSI.RearWiperStpSw";
BA_ "VssSig" SG_ 2566904353 FrWiperStpSig "Mch.MCU.LDSI.FrWiperStpSig";
BA_ "VssSig" SG_ 2566904353 DpfForceRgnSw "Mch.MCU.LDSI.DpfForceRgnSw";
BA_ "VssSig" SG_ 2566904353 EmgStrPrsSw "Mch.MCU.LDSI.EmgStrPrsSw";
BA_ "VssSig" SG_ 2566904353 MainStrPrsSw "Mch.MCU.LDSI.MainStrPrsSw";
BA_ "VssSig" SG_ 2566904353 AccPdlKd "Mch.MCU.LDSI.AccPdlKd";
BA_ "VssSig" SG_ 2566904353 AccPdlIvs "Mch.MCU.LDSI.AccPdlIvs";
BA_ "VssSig" SG_ 2566904353 PrkBrkPrsSw "Mch.MCU.LDSI.PrkBrkPrsSw";
BA_ "VssSig" SG_ 2566904353 CoolLv "Mch.MCU.LDSI.CoolLv";
BA_ "VssSig" SG_ 2566904353 WghCntSw "Mch.MCU.LDSI.WghCntSw";
BA_ "VssSig" SG_ 2566904353 EmgStpSw "Mch.MCU.LDSI.EmgStpSw";
BA_ "VssSig" SG_ 2566904353 DhlManSw "Mch.MCU.LDSI.DhlManSw";
BA_ "VssSig" SG_ 2566904353 FnrR3 "Mch.MCU.LDSI.FnrR3";
BA_ "VssSig" SG_ 2566904353 FnrN3 "Mch.MCU.LDSI.FnrN3";
BA_ "VssSig" SG_ 2566904353 FnrF3 "Mch.MCU.LDSI.FnrF3";
BA_ "VssSig" SG_ 2566904353 FnrR2 "Mch.MCU.LDSI.FnrR2";
BA_ "VssSig" SG_ 2566904353 FnrN2 "Mch.MCU.LDSI.FnrN2";
BA_ "VssSig" SG_ 2566904353 FnrF2 "Mch.MCU.LDSI.FnrF2";
BA_ "VssSig" SG_ 2566904353 FnrR1 "Mch.MCU.LDSI.FnrR1";
BA_ "VssSig" SG_ 2566904353 FnrN1 "Mch.MCU.LDSI.FnrN1";
BA_ "VssSig" SG_ 2566904353 FnrF1 "Mch.MCU.LDSI.FnrF1";
BA_ "VssSig" SG_ 2566904353 StartBrSw "Mch.MCU.LDSI.StartBrSw";
BA_ "VssSig" SG_ 2566904353 StartAccSw "Mch.MCU.LDSI.StartAccSw";
BA_ "VssSig" SG_ 2566904353 StartCSw "Mch.MCU.LDSI.StartCSw";
BA_ "VssSig" SG_ 2566904353 PilotCutOffSw "Mch.MCU.LDSI.PilotCutOffSw";
BA_ "VssSig" SG_ 2566904353 ArmRestCutOffSw "Mch.MCU.LDSI.ArmRestCutOffSw";
BA_ "VssSig" SG_ 2566904353 ElecStrSelSw "Mch.MCU.LDSI.ElecStrSelSw";
BA_ "VssSig" SG_ 2566904609 Aux8Rly "Mch.MCU.LDAI.Aux8Rly";
BA_ "VssSig" SG_ 2566904609 Aux7Rly "Mch.MCU.LDAI.Aux7Rly";
BA_ "VssSig" SG_ 2566904609 Aux6Rly "Mch.MCU.LDAI.Aux6Rly";
BA_ "VssSig" SG_ 2566904609 Aux5Rly "Mch.MCU.LDAI.Aux5Rly";
BA_ "VssSig" SG_ 2566904609 Aux4Rly "Mch.MCU.LDAI.Aux4Rly";
BA_ "VssSig" SG_ 2566904609 Aux3Rly "Mch.MCU.LDAI.Aux3Rly";
BA_ "VssSig" SG_ 2566904609 AuxShutOffSv "Mch.MCU.LDAI.AuxShutOffSv";
BA_ "VssSig" SG_ 2566904609 PilotCutOffSv "Mch.MCU.LDAI.PilotCutOffSv";
BA_ "VssSig" SG_ 2566904609 FrWiperRly "Mch.MCU.LDAI.FrWiperRly";
BA_ "VssSig" SG_ 2566904609 SideWasherRly "Mch.MCU.LDAI.SideWasherRly";
BA_ "VssSig" SG_ 2566904609 UreaSuperChgWrnSig "Mch.MCU.LDAI.UreaSuperChgWrnSig";
BA_ "VssSig" SG_ 2566904609 EgRunOutSig "Mch.MCU.LDAI.EgRunOutSig";
BA_ "VssSig" SG_ 2566904609 SideWiperRly "Mch.MCU.LDAI.SideWiperRly";
BA_ "VssSig" SG_ 2566904609 FrWhaserRly "Mch.MCU.LDAI.FrWhaserRly";
BA_ "VssSig" SG_ 2566904609 FrWiperLwSigRly "Mch.MCU.LDAI.FrWiperLwSigRly";
BA_ "VssSig" SG_ 2566904609 FrWiperHhSpdRly "Mch.MCU.LDAI.FrWiperHhSpdRly";
BA_ "VssSig" SG_ 2566904609 LwBeamRly "Mch.MCU.LDAI.LwBeamRly";
BA_ "VssSig" SG_ 2566904609 HhBeamRly "Mch.MCU.LDAI.HhBeamRly";
BA_ "VssSig" SG_ 2566904609 IllmLmpRly "Mch.MCU.LDAI.IllmLmpRly";
BA_ "VssSig" SG_ 2566904609 RttBeaconRly "Mch.MCU.LDAI.RttBeaconRly";
BA_ "VssSig" SG_ 2566904609 TurnSigRhRly "Mch.MCU.LDAI.TurnSigRhRly";
BA_ "VssSig" SG_ 2566904609 TurnSigLhRly "Mch.MCU.LDAI.TurnSigLhRly";
BA_ "VssSig" SG_ 2566904609 HormRly "Mch.MCU.LDAI.HormRly";
BA_ "VssSig" SG_ 2566904609 AccRly "Mch.MCU.LDAI.AccRly";
BA_ "VssSig" SG_ 2566904609 RrWinHtRly "Mch.MCU.LDAI.RrWinHtRly";
BA_ "VssSig" SG_ 2566904609 AutoShutOffRly "Mch.MCU.LDAI.AutoShutOffRly";
BA_ "VssSig" SG_ 2566904609 BackUpBzRly "Mch.MCU.LDAI.BackUpBzRly";
BA_ "VssSig" SG_ 2566904609 MrrHtRly "Mch.MCU.LDAI.MrrHtRly";
BA_ "VssSig" SG_ 2566904609 HuelHtRly "Mch.MCU.LDAI.HuelHtRly";
BA_ "VssSig" SG_ 2566904609 GlowPlugFuelRly "Mch.MCU.LDAI.GlowPlugFuelRly";
BA_ "VssSig" SG_ 2566904609 GlowPlugRly "Mch.MCU.LDAI.GlowPlugRly";
BA_ "VssSig" SG_ 2566904609 EmgStrTestRly "Mch.MCU.LDAI.EmgStrTestRly";
BA_ "VssSig" SG_ 2566904609 RrWasherRly "Mch.MCU.LDAI.RrWasherRly";
BA_ "VssSig" SG_ 2566904609 RrWiperRly "Mch.MCU.LDAI.RrWiperRly";
BA_ "VssSig" SG_ 2566904609 RrWrkCabLmpRly "Mch.MCU.LDAI.RrWrkCabLmpRly";
BA_ "VssSig" SG_ 2566904609 RrWrkRadLmpRly "Mch.MCU.LDAI.RrWrkRadLmpRly";
BA_ "VssSig" SG_ 2566904609 FrWrkLmpRly "Mch.MCU.LDAI.FrWrkLmpRly";
BA_ "VssSig" SG_ 2566904609 ElecStrSaftyRly "Mch.MCU.LDAI.ElecStrSaftyRly";
BA_ "VssSig" SG_ 2566904609 PilotBzRly "Mch.MCU.LDAI.PilotBzRly";
BA_ "VssSig" SG_ 2566904609 LisActRly "Mch.MCU.LDAI.LisActRly";
BA_ "VssSig" SG_ 2566904609 HstCutOffRhSv "Mch.MCU.LDAI.HstCutOffRhSv";
BA_ "VssSig" SG_ 2566904609 HstCutOffLhSv "Mch.MCU.LDAI.HstCutOffLhSv";
BA_ "VssSig" SG_ 2566904609 BckMagnet "Mch.MCU.LDAI.BckMagnet";
BA_ "VssSig" SG_ 2566904609 BoomMagnet "Mch.MCU.LDAI.BoomMagnet";
BA_ "VssSig" SG_ 2566904609 HstCutOffSv "Mch.MCU.LDAI.HstCutOffSv";
BA_ "VssSig" SG_ 2566904609 HydCutOffSv "Mch.MCU.LDAI.HydCutOffSv";
BA_ "VssSig" SG_ 2566904609 StartRly "Mch.MCU.LDAI.StartRly";
BA_ "VssSig" SG_ 2566904609 QckCouplerRly "Mch.MCU.LDAI.QckCouplerRly";
BA_ "VssSig" SG_ 2566904609 EgStpRly "Mch.MCU.LDAI.EgStpRly";
BA_ "VssSig" SG_ 2566904609 PrkBrkRlsSv "Mch.MCU.LDAI.PrkBrkRlsSv";
BA_ "VssSig" SG_ 2566904609 EscortWrkLmpRly "Mch.MCU.LDAI.EscortWrkLmpRly";
BA_ "VssSig" SG_ 2566904609 AxleOilCoolSv "Mch.MCU.LDAI.AxleOilCoolSv";
BA_ "VssSig" SG_ 2566904609 UnloadSv "Mch.MCU.LDAI.UnloadSv";
BA_ "VssSig" SG_ 2566904609 BrkChgSv "Mch.MCU.LDAI.BrkChgSv";
BA_ "VssSig" SG_ 2566904609 RvsFanSV "Mch.MCU.LDAI.RvsFanSV";
VAL_ 2566893620 FobImmobilizerWrn 0 "OFF" 1 "ON (No Blinking)" 2 "ON (Normal Blinking)" 3 "ON (Slow Blinking)" ;
VAL_ 2566893620 FobLowBatWrn 0 "OFF" 1 "ON (No Blinking)" 2 "ON (Normal Blinking)" 3 "ON (Slow Blinking)" ;
VAL_ 2566893620 NoDttFobInsideCabinWrn 0 "OFF" 1 "ON (No Blinking)" 2 "ON (Normal Blinking)" 3 "ON (Slow Blinking)" ;
VAL_ 2566893620 FobRgstFdbk 0 "Default" 1 "Not Detection" 2 "Detection Complete" 3 "None" ;
VAL_ 2566893620 PreheatSt 0 "None" 1 "On" 2 "Off" 3 "Failed" ;
VAL_ 2566893620 AppLmpSt 0 "None" 1 "On" 2 "Off" 3 "Failed" ;
VAL_ 2566893620 VentilationTmp 15 "Failed" ;
VAL_ 2566893620 VentilationSt 0 "None" 1 "On" 2 "Off" 3 "Failed" ;
VAL_ 2566893620 DoorLckSt 0 "None" 1 "Lock" 2 "Unlock " 3 "Failed" ;
VAL_ 2566894388 DeicerSt 0 "Off" 1 "On" 2 "Error" 3 "N/A" ;
VAL_ 2566894388 ForcedEgStopCmd 0 "No Activation" 1 "Activation" ;
VAL_ 2566894388 RmRunningSt 0 "Normal Status" 1 "Remote Running Status" ;
VAL_ 2566894388 MaintenanceDoorSt 0 "Open" 1 "Close" ;
VAL_ 2566894388 CabinDoorSt 0 "Open" 1 "Close" ;
VAL_ 2566894388 FobDtt 0 "No Detect" 1 "Detect" ;
VAL_ 2566894388 KeyStChange 0 "Key Off" 1 "ACC" 2 "Key On" 3 "Crank or Engine Running" ;
VAL_ 2566896387 HstCutOffSVSt 0 "Off" 1 "On" 2 "Condition Green" 3 "Condition Yellow" ;
VAL_ 2566896387 TwoSpdSVSt 0 "Off" 1 "On" 2 "Condition Green" 3 "Condition Yellow" ;
VAL_ 2566896387 TrackLdTypeSybCreep 0 "Off" 1 "On" 2 "Condition Green" 3 "Condition Yellow" ;
VAL_ 2566896643 SetJoyTrvlRLTrack 0 "????" 1 "??" 2 "???" 3 "Not Defined" ;
VAL_ 2566896643 TrvlSpdPreset4Rvs 0 "Speed 0" 1 "Speed 0.5" 2 "Speed 1" 3 "Speed 1.5" 4 "Speed 2" 5 "Speed 2.5" 6 "Speed 3" 7 "Speed 3.5" 8 "Speed 4" 9 "Speed 4.5" 10 "Speed 5" ;
VAL_ 2566896643 TrvlSpdPreset4Fwd 0 "Speed 0" 1 "Speed 0.5" 2 "Speed 1" 3 "Speed 1.5" 4 "Speed 2" 5 "Speed 2.5" 6 "Speed 3" 7 "Speed 3.5" 8 "Speed 4" 9 "Speed 4.5" 10 "Speed 5" ;
VAL_ 2566896643 TrvlSpdPreset3Rvs 0 "Speed 0" 1 "Speed 0.5" 2 "Speed 1" 3 "Speed 1.5" 4 "Speed 2" 5 "Speed 2.5" 6 "Speed 3" 7 "Speed 3.5" 8 "Speed 4" 9 "Speed 4.5" 10 "Speed 5" ;
VAL_ 2566896643 TrvlSpdPreset3Fwd 0 "Speed 0" 1 "Speed 0.5" 2 "Speed 1" 3 "Speed 1.5" 4 "Speed 2" 5 "Speed 2.5" 6 "Speed 3" 7 "Speed 3.5" 8 "Speed 4" 9 "Speed 4.5" 10 "Speed 5" ;
VAL_ 2566896643 TrvlSpdPreset2Rvs 0 "Speed 0" 1 "Speed 0.5" 2 "Speed 1" 3 "Speed 1.5" 4 "Speed 2" 5 "Speed 2.5" 6 "Speed 3" 7 "Speed 3.5" 8 "Speed 4" 9 "Speed 4.5" 10 "Speed 5" ;
VAL_ 2566896643 TrvlSpdPreset2Fwd 0 "Speed 0" 1 "Speed 0.5" 2 "Speed 1" 3 "Speed 1.5" 4 "Speed 2" 5 "Speed 2.5" 6 "Speed 3" 7 "Speed 3.5" 8 "Speed 4" 9 "Speed 4.5" 10 "Speed 5" ;
VAL_ 2566896643 TrvlSpdPreset1Rvs 0 "Speed 0" 1 "Speed 0.5" 2 "Speed 1" 3 "Speed 1.5" 4 "Speed 2" 5 "Speed 2.5" 6 "Speed 3" 7 "Speed 3.5" 8 "Speed 4" 9 "Speed 4.5" 10 "Speed 5" ;
VAL_ 2566896643 TrvlSpdPreset1Fwd 0 "Speed 0" 1 "Speed 0.5" 2 "Speed 1" 3 "Speed 1.5" 4 "Speed 2" 5 "Speed 2.5" 6 "Speed 3" 7 "Speed 3.5" 8 "Speed 4" 9 "Speed 4.5" 10 "Speed 5" ;
VAL_ 2566896643 TrvlSpdSet 0 "Preset 1" 1 "Preset 2" 2 "Preset 3" 3 "Preset 4" ;
VAL_ 2566896643 BrkPdlDecel 0 "Disable" 1 "Enable" ;
VAL_ 2365570307 CurRvsMaxSpd 0 "Neutral" 1 "Speed 1" 2 "Speed 2" 3 "Speed 3" 4 "Speed 4" 5 "Speed 5" ;
VAL_ 2365570307 CurFwdMaxSpd 0 "Neutral" 1 "Speed 1" 2 "Speed 2" 3 "Speed 3" 4 "Speed 4" 5 "Speed 5" ;
VAL_ 2566897411 ParkingBrkReqSt 0 "Off" 1 "On" 2 "Error" 3 "N/A" ;
VAL_ 2566897411 CurPwrMd 0 "ECO" 1 "STD" 2 "PWR" 3 "Not available" ;
VAL_ 2566897411 CurFwdMaxSpd 0 "Speed 0" 1 "Speed 0.5" 2 "Speed 1" 3 "Speed 1.5" 4 "Speed 2" 5 "Speed 2.5" 6 "Speed 3" 7 "Speed 3.5" 8 "Speed 4" 9 "Speed 4.5" 10 "Speed 5" ;
VAL_ 2365571105 RpmReqMd 0 "Autoidle" 1 "Limphome" 3 "None" ;
VAL_ 2365571105 ReqRvsMaxSpd 0 "Neutral" 1 "Speed 1" 2 "Speed 2" 3 "Speed 3" 4 "Speed 4" 5 "Speed 5" ;
VAL_ 2365571105 ReqFwdMaxSpd 0 "Neutral" 1 "Speed 1" 2 "Speed 2" 3 "Speed 3" 4 "Speed 4" 5 "Speed 5" ;
VAL_ 2365571105 PowMd 0 "ECO" 1 "STD" 2 "PWR" 3 "N/A" ;
VAL_ 2365571105 IsParking 0 "False" 1 "True" 2 "Error" 3 "N/A" ;
VAL_ 2365571105 TractionCtrl 0 "Off" 1 "Low" 2 "Medium" 3 "High" 4 "Auto" ;
VAL_ 2566902049 OptSetTrailer 0 "Off" 1 "On" 2 "Error" 3 "N/A" ;
VAL_ 2566902049 OptSetEscortWrkLmp 0 "Off" 1 "On" 2 "Error" 3 "N/A" ;
VAL_ 2566902049 OptSetCdsRvsFanMd 0 "Off" 1 "On" 2 "Error" 3 "N/A" ;
VAL_ 2566902049 OptSetRttDir 0 "Off" 1 "On" 2 "Error" 3 "N/A" ;
VAL_ 2566902049 OptSetAdvLv 0 "Off" 1 "On" 2 "Error" 3 "N/A" ;
VAL_ 2566902049 OptSetGndSaw 0 "Off" 1 "On" 2 "Error" 3 "N/A" ;
VAL_ 2566902049 OptSetTpms 0 "Off" 1 "On" 2 "Error" 3 "N/A" ;
VAL_ 2566902049 OptSetAntiBlankFire 0 "Off" 1 "On" 2 "Error" 3 "N/A" ;
VAL_ 2566902049 OptSetJoyBoom 0 "Off" 1 "On" 2 "Error" 3 "N/A" ;
VAL_ 2566902049 OptSetJoyTilt 0 "Off" 1 "On" 2 "Error" 3 "N/A" ;
VAL_ 2566902049 OptSetHhFw 0 "Off" 1 "On" 2 "Error" 3 "N/A" ;
VAL_ 2566902049 OptSetRrCabLmp 0 "Off" 1 "On" 2 "Error" 3 "N/A" ;
VAL_ 2566902049 OptSetTrqCvtLckUp 0 "Off" 1 "On" 2 "Error" 3 "N/A" ;
VAL_ 2566902049 OptSetTwThmbWhlDir 0 "Off" 1 "On" 2 "Error" 3 "N/A" ;
VAL_ 2566902049 OptSetOptPdlType2 0 "Off" 1 "On" 2 "Error" 3 "N/A" ;
VAL_ 2566902049 OptSetDaac 0 "Off" 1 "On" 2 "Error" 3 "N/A" ;
VAL_ 2566902049 OptSetRvsLmpFuncAct 0 "Off" 1 "On" 2 "Error" 3 "N/A" ;
VAL_ 2566902049 OptSetBladeAngSens 0 "Off" 1 "On" 2 "Error" 3 "N/A" ;
VAL_ 2566902049 OptSetRaiseDnSens 0 "Off" 1 "On" 2 "Error" 3 "N/A" ;
VAL_ 2566902049 OptSetBladeTiltSens 0 "Off" 1 "On" 2 "Error" 3 "N/A" ;
VAL_ 2566902049 OptSetMrrHt 0 "Off" 1 "On" 2 "Error" 3 "N/A" ;
VAL_ 2566902049 OptSetQckCoolMd 0 "Off" 1 "On" 2 "Error" 3 "N/A" ;
VAL_ 2566902049 RttOptSet 0 "Off" 1 "On" 2 "Error" 3 "N/A" ;
VAL_ 2566902049 OptSetTrvlStrgtPdl 0 "Off" 1 "On" 2 "Error" 3 "N/A" ;
VAL_ 2566902049 OptSetAttCtrl 0 "Off" 1 "On" 2 "Error" 3 "N/A" ;
VAL_ 2566902049 OptSetArtiBoom 0 "Off" 1 "On" 2 "Error" 3 "N/A" ;
VAL_ 2566902049 OptSetDzBlade 0 "Off" 1 "On" 2 "Error" 3 "N/A" ;
VAL_ 2566902049 OptSetHhLift 0 "Off" 1 "On" 2 "Error" 3 "N/A" ;
VAL_ 2566902049 OptSetTrqCvtLookUp 0 "Off" 1 "On" 2 "Error" 3 "N/A" ;
VAL_ 2566902049 OptSetDhlAuto 0 "Off" 1 "On" 2 "Error" 3 "N/A" ;
VAL_ 2566902049 OptSet3DMG 0 "Off" 1 "On" 2 "Error" 3 "N/A" ;
VAL_ 2566902049 OptSetTrvlSwgAlm 0 "Off" 1 "On" 2 "Error" 3 "N/A" ;
VAL_ 2566902049 OptSetPrsCtrl 0 "Off" 1 "On" 2 "Error" 3 "N/A" ;
VAL_ 2566902049 OptSetRollOvr 0 "Off" 1 "On" 2 "Error" 3 "N/A" ;
VAL_ 2566902049 OptSet4WhlStr 0 "Off" 1 "On" 2 "Error" 3 "N/A" ;
VAL_ 2566902049 OptSetSpool4 0 "Off" 1 "On" 2 "Error" 3 "N/A" ;
VAL_ 2566902049 OptSetConstFw 0 "Off" 1 "On" 2 "Error" 3 "N/A" ;
VAL_ 2566902049 OptSetFrCabLmp 0 "Off" 1 "On" 2 "Error" 3 "N/A" ;
VAL_ 2566902049 OptSetOutRr 0 "Off" 1 "On" 2 "Error" 3 "N/A" ;
VAL_ 2566902049 OptSetOutRlRrDz 0 "Off" 1 "On" 2 "Error" 3 "N/A" ;
VAL_ 2566902049 OptSetOutFr 0 "Off" 1 "On" 2 "Error" 3 "N/A" ;
VAL_ 2566902049 OptSetOutFlFrDz 0 "Off" 1 "On" 2 "Error" 3 "N/A" ;
VAL_ 2566902049 OptSetJoyStr 0 "Off" 1 "On" 2 "Error" 3 "N/A" ;
VAL_ 2566902049 OptSetRvsTrvlSpdLmt 0 "Off" 1 "On" 2 "Error" 3 "N/A" ;
VAL_ 2566902049 OptSetEmcvBoomDnImpactPrevent 0 "Off" 1 "On" 2 "Error" 3 "N/A" ;
VAL_ 2566902049 OptSetEmcvBoomUpImpactPrevent 0 "Off" 1 "On" 2 "Error" 3 "N/A" ;
VAL_ 2566902049 OptSetEmcvBckDumpImpactPrevent 0 "Off" 1 "On" 2 "Error" 3 "N/A" ;
VAL_ 2566902049 OptSetEmcvBckCrowdImpactPrevent 0 "Off" 1 "On" 2 "Error" 3 "N/A" ;
VAL_ 2566902049 OptSetEmcvBckSens 0 "Off" 1 "On" 2 "Error" 3 "N/A" ;
VAL_ 2566902049 OptSetEmcvBoomSens 0 "Off" 1 "On" 2 "Error" 3 "N/A" ;
VAL_ 2566902049 OptSetEstrJoySens 0 "Off" 1 "On" 2 "Error" 3 "N/A" ;
VAL_ 2566902049 OptSetWrkLis 0 "Off" 1 "On" 2 "Error" 3 "N/A" ;
VAL_ 2566902049 OptSetElecStr 0 "Off" 1 "On" 2 "Error" 3 "N/A" ;
VAL_ 2566902049 OptSetRvsFan 0 "Off" 1 "On" 2 "Error" 3 "N/A" ;
VAL_ 2566902049 OptSetRcw 0 "Off" 1 "On" 2 "Error" 3 "N/A" ;
VAL_ 2566902049 OptSetQckCoupler 0 "Off" 1 "On" 2 "Error" 3 "N/A" ;
VAL_ 2566902049 OptSetTrvlOrSwgAlm 0 "Off" 1 "On" 2 "Error" 3 "N/A" ;
VAL_ 2566902049 OptSetSmk 0 "Off" 1 "On" 2 "Error" 3 "N/A" ;
VAL_ 2566902049 OptSetOwd 0 "Off" 1 "On" 2 "Error" 3 "N/A" ;
VAL_ 2566902049 OptSetEmvcPmcv 0 "Off" 1 "On" 2 "Error" 3 "N/A" ;
VAL_ 2566902049 OptSetAebReq 0 "Off" 1 "On" 2 "Error" 3 "N/A" ;
VAL_ 2566902049 OptSetRvsFanOn 0 "Off" 1 "On" 2 "Error" 3 "N/A" ;
VAL_ 2566902049 OptSetRvsFanMd 0 "Off" 1 "On" 2 "Error" 3 "N/A" ;
VAL_ 2566902049 OptSetWhg 0 "Off" 1 "On" 2 "Error" 3 "N/A" ;
VAL_ 2566902049 OptSetHydrostatCalbCmd 0 "Off" 1 "On" 2 "Error" 3 "N/A" ;
VAL_ 2566902049 OptSetClutchCalbCmd 0 "Off" 1 "On" 2 "Error" 3 "N/A" ;
VAL_ 2566902049 OptSetEmgMd 0 "Off" 1 "On" 2 "Error" 3 "N/A" ;
VAL_ 2566902049 OptSetCreepAct 0 "Off" 1 "On" 2 "Error" 3 "N/A" ;
VAL_ 2566902049 OptSetThmbWhl 0 "Off" 1 "On" 2 "Error" 3 "N/A" ;
VAL_ 2566902049 OptSetAxleOilCool 0 "Off" 1 "On" 2 "Error" 3 "N/A" ;
VAL_ 2566902049 OptSetBrkPdlCalb 0 "Off" 1 "On" 2 "Error" 3 "N/A" ;
VAL_ 2566902049 OptSetLis 0 "Off" 1 "On" 2 "Error" 3 "N/A" ;
VAL_ 2566902049 OptSetEmgStr 0 "Off" 1 "On" 2 "Error" 3 "N/A" ;
VAL_ 2566902049 OptSetDhl 0 "Off" 1 "On" 2 "Error" 3 "N/A" ;
VAL_ 2566902049 OptSetFnr2LeverType 0 "Off" 1 "On" 2 "Error" 3 "N/A" ;
VAL_ 2566902049 OptSetTransBck 0 "Off" 1 "On" 2 "Error" 3 "N/A" ;
VAL_ 2566902049 OptSetItgtFltBoom 0 "Off" 1 "On" 2 "Error" 3 "N/A" ;
VAL_ 2566902049 OptSetBeacon 0 "Off" 1 "On" 2 "Error" 3 "N/A" ;
VAL_ 2566902049 OptSetMultiFuncBtnSel 0 "Wiper On" 1 "Smart Boom Cut" 2 "Camera View Mode Change" 3 "Ram Lock  Status Change" 4 "Audio Mute" 5 "Auto Breaker" 6 "Not Defined" 7 "Not Defined" ;
VAL_ 2566902049 OptSetAutoIdle 0 "Off" 1 "On" 2 "Error" 3 "N/A" ;
VAL_ 2566902049 OptSetAutoShutOff 0 "Off" 1 "On" 2 "Error" 3 "N/A" ;
VAL_ 2566902049 OptSetAutoShutOffCancel 0 "Off" 1 "On" 2 "Error" 3 "N/A" ;
VAL_ 2566902049 OptSetAutoIdleRpmTmp 0 "Off" 1 "On" 2 "Error" 3 "N/A" ;
VAL_ 2566902049 OptSetSpc 0 "Off" 1 "On" 2 "Error" 3 "N/A" ;
VAL_ 2566902049 OptSetVoiceWrnCmd 0 "Off" 1 "On" 2 "Error" 3 "N/A" ;
VAL_ 2566902049 OptSetBoomSwgUSe 0 "Off" 1 "On" 2 "Error" 3 "N/A" ;
VAL_ 2566902049 OptSetTrvl2PmpCmbRls 0 "Off" 1 "On" 2 "Error" 3 "N/A" ;
VAL_ 2566902049 OptSetTrvl1PmpUse 0 "Off" 1 "On" 2 "Error" 3 "N/A" ;
VAL_ 2566902049 OptSetTrmsMaxSpdLmtChk 0 "Off" 1 "On" 2 "Error" 3 "N/A" ;
VAL_ 2566902049 OptSetHhAlt 0 "Off" 1 "On" 2 "Error" 3 "N/A" ;
VAL_ 2566902049 OptSetRipperOpt 0 "Off" 1 "On" 2 "Error" 3 "N/A" ;
VAL_ 2566902049 OptSetRttOpt 0 "Off" 1 "On" 2 "Error" 3 "N/A" ;
VAL_ 2566902049 OptSetJoyThmbWhlRtt 0 "Smooth" 1 "Normal" 2 "Fast" 3 "N/A" ;
VAL_ 2566902049 OptSetJoyThmbWhlTw 0 "Smooth" 1 "Normal" 2 "Fast" 3 "N/A" ;
VAL_ 2566902049 OptSetTw 0 "N/A" 1 "Joystick Thumb Wheel" 2 "Option Pedal" 3 "N/A" ;
VAL_ 2566902049 OptSetOptPdl 0 "Hydraulic" 1 "Electronic" ;
VAL_ 2566902049 OptSetAttPdlJoySel 0 "Off" 1 "On" 2 "Error" 3 "N/A" ;
VAL_ 2566902049 OptSet2Pmp 0 "Off" 1 "On" 2 "Error" 3 "N/A" ;
VAL_ 2566902049 OptSetAttTw 0 "Off" 1 "On" 2 "Error" 3 "N/A" ;
VAL_ 2566902049 OptSetAttBrkr 0 "Off" 1 "On" 2 "Error" 3 "N/A" ;
VAL_ 2566902049 OptSetKeylessUse 0 "Off" 1 "On" 2 "Error" 3 "N/A" ;
VAL_ 2566902049 OptSetKeyless 0 "Off" 1 "On" 2 "Error" 3 "N/A" ;
VAL_ 2566902049 OptSetWiper 0 "Off" 1 "On" 2 "Error" 3 "N/A" ;
VAL_ 2566902049 OptSetTrvlMotOvrHtWrn 0 "Off" 1 "On" 2 "Error" 3 "N/A" ;
VAL_ 2566902049 OptSetFnrDefault 0 "Off" 1 "On" 2 "Error" 3 "N/A" ;
VAL_ 2566902049 OptSetFnrSel 0 "Off" 1 "On" 2 "Error" 3 "N/A" ;
VAL_ 2566902049 OptSetCanTypeCmbSw 0 "Off" 1 "On" 2 "Error" 3 "N/A" ;
VAL_ 2566902049 OptSetCanTypeFuelSs 0 "Off" 1 "On" 2 "Error" 3 "N/A" ;
VAL_ 2566902049 OptSetSubBrkLmp 0 "Off" 1 "On" 2 "Error" 3 "N/A" ;
VAL_ 2566902049 TiltRttMd 0 "Off" 1 "On" 2 "Error" 3 "N/A" ;
VAL_ 2566902049 USerLckUnlockSt 0 "Off" 1 "On" 2 "Error" 3 "N/A" ;
VAL_ 2566902049 OptWgh 0 "Off" 1 "On" 2 "Error" 3 "N/A" ;
VAL_ 2566902049 OptMC 0 "Off" 1 "On" 2 "Error" 3 "N/A" ;
VAL_ 2566902049 OptEgPostHtAct 0 "Off" 1 "On" 2 "Error" 3 "N/A" ;
VAL_ 2566902049 Opt2DMG 0 "Off" 1 "On" 2 "Error" 3 "N/A" ;
VAL_ 2566902049 AdminUse2 0 "None" 1 "Ignition Lock" 2 "Attachment" 4 "Entertainment Restrict" ;
VAL_ 2566902049 AdminUse1 0 "None" 1 "Ignition Lock" 2 "Attachment" 4 "Entertainment Restrict" ;
VAL_ 2566902049 AdminUse0 0 "None" 1 "Ignition Lock" 2 "Attachment" 4 "Entertainment Restrict" ;
VAL_ 2566902049 OwnerPw0UpTm 0 "Always" 1 "1 min" 2 "5 min" 3 "N/A" ;
VAL_ 2566903329 MainStRpmpPrsSw 0 "Off" 1 "On" 2 "Error" 3 "N/A" ;
VAL_ 2566903329 GndSawInitSw 0 "Off" 1 "On" 2 "Error" 3 "N/A" ;
VAL_ 2566903329 FanErrSig 0 "Off" 1 "On" 2 "Error" 3 "N/A" ;
VAL_ 2566903329 HydWakeUpSw 0 "Off" 1 "On" 2 "Error" 3 "N/A" ;
VAL_ 2566903329 EmgStpSw 0 "Off" 1 "On" 2 "Error" 3 "N/A" ;
VAL_ 2566903329 HhVltChgSw 0 "Off" 1 "On" 2 "Error" 3 "N/A" ;
VAL_ 2566903329 PrkBrkPrsSw 0 "Off" 1 "On" 2 "Error" 3 "N/A" ;
VAL_ 2566903329 RamLckRvsSw 0 "Off" 1 "On" 2 "Error" 3 "N/A" ;
VAL_ 2566903329 AirCompPrsSw 0 "Off" 1 "On" 2 "Error" 3 "N/A" ;
VAL_ 2566903329 Mg2DJoyTrigSw 0 "Off" 1 "On" 2 "Error" 3 "N/A" ;
VAL_ 2566903329 KeySwBr 0 "Off" 1 "On" 2 "Error" 3 "N/A" ;
VAL_ 2566903329 TwSwSelSw 0 "Off" 1 "On" 2 "Error" 3 "N/A" ;
VAL_ 2566903329 DzOutSw 0 "Off" 1 "On" 2 "Error" 3 "N/A" ;
VAL_ 2566903329 MrrHtSw 0 "Off" 1 "On" 2 "Error" 3 "N/A" ;
VAL_ 2566903329 SwgAlignSw 0 "Off" 1 "On" 2 "Error" 3 "N/A" ;
VAL_ 2566903329 MultiFuncSw 0 "Off" 1 "On" 2 "Error" 3 "N/A" ;
VAL_ 2566903329 AutoDigSw 0 "Off" 1 "On" 2 "Error" 3 "N/A" ;
VAL_ 2566903329 TrvlPmpHhSpdSw 0 "Off" 1 "On" 2 "Error" 3 "N/A" ;
VAL_ 2566903329 DoorSw 0 "Off" 1 "On" 2 "Error" 3 "N/A" ;
VAL_ 2566903329 RrAxleRhHallSsSw 0 "Off" 1 "On" 2 "Error" 3 "N/A" ;
VAL_ 2566903329 RrAxleLhHallSsSw 0 "Off" 1 "On" 2 "Error" 3 "N/A" ;
VAL_ 2566903329 FrAxleHallSsSw 0 "Off" 1 "On" 2 "Error" 3 "N/A" ;
VAL_ 2566903329 QckCouplerRhSw 0 "Off" 1 "On" 2 "Error" 3 "N/A" ;
VAL_ 2566903329 QckCouplerLhSw 0 "Off" 1 "On" 2 "Error" 3 "N/A" ;
VAL_ 2566903329 PowMdSw 0 "Off" 1 "On" 2 "Error" 3 "N/A" ;
VAL_ 2566903329 WrkMdSw 0 "Off" 1 "On" 2 "Error" 3 "N/A" ;
VAL_ 2566903329 AuxMdSelSw 0 "Off" 1 "On" 2 "Error" 3 "N/A" ;
VAL_ 2566903329 SwgBrkRlsSw 0 "Off" 1 "On" 2 "Error" 3 "N/A" ;
VAL_ 2566903329 BrkrFltSw 0 "Off" 1 "On" 2 "Error" 3 "N/A" ;
VAL_ 2566903329 SwgPriSw 0 "Off" 1 "On" 2 "Error" 3 "N/A" ;
VAL_ 2566903329 RttCwSw 0 "Off" 1 "On" 2 "Error" 3 "N/A" ;
VAL_ 2566903329 RttCcwSw 0 "Off" 1 "On" 2 "Error" 3 "N/A" ;
VAL_ 2566903329 WiperWasherSw 0 "Off" 1 "On" 2 "Error" 3 "N/A" ;
VAL_ 2566903329 WiperContSw 0 "Off" 1 "On" 2 "Error" 3 "N/A" ;
VAL_ 2566903329 Wiper2StepSw 0 "Off" 1 "On" 2 "Error" 3 "N/A" ;
VAL_ 2566903329 Wiper1StepSw 0 "Off" 1 "On" 2 "Error" 3 "N/A" ;
VAL_ 2566903329 TmsSt 0 "Off" 1 "On" 2 "Error" 3 "N/A" ;
VAL_ 2566903329 ArtiBoomPrsSw 0 "Off" 1 "On" 2 "Error" 3 "N/A" ;
VAL_ 2566903329 CoolLvSw 0 "Off" 1 "On" 2 "Error" 3 "N/A" ;
VAL_ 2566903329 RttOprSw 0 "Off" 1 "On" 2 "Error" 3 "N/A" ;
VAL_ 2566903329 TwCloseOprSw 0 "Off" 1 "On" 2 "Error" 3 "N/A" ;
VAL_ 2566903329 TwOpenOprSw 0 "Off" 1 "On" 2 "Error" 3 "N/A" ;
VAL_ 2566903329 RcwCloseSw 0 "Off" 1 "On" 2 "Error" 3 "N/A" ;
VAL_ 2566903329 RcwOprSw 0 "Off" 1 "On" 2 "Error" 3 "N/A" ;
VAL_ 2566903329 EmgEgStpSw 0 "Off" 1 "On" 2 "Error" 3 "N/A" ;
VAL_ 2566903329 OwOptPdlPrsSw 0 "Off" 1 "On" 2 "Error" 3 "N/A" ;
VAL_ 2566903329 SpcSw 0 "Off" 1 "On" 2 "Error" 3 "N/A" ;
VAL_ 2566903329 IhbSw 0 "Off" 1 "On" 2 "Error" 3 "N/A" ;
VAL_ 2566903329 TrvlAlmSelSw 0 "Off" 1 "On" 2 "Error" 3 "N/A" ;
VAL_ 2566903329 SwgAlmSelSw 0 "Off" 1 "On" 2 "Error" 3 "N/A" ;
VAL_ 2566903329 EmgStrSw 0 "Off" 1 "On" 2 "Error" 3 "N/A" ;
VAL_ 2566903329 HhBeamSw 0 "Off" 1 "On" 2 "Error" 3 "N/A" ;
VAL_ 2566903329 StpLmp 0 "Off" 1 "On" 2 "Error" 3 "N/A" ;
VAL_ 2566903329 AccPdlSw 0 "Off" 1 "On" 2 "Error" 3 "N/A" ;
VAL_ 2566903329 BrkPrsSw 0 "Off" 1 "On" 2 "Error" 3 "N/A" ;
VAL_ 2566903329 Cruise 0 "Off" 1 "On" 2 "Error" 3 "N/A" ;
VAL_ 2566903329 EgOilPrsSw 0 "Off" 1 "On" 2 "Error" 3 "N/A" ;
VAL_ 2566903329 WrkPxPrsSw 0 "Off" 1 "On" 2 "Error" 3 "N/A" ;
VAL_ 2566903329 TrvlPyPrsSw 0 "Off" 1 "On" 2 "Error" 3 "N/A" ;
VAL_ 2566903329 IgnSw 0 "Off" 1 "On" 2 "Error" 3 "N/A" ;
VAL_ 2566903329 RamLckAutoSw 0 "Off" 1 "On" 2 "Error" 3 "N/A" ;
VAL_ 2566903329 PreHt 0 "Off" 1 "On" 2 "Error" 3 "N/A" ;
VAL_ 2566903329 WifWrn 0 "Off" 1 "On" 2 "Error" 3 "N/A" ;
VAL_ 2566903329 SwgPrsSw 0 "Off" 1 "On" 2 "Error" 3 "N/A" ;
VAL_ 2566903329 JoyPtnBhl 0 "Off" 1 "On" 2 "Error" 3 "N/A" ;
VAL_ 2566903329 JoyPtnIso 0 "Off" 1 "On" 2 "Error" 3 "N/A" ;
VAL_ 2566903329 RvsFanSw 0 "Off" 1 "On" 2 "Error" 3 "N/A" ;
VAL_ 2566903329 TwOptPdlPrsSw 0 "Off" 1 "On" 2 "Error" 3 "N/A" ;
VAL_ 2566903329 BrkOilPrsWrn 0 "Off" 1 "On" 2 "Error" 3 "N/A" ;
VAL_ 2566903329 OwdWrnSelSw 0 "Off" 1 "On" 2 "Error" 3 "N/A" ;
VAL_ 2566903329 RetFiltWrn 0 "Off" 1 "On" 2 "Error" 3 "N/A" ;
VAL_ 2566903329 PilotFiltWrn 0 "Off" 1 "On" 2 "Error" 3 "N/A" ;
VAL_ 2566903329 AirCleanerWrn 0 "Off" 1 "On" 2 "Error" 3 "N/A" ;
VAL_ 2566903329 PilotCutOffSw 0 "Off" 1 "On" 2 "Error" 3 "N/A" ;
VAL_ 2566903329 ItgtBoomSw 0 "Off" 1 "On" 2 "Error" 3 "N/A" ;
VAL_ 2566903329 OneTouchRedSpdSw 0 "Off" 1 "On" 2 "Error" 3 "N/A" ;
VAL_ 2566903329 RamLckSw 0 "Off" 1 "On" 2 "Error" 3 "N/A" ;
VAL_ 2566903329 PrkSw 0 "Off" 1 "On" 2 "Error" 3 "N/A" ;
VAL_ 2566903329 AirCndSw 0 "Off" 1 "On" 2 "Error" 3 "N/A" ;
VAL_ 2566903329 JoyDirSelSw 0 "Off" 1 "On" 2 "Error" 3 "N/A" ;
VAL_ 2566903329 TrvlBwdSw 0 "Off" 1 "On" 2 "Error" 3 "N/A" ;
VAL_ 2566903329 TrvlNtrlSw 0 "Off" 1 "On" 2 "Error" 3 "N/A" ;
VAL_ 2566903329 TrvlFwdSw 0 "Off" 1 "On" 2 "Error" 3 "N/A" ;
VAL_ 2566903329 HhSpdSelSw 0 "Off" 1 "On" 2 "Error" 3 "N/A" ;
VAL_ 2566903329 LwSpdSelSw 0 "Off" 1 "On" 2 "Error" 3 "N/A" ;
VAL_ 2566903329 InchingSelSw 0 "Off" 1 "On" 2 "Error" 3 "N/A" ;
VAL_ 2566903329 QckCoupler 0 "Off" 1 "On" 2 "Error" 3 "N/A" ;
VAL_ 2566903329 TwSelSw 0 "Off" 1 "On" 2 "Error" 3 "N/A" ;
VAL_ 2566903329 OnwWaySelSw 0 "Off" 1 "On" 2 "Error" 3 "N/A" ;
VAL_ 2566903329 WrkLmpSw 0 "Off" 1 "On" 2 "Error" 3 "N/A" ;
VAL_ 2566903329 AutoTrvl2SpdSw 0 "Off" 1 "On" 2 "Error" 3 "N/A" ;
VAL_ 2566903329 Trvl2SpdSelSw 0 "Off" 1 "On" 2 "Error" 3 "N/A" ;
VAL_ 2566903329 TrvlSelSw 0 "Off" 1 "On" 2 "Error" 3 "N/A" ;
VAL_ 2566903329 BrkrSw 0 "Off" 1 "On" 2 "Error" 3 "N/A" ;
VAL_ 2566903329 PwrMaxSw 0 "Off" 1 "On" 2 "Error" 3 "N/A" ;
VAL_ 2566903329 Alt 0 "Off" 1 "On" 2 "Error" 3 "N/A" ;
VAL_ 2566903585 HvChgSig 0 "Off" 1 "On" 2 "Error" 3 "N/A" ;
VAL_ 2566903585 FanPwmSig 0 "Off" 1 "On" 2 "Error" 3 "N/A" ;
VAL_ 2566903585 TrkExpationSv 0 "Off" 1 "On" 2 "Error" 3 "N/A" ;
VAL_ 2566903585 HhVltMainRly 0 "Off" 1 "On" 2 "Error" 3 "N/A" ;
VAL_ 2566903585 HhVltPreChgRly 0 "Off" 1 "On" 2 "Error" 3 "N/A" ;
VAL_ 2566903585 PilotBz 0 "Off" 1 "On" 2 "Error" 3 "N/A" ;
VAL_ 2566903585 QckChgInd 0 "Off" 1 "On" 2 "Error" 3 "N/A" ;
VAL_ 2566903585 QckChgRly 0 "Off" 1 "On" 2 "Error" 3 "N/A" ;
VAL_ 2566903585 NormChgInd 0 "Off" 1 "On" 2 "Error" 3 "N/A" ;
VAL_ 2566903585 LwVltMainRly 0 "Off" 1 "On" 2 "Error" 3 "N/A" ;
VAL_ 2566903585 BoomSwgSelRly 0 "Off" 1 "On" 2 "Error" 3 "N/A" ;
VAL_ 2566903585 PmpDeratSv 0 "Off" 1 "On" 2 "Error" 3 "N/A" ;
VAL_ 2566903585 PrkBrkRly 0 "Off" 1 "On" 2 "Error" 3 "N/A" ;
VAL_ 2566903585 RvsLmpRly 0 "Off" 1 "On" 2 "Error" 3 "N/A" ;
VAL_ 2566903585 AirCompRly 0 "Off" 1 "On" 2 "Error" 3 "N/A" ;
VAL_ 2566903585 CabLmpRly 0 "Off" 1 "On" 2 "Error" 3 "N/A" ;
VAL_ 2566903585 AvmWrnSig 0 "Off" 1 "On" 2 "Error" 3 "N/A" ;
VAL_ 2566903585 WrkLmpRly 0 "Off" 1 "On" 2 "Error" 3 "N/A" ;
VAL_ 2566903585 AirCondCompStpSig 0 "Off" 1 "On" 2 "Error" 3 "N/A" ;
VAL_ 2566903585 Chmsl 0 "Off" 1 "On" 2 "Error" 3 "N/A" ;
VAL_ 2566903585 BoomSusRodSv 0 "Off" 1 "On" 2 "Error" 3 "N/A" ;
VAL_ 2566903585 BoomSusHedSv 0 "Off" 1 "On" 2 "Error" 3 "N/A" ;
VAL_ 2566903585 MrrHt 0 "Off" 1 "On" 2 "Error" 3 "N/A" ;
VAL_ 2566903585 ClearLmp 0 "Off" 1 "On" 2 "Error" 3 "N/A" ;
VAL_ 2566903585 HhHeadLmp 0 "Off" 1 "On" 2 "Error" 3 "N/A" ;
VAL_ 2566903585 LwHeadLmp 0 "Off" 1 "On" 2 "Error" 3 "N/A" ;
VAL_ 2566903585 FineSwgSv 0 "Off" 1 "On" 2 "Error" 3 "N/A" ;
VAL_ 2566903585 TurnRhSigLmp 0 "Off" 1 "On" 2 "Error" 3 "N/A" ;
VAL_ 2566903585 TurnLhSigLmp 0 "Off" 1 "On" 2 "Error" 3 "N/A" ;
VAL_ 2566903585 BeaconRly 0 "Off" 1 "On" 2 "Error" 3 "N/A" ;
VAL_ 2566903585 LightRly 0 "Off" 1 "On" 2 "Error" 3 "N/A" ;
VAL_ 2566903585 LmpRly 0 "Off" 1 "On" 2 "Error" 3 "N/A" ;
VAL_ 2566903585 RamLckSv 0 "Off" 1 "On" 2 "Error" 3 "N/A" ;
VAL_ 2566903585 LwSpdTrvlSv 0 "Off" 1 "On" 2 "Error" 3 "N/A" ;
VAL_ 2566903585 TrvlPmpHhSpd2Sv 0 "Off" 1 "On" 2 "Error" 3 "N/A" ;
VAL_ 2566903585 TrvlPmpHhSpd1Sv 0 "Off" 1 "On" 2 "Error" 3 "N/A" ;
VAL_ 2566903585 WiperWasherRly 0 "Off" 1 "On" 2 "Error" 3 "N/A" ;
VAL_ 2566903585 WiperRly 0 "Off" 1 "On" 2 "Error" 3 "N/A" ;
VAL_ 2566903585 AutoShutOffRly 0 "Off" 1 "On" 2 "Error" 3 "N/A" ;
VAL_ 2566903585 AirHtRly 0 "Off" 1 "On" 2 "Error" 3 "N/A" ;
VAL_ 2566903585 GlowPlugPreHhRly2 0 "Off" 1 "On" 2 "Error" 3 "N/A" ;
VAL_ 2566903585 GlowPlugPreHhRly1 0 "Off" 1 "On" 2 "Error" 3 "N/A" ;
VAL_ 2566903585 HhSpdRly 0 "Off" 1 "On" 2 "Error" 3 "N/A" ;
VAL_ 2566903585 LwSpdRly 0 "Off" 1 "On" 2 "Error" 3 "N/A" ;
VAL_ 2566903585 InchingRly 0 "Off" 1 "On" 2 "Error" 3 "N/A" ;
VAL_ 2566903585 SpareRly 0 "Off" 1 "On" 2 "Error" 3 "N/A" ;
VAL_ 2566903585 BackBzRly 0 "Off" 1 "On" 2 "Error" 3 "N/A" ;
VAL_ 2566903585 StartRly 0 "Off" 1 "On" 2 "Error" 3 "N/A" ;
VAL_ 2566903585 AutoBrkSv 0 "Off" 1 "On" 2 "Error" 3 "N/A" ;
VAL_ 2566903585 PilotCutOffSv 0 "Off" 1 "On" 2 "Error" 3 "N/A" ;
VAL_ 2566903585 McvEpprCutOffSv 0 "Off" 1 "On" 2 "Error" 3 "N/A" ;
VAL_ 2566903585 BsSpoolSc 0 "Off" 1 "On" 2 "Error" 3 "N/A" ;
VAL_ 2566903585 QckCouplerSv 0 "Off" 1 "On" 2 "Error" 3 "N/A" ;
VAL_ 2566903585 FreeBoomDnSv 0 "Off" 1 "On" 2 "Error" 3 "N/A" ;
VAL_ 2566903585 FreeBoomUpSv 0 "Off" 1 "On" 2 "Error" 3 "N/A" ;
VAL_ 2566903585 TrvlStrgtSv 0 "Off" 1 "On" 2 "Error" 3 "N/A" ;
VAL_ 2566903585 RttCcwSv 0 "Off" 1 "On" 2 "Error" 3 "N/A" ;
VAL_ 2566903585 RttCwSv 0 "Off" 1 "On" 2 "Error" 3 "N/A" ;
VAL_ 2566903585 Trvl2PmpCmbSv 0 "Off" 1 "On" 2 "Error" 3 "N/A" ;
VAL_ 2566903585 OptPdlSaftySv 0 "Off" 1 "On" 2 "Error" 3 "N/A" ;
VAL_ 2566903585 ForceRgnSv 0 "Off" 1 "On" 2 "Error" 3 "N/A" ;
VAL_ 2566903585 TwOprSv 0 "Off" 1 "On" 2 "Error" 3 "N/A" ;
VAL_ 2566903585 UnloadSv 0 "Off" 1 "On" 2 "Error" 3 "N/A" ;
VAL_ 2566903585 TwRhCloseSv 0 "Off" 1 "On" 2 "Error" 3 "N/A" ;
VAL_ 2566903585 TwRhOpenSv 0 "Off" 1 "On" 2 "Error" 3 "N/A" ;
VAL_ 2566903585 SwgBrkRelSv 0 "Off" 1 "On" 2 "Error" 3 "N/A" ;
VAL_ 2566903585 BypassCutOffSv 0 "Off" 1 "On" 2 "Error" 3 "N/A" ;
VAL_ 2566903585 RwdSv 0 "Off" 1 "On" 2 "Error" 3 "N/A" ;
VAL_ 2566903585 FwdSv 0 "Off" 1 "On" 2 "Error" 3 "N/A" ;
VAL_ 2566903585 CruiseSv 0 "Off" 1 "On" 2 "Error" 3 "N/A" ;
VAL_ 2566903585 TwoPmpSelSv 0 "Off" 1 "On" 2 "Error" 3 "N/A" ;
VAL_ 2566903585 FanRvsSv 0 "Off" 1 "On" 2 "Error" 3 "N/A" ;
VAL_ 2566903585 BrkrSelSv 0 "Off" 1 "On" 2 "Error" 3 "N/A" ;
VAL_ 2566903585 HhSpdTrvlSv 0 "Off" 1 "On" 2 "Error" 3 "N/A" ;
VAL_ 2566903585 PowMaxSv 0 "Off" 1 "On" 2 "Error" 3 "N/A" ;
VAL_ 2566903585 BrkrOprSv 0 "Off" 1 "On" 2 "Error" 3 "N/A" ;
VAL_ 2566904353 OpsSw 0 "Off" 1 "On" 2 "Error" 3 "N/A" ;
VAL_ 2566904353 HhFlowPinK 0 "Off" 1 "On" 2 "Error" 3 "N/A" ;
VAL_ 2566904353 HhFlowPinN 0 "Off" 1 "On" 2 "Error" 3 "N/A" ;
VAL_ 2566904353 DustInd 0 "Off" 1 "On" 2 "Error" 3 "N/A" ;
VAL_ 2566904353 FrDoorSw 0 "Off" 1 "On" 2 "Error" 3 "N/A" ;
VAL_ 2566904353 ArmRestLhSw 0 "Off" 1 "On" 2 "Error" 3 "N/A" ;
VAL_ 2566904353 ArmRestRhSw 0 "Off" 1 "On" 2 "Error" 3 "N/A" ;
VAL_ 2566904353 Spool3LeverSw 0 "Off" 1 "On" 2 "Error" 3 "N/A" ;
VAL_ 2566904353 BckLeverSw 0 "Off" 1 "On" 2 "Error" 3 "N/A" ;
VAL_ 2566904353 EgOilPrsSw 0 "Off" 1 "On" 2 "Error" 3 "N/A" ;
VAL_ 2566904353 HydLckoutSw 0 "Off" 1 "On" 2 "Error" 3 "N/A" ;
VAL_ 2566904353 TractionCtrlSw 0 "Off" 1 "On" 2 "Error" 3 "N/A" ;
VAL_ 2566904353 AirCleanSw 0 "Off" 1 "On" 2 "Error" 3 "N/A" ;
VAL_ 2566904353 RetFiltSw 0 "Off" 1 "On" 2 "Error" 3 "N/A" ;
VAL_ 2566904353 QckCouperLckSw 0 "Off" 1 "On" 2 "Error" 3 "N/A" ;
VAL_ 2566904353 DnShftSw 0 "Off" 1 "On" 2 "Error" 3 "N/A" ;
VAL_ 2566904353 PreHt 0 "Off" 1 "On" 2 "Error" 3 "N/A" ;
VAL_ 2566904353 Joy1XDetentPosSt 0 "Off" 1 "On" 2 "Error" 3 "N/A" ;
VAL_ 2566904353 Joy1YDetentPosSt 0 "Off" 1 "On" 2 "Error" 3 "N/A" ;
VAL_ 2566904353 IhbSw 0 "Off" 1 "On" 2 "Error" 3 "N/A" ;
VAL_ 2566904353 HstOilFiltWrn 0 "Off" 1 "On" 2 "Error" 3 "N/A" ;
VAL_ 2566904353 GrboxOvrTmp 0 "Off" 1 "On" 2 "Error" 3 "N/A" ;
VAL_ 2566904353 AgsLmp 0 "Off" 1 "On" 2 "Error" 3 "N/A" ;
VAL_ 2566904353 QckCouplerInitSw 0 "Off" 1 "On" 2 "Error" 3 "N/A" ;
VAL_ 2566904353 PrkSw 0 "Off" 1 "On" 2 "Error" 3 "N/A" ;
VAL_ 2566904353 SeatBeltSw 0 "Off" 1 "On" 2 "Error" 3 "N/A" ;
VAL_ 2566904353 ReDefrstSw 0 "Off" 1 "On" 2 "Error" 3 "N/A" ;
VAL_ 2566904353 HormSw 0 "Off" 1 "On" 2 "Error" 3 "N/A" ;
VAL_ 2566904353 Fnr2ActSw 0 "Off" 1 "On" 2 "Error" 3 "N/A" ;
VAL_ 2566904353 RearWiperStpSw 0 "Off" 1 "On" 2 "Error" 3 "N/A" ;
VAL_ 2566904353 FrWiperStpSig 0 "Off" 1 "On" 2 "Error" 3 "N/A" ;
VAL_ 2566904353 DpfForceRgnSw 0 "Off" 1 "On" 2 "Error" 3 "N/A" ;
VAL_ 2566904353 EmgStrPrsSw 0 "Off" 1 "On" 2 "Error" 3 "N/A" ;
VAL_ 2566904353 MainStrPrsSw 0 "Off" 1 "On" 2 "Error" 3 "N/A" ;
VAL_ 2566904353 AccPdlKd 0 "Off" 1 "On" 2 "Error" 3 "N/A" ;
VAL_ 2566904353 AccPdlIvs 0 "Off" 1 "On" 2 "Error" 3 "N/A" ;
VAL_ 2566904353 PrkBrkPrsSw 0 "Off" 1 "On" 2 "Error" 3 "N/A" ;
VAL_ 2566904353 CoolLv 0 "Off" 1 "On" 2 "Error" 3 "N/A" ;
VAL_ 2566904353 WghCntSw 0 "Off" 1 "On" 2 "Error" 3 "N/A" ;
VAL_ 2566904353 EmgStpSw 0 "Off" 1 "On" 2 "Error" 3 "N/A" ;
VAL_ 2566904353 DhlManSw 0 "Off" 1 "On" 2 "Error" 3 "N/A" ;
VAL_ 2566904353 FnrR3 0 "Off" 1 "On" 2 "Error" 3 "N/A" ;
VAL_ 2566904353 FnrN3 0 "Off" 1 "On" 2 "Error" 3 "N/A" ;
VAL_ 2566904353 FnrF3 0 "Off" 1 "On" 2 "Error" 3 "N/A" ;
VAL_ 2566904353 FnrR2 0 "Off" 1 "On" 2 "Error" 3 "N/A" ;
VAL_ 2566904353 FnrN2 0 "Off" 1 "On" 2 "Error" 3 "N/A" ;
VAL_ 2566904353 FnrF2 0 "Off" 1 "On" 2 "Error" 3 "N/A" ;
VAL_ 2566904353 FnrR1 0 "Off" 1 "On" 2 "Error" 3 "N/A" ;
VAL_ 2566904353 FnrN1 0 "Off" 1 "On" 2 "Error" 3 "N/A" ;
VAL_ 2566904353 FnrF1 0 "Off" 1 "On" 2 "Error" 3 "N/A" ;
VAL_ 2566904353 StartBrSw 0 "Off" 1 "On" 2 "Error" 3 "N/A" ;
VAL_ 2566904353 StartAccSw 0 "Off" 1 "On" 2 "Error" 3 "N/A" ;
VAL_ 2566904353 StartCSw 0 "Off" 1 "On" 2 "Error" 3 "N/A" ;
VAL_ 2566904353 PilotCutOffSw 0 "Off" 1 "On" 2 "Error" 3 "N/A" ;
VAL_ 2566904353 ArmRestCutOffSw 0 "Off" 1 "On" 2 "Error" 3 "N/A" ;
VAL_ 2566904353 ElecStrSelSw 0 "Off" 1 "On" 2 "Error" 3 "N/A" ;
VAL_ 2566904609 Aux8Rly 0 "Off" 1 "On" 2 "Error" 3 "N/A" ;
VAL_ 2566904609 Aux7Rly 0 "Off" 1 "On" 2 "Error" 3 "N/A" ;
VAL_ 2566904609 Aux6Rly 0 "Off" 1 "On" 2 "Error" 3 "N/A" ;
VAL_ 2566904609 Aux5Rly 0 "Off" 1 "On" 2 "Error" 3 "N/A" ;
VAL_ 2566904609 Aux4Rly 0 "Off" 1 "On" 2 "Error" 3 "N/A" ;
VAL_ 2566904609 Aux3Rly 0 "Off" 1 "On" 2 "Error" 3 "N/A" ;
VAL_ 2566904609 AuxShutOffSv 0 "Off" 1 "On" 2 "Error" 3 "N/A" ;
VAL_ 2566904609 PilotCutOffSv 0 "Off" 1 "On" 2 "Error" 3 "N/A" ;
VAL_ 2566904609 FrWiperRly 0 "Off" 1 "On" 2 "Error" 3 "N/A" ;
VAL_ 2566904609 SideWasherRly 0 "Off" 1 "On" 2 "Error" 3 "N/A" ;
VAL_ 2566904609 UreaSuperChgWrnSig 0 "Off" 1 "On" 2 "Error" 3 "N/A" ;
VAL_ 2566904609 EgRunOutSig 0 "Off" 1 "On" 2 "Error" 3 "N/A" ;
VAL_ 2566904609 SideWiperRly 0 "Off" 1 "On" 2 "Error" 3 "N/A" ;
VAL_ 2566904609 FrWhaserRly 0 "Off" 1 "On" 2 "Error" 3 "N/A" ;
VAL_ 2566904609 FrWiperLwSigRly 0 "Off" 1 "On" 2 "Error" 3 "N/A" ;
VAL_ 2566904609 FrWiperHhSpdRly 0 "Off" 1 "On" 2 "Error" 3 "N/A" ;
VAL_ 2566904609 LwBeamRly 0 "Off" 1 "On" 2 "Error" 3 "N/A" ;
VAL_ 2566904609 HhBeamRly 0 "Off" 1 "On" 2 "Error" 3 "N/A" ;
VAL_ 2566904609 IllmLmpRly 0 "Off" 1 "On" 2 "Error" 3 "N/A" ;
VAL_ 2566904609 RttBeaconRly 0 "Off" 1 "On" 2 "Error" 3 "N/A" ;
VAL_ 2566904609 TurnSigRhRly 0 "Off" 1 "On" 2 "Error" 3 "N/A" ;
VAL_ 2566904609 TurnSigLhRly 0 "Off" 1 "On" 2 "Error" 3 "N/A" ;
VAL_ 2566904609 HormRly 0 "Off" 1 "On" 2 "Error" 3 "N/A" ;
VAL_ 2566904609 AccRly 0 "Off" 1 "On" 2 "Error" 3 "N/A" ;
VAL_ 2566904609 RrWinHtRly 0 "Off" 1 "On" 2 "Error" 3 "N/A" ;
VAL_ 2566904609 AutoShutOffRly 0 "Off" 1 "On" 2 "Error" 3 "N/A" ;
VAL_ 2566904609 BackUpBzRly 0 "Off" 1 "On" 2 "Error" 3 "N/A" ;
VAL_ 2566904609 MrrHtRly 0 "Off" 1 "On" 2 "Error" 3 "N/A" ;
VAL_ 2566904609 HuelHtRly 0 "Off" 1 "On" 2 "Error" 3 "N/A" ;
VAL_ 2566904609 GlowPlugFuelRly 0 "Off" 1 "On" 2 "Error" 3 "N/A" ;
VAL_ 2566904609 GlowPlugRly 0 "Off" 1 "On" 2 "Error" 3 "N/A" ;
VAL_ 2566904609 EmgStrTestRly 0 "Off" 1 "On" 2 "Error" 3 "N/A" ;
VAL_ 2566904609 RrWasherRly 0 "Off" 1 "On" 2 "Error" 3 "N/A" ;
VAL_ 2566904609 RrWiperRly 0 "Off" 1 "On" 2 "Error" 3 "N/A" ;
VAL_ 2566904609 RrWrkCabLmpRly 0 "Off" 1 "On" 2 "Error" 3 "N/A" ;
VAL_ 2566904609 RrWrkRadLmpRly 0 "Off" 1 "On" 2 "Error" 3 "N/A" ;
VAL_ 2566904609 FrWrkLmpRly 0 "Off" 1 "On" 2 "Error" 3 "N/A" ;
VAL_ 2566904609 ElecStrSaftyRly 0 "Off" 1 "On" 2 "Error" 3 "N/A" ;
VAL_ 2566904609 PilotBzRly 0 "Off" 1 "On" 2 "Error" 3 "N/A" ;
VAL_ 2566904609 LisActRly 0 "Off" 1 "On" 2 "Error" 3 "N/A" ;
VAL_ 2566904609 HstCutOffRhSv 0 "Off" 1 "On" 2 "Error" 3 "N/A" ;
VAL_ 2566904609 HstCutOffLhSv 0 "Off" 1 "On" 2 "Error" 3 "N/A" ;
VAL_ 2566904609 BckMagnet 0 "Off" 1 "On" 2 "Error" 3 "N/A" ;
VAL_ 2566904609 BoomMagnet 0 "Off" 1 "On" 2 "Error" 3 "N/A" ;
VAL_ 2566904609 HstCutOffSv 0 "Off" 1 "On" 2 "Error" 3 "N/A" ;
VAL_ 2566904609 HydCutOffSv 0 "Off" 1 "On" 2 "Error" 3 "N/A" ;
VAL_ 2566904609 StartRly 0 "Off" 1 "On" 2 "Error" 3 "N/A" ;
VAL_ 2566904609 QckCouplerRly 0 "Off" 1 "On" 2 "Error" 3 "N/A" ;
VAL_ 2566904609 EgStpRly 0 "Off" 1 "On" 2 "Error" 3 "N/A" ;
VAL_ 2566904609 PrkBrkRlsSv 0 "Off" 1 "On" 2 "Error" 3 "N/A" ;
VAL_ 2566904609 EscortWrkLmpRly 0 "Off" 1 "On" 2 "Error" 3 "N/A" ;
VAL_ 2566904609 AxleOilCoolSv 0 "Off" 1 "On" 2 "Error" 3 "N/A" ;
VAL_ 2566904609 UnloadSv 0 "Off" 1 "On" 2 "Error" 3 "N/A" ;
VAL_ 2566904609 BrkChgSv 0 "Off" 1 "On" 2 "Error" 3 "N/A" ;
VAL_ 2566904609 RvsFanSV 0 "Off" 1 "On" 2 "Error" 3 "N/A" ;
